VERSION ""

NS_ :

BS_:

BU_: MPC
VAL_TABLE_ Vt_The_Drv_Demand_Trq_Sign_S 1 "Driver Override" 0 "No Override" ;
VAL_TABLE_ Sun_Sensor_Hardware_Fault_S 1 "有故障" 0 "无故障" ;
VAL_TABLE_ Humidity_Sensor_Fault_Sign_S 1 "有故障" 0 "无故障" ;
VAL_TABLE_ Left_Front_Door_Status_294_S 3 "预留" 2 "打开" 1 "关闭" 0 "无效" ;
VAL_TABLE_ Right_Front_Door_Status_294_S 3 "预留" 2 "打开" 1 "关闭" 0 "无效" ;
VAL_TABLE_ Left_Back_Door_Status_294_S 3 "预留" 2 "打开" 1 "关闭" 0 "无效" ;
VAL_TABLE_ Right_Back_Door_Status_294_S 3 "预留" 2 "打开" 1 "关闭" 0 "无效" ;
VAL_TABLE_ LeftF_Door_Stats_Valid_Bit_S 1 "无效" 0 "有效" ;
VAL_TABLE_ RightF_Door_Sts_Valid_Bit_294_S 1 "无效" 0 "有效" ;
VAL_TABLE_ LeftR_Door_Stats_Valid_Bit_S 1 "无效" 0 "有效" ;
VAL_TABLE_ RightR_Door_Sts_Valid_Bit_294_S 1 "无效" 0 "有效" ;
VAL_TABLE_ Driver_Belt_Stat_Effective_Bit_S 1 "无效" 0 "有效" ;
VAL_TABLE_ Back_Door_Sts_Effectiv_Bit_294_S 1 "无效" 0 "有效" ;
VAL_TABLE_ Frnt_Hatch_Stat_Effective_Bit_S 1 "无效" 0 "有效" ;
VAL_TABLE_ Emergency_Alarm_Effective_Bit_S 1 "无效" 0 "有效" ;
VAL_TABLE_ Driver_Belt_Status_S 3 "预留" 2 "扣上" 1 "解开" 0 "无效" ;
VAL_TABLE_ Back_Door_Status_294_S 3 "预留" 2 "打开" 1 "关闭" 0 "无效" ;
VAL_TABLE_ Former_Hatch_Status_294_S 3 "预留" 2 "打开" 1 "关闭" 0 "无效" ;
VAL_TABLE_ Emergency_Alarm_Status_S 3 "预留" 2 "打开" 1 "关闭" 0 "无效" ;
VAL_TABLE_ Shift_Positions_294_S 3 "预留" 2 "N" 1 "R" 0 "Invalid" ;
VAL_TABLE_ Brake_Pedal_Statuslevel_S 3 "Error" 2 "浅踩制动踏板" 1 "深踩制动踏板" 0 "Not Pressed" ;
VAL_TABLE_ Clutch_Pedal_Status_294_S 3 "预留" 2 "Pressed" 1 "Not Pressed" 0 "无效" ;
VAL_TABLE_ Trump_Relay_Status_294_S 3 "预留" 2 "断开" 1 "吸合" 0 "无效" ;
VAL_TABLE_ Self_Learning_Trigger_Command_S 3 "预留" 2 "预留" 1 "触发自学习" 0 "无效" ;
VAL_TABLE_ LBCM_Platform_S 4 "L4" 3 "L3" 2 "L2" 1 "L1" 0 "无效" ;
VAL_TABLE_ LBCM_Configuration_Result_S 3 "配置中" 2 "已配置" 1 "未配置或配置失败" 0 "无效" ;
VAL_TABLE_ Req_Key_Position_Outside_Car_S 1 "请求车外钥匙位置" 0 "无效" ;
VAL_TABLE_ Lowp_Relay_294_S 8 "空转" 7 "堵转" 6 "短路" 5 "开路" 4 "通讯失败" 3 "打开" 2 "关闭" 1 "无此功能" 0 "无效" ;
VAL_TABLE_ Loolant_Pump_Relay_294_S 8 "空转" 7 "堵转" 6 "短路" 5 "开路" 4 "通讯失败" 3 "打开" 2 "关闭" 1 "无此功能" 0 "无效" ;
VAL_TABLE_ SGS_Power_Status_S 3 "预留" 2 "断电状态        " 1 "供电状态     " 0 "无效" ;
VAL_TABLE_ IG3_Break_Requirement_S 1 "有效" 0 "无效" ;
VAL_TABLE_ ACC_Relay_Status_S 3 "预留" 2 "吸合" 1 "断开" 0 "无效" ;
VAL_TABLE_ IG1_Relay_Status_S 3 "预留" 2 "吸合" 1 "断开" 0 "无效" ;
VAL_TABLE_ IG2_Relay_Status_S 3 "预留" 2 "吸合" 1 "断开" 0 "无效" ;
VAL_TABLE_ IG3_Relay_Status_S 3 "预留" 2 "吸合" 1 "断开" 0 "无效" ;
VAL_TABLE_ IG4_Relay_Status_S 3 "预留" 2 "吸合" 1 "断开" 0 "无效" ;
VAL_TABLE_ Sta_Egne_Intlgc_Charg_Stat_12D_S 3 "智能充电中" 2 "智能熄火" 1 "智能启动" 0 "无效" ;
VAL_TABLE_ Vehicle_Status_Safe_S 2 "启动安全系统状态" 1 "设定安全系统状态" 0 "正常系统状态" ;
VAL_TABLE_ Smart_Charge_Reqm_S 3 "预留" 2 "退出智能充电请求" 1 "进入智能充电请求" 0 "无效" ;
VAL_TABLE_ BCM_Off_Chrg_Contct_Rqst_Cmd_S 1 "请求断开" 0 "无效" ;
VAL_TABLE_ Prohibit_Power_On_State_S 1 "禁止" 0 "无效" ;
VAL_TABLE_ BCMVechile_Status_S 7 "高温杀菌状态" 6 "蓝牙启动状态" 5 "启动等待过程中按下启动按钮" 4 "智能充电状态" 3 "遥控启动状态" 2 "非远程启动状态" 1 "远程启动状态" 0 "无效" ;
VAL_TABLE_ Strtg_Mchne_Relay_Status_S 3 "预留" 2 "Connect" 1 "Break" 0 "预留" ;
VAL_TABLE_ Gateway_Engine_Stop_Inform_12D_S 1 "退电" 0 "无效" ;
VAL_TABLE_ Gateway_Starter_Command12D_S 1 "Startup" 0 "Not Startup" ;
VAL_TABLE_ Background_High_Voltage_S 3 "预留" 2 "退出后台高压" 1 "后台上高压请求" 0 "无效" ;
VAL_TABLE_ BCMPower_Gear_12D_S 3 "ON档" 2 "ACC档" 1 "OFF档" 0 "无效" ;
VAL_TABLE_ Vehicle_Status_Security_S 2 "防盗状态" 1 "防盗设定状态" 0 "正常状态" ;
VAL_TABLE_ Key_Psttion_Request_Signal_S 3 "退电请求钥匙位置" 2 "请求钥匙位置" 1 "不请求钥匙位置" 0 "无效" ;
VAL_TABLE_ Smart_PowerOn_Request_S 3 "上高压输出动力(OK)" 2 "上高压不输出动力(伪OK)" 1 "关闭高压" 0 "无效" ;
VAL_TABLE_ Configure_Alcohol_Lock_S 1 "无效" 0 "已配置酒精锁装置" ;
VAL_TABLE_ Alcohol_Monitoring_Result_S 1 "酒精检测通过" 0 "酒精检测不通过" ;
VAL_TABLE_ Elec_Cool_Water_Pump_Sts_12D_S 3 "预留" 2 "开启" 1 "关闭" 0 "预留" ;
VAL_TABLE_ Cool_Water_Pump_Fail_Sts_12D_S 3 "预留" 2 "堵转" 1 "断路" 0 "短路" ;
VAL_TABLE_ Back_Door_Switch_In_Cockpit475_S 3 "长按(预留)" 2 "长抬" 1 "短抬/短按" 0 "无效" ;
VAL_TABLE_ Rmt_Ctrl_Backdoor_Swit_Sig475_S 3 "预留" 2 "长按或双击遥控后背门" 1 "短按遥控后背门" 0 "无效" ;
VAL_TABLE_ Charg_Port_Power_Lock_Mode_475_S 3 "启用防盗充满电可解锁" 2 "停用防盗" 1 "启用防盗" 0 "无效" ;
VAL_TABLE_ Charge_Gun_Lock_Stats_475_S 3 "预留" 2 "闭锁状态" 1 "解锁状态" 0 "无效" ;
VAL_TABLE_ Remote_Unlock_Back_Door_Cmd475_S 1 "遥控后背门" 0 "无效" ;
VAL_TABLE_ Charg_Port_Lck_Pfrmg_Fdbk_475_S 4 "闭锁失败" 3 "闭锁成功" 2 "开锁失败" 1 "开锁成功" 0 "无效" ;
VAL_TABLE_ Elctrc_Charge_Cmmnd_Sltns_S 3 "预留" 2 "电锁闭锁" 1 "电锁解锁" 0 "无效" ;
VAL_TABLE_ Phone_Trunk_Open_Instruct475_S 3 "悬停" 2 "关闭" 1 "打开" 0 "无效" ;
VAL_TABLE_ Left_Child_Lock_Pos_Info_S 3 "预留" 2 "解锁" 1 "闭锁" 0 "无效" ;
VAL_TABLE_ RR_Child_Lcks_Win_Lcks_S 3 "预留" 2 "解锁" 1 "闭锁" 0 "无效" ;
VAL_TABLE_ BCM_Fwiper_Servic_Pos_Func_S 3 "不允许检修" 2 "关闭" 1 "打开" 0 "无效" ;
VAL_TABLE_ BCM_Aft_Wiper_Service_Bit_Func_S 3 "不允许检修" 2 "关闭" 1 "打开" 0 "无效" ;
VAL_TABLE_ Auto_Wiper_Setting_S 1 "有自动雨刮" 0 "无效" ;
VAL_TABLE_ Front_Wash_Control_Signal_S 1 "有效" 0 "无效" ;
VAL_TABLE_ Wiper_Speed_S 3 "快刮" 2 "慢刮" 1 "停止" 0 "无效" ;
VAL_TABLE_ Rear_Wash_Control_Signal_S 1 "有效" 0 "无效" ;
VAL_TABLE_ Allow_Unlock_Outer_Door_Sw_S 1 "有效" 0 "无效" ;
VAL_TABLE_ Key_Forgotten_Unlock_Luggage_S 1 "打开" 0 "无效" ;
VAL_TABLE_ Front_Washing_Work_Status_475_S 1 "工作状态" 0 "非工作状态" ;
VAL_TABLE_ Rear_Washing_Work_Status_475_S 1 "工作状态" 0 "非工作状态" ;
VAL_TABLE_ Rainy_Day_Clo_Windw_Order_475_S 1 "无效" 0 "有效" ;
VAL_TABLE_ LR_Child_Lcks_Win_Lcks_S 3 "预留" 2 "解锁" 1 "闭锁" 0 "无效" ;
VAL_TABLE_ Right_Childlock_Unlock_Sts_475_S 3 "预留" 2 "右儿童锁解锁状态" 1 "右儿童锁闭锁状态" 0 "无效" ;
VAL_TABLE_ Left_Front_Door_Lock_Cmd_Slts_S 3 "预留" 2 "闭锁" 1 "解锁" 0 "无效" ;
VAL_TABLE_ Rear_Wiper_Speed_S 3 "慢刮" 2 "间歇刮" 1 "停止" 0 "无效" ;
VAL_TABLE_ Front_Hatch_In_Vehicle_Switch_S 3 "长按(预留)" 2 "长抬" 1 "短抬/短按" 0 "无效；" ;
VAL_TABLE_ Indirect_TMPS_Reset_Button_S 1 "按下" 0 "无效" ;
VAL_TABLE_ MDC_Pump_Status_S 3 "预留" 2 "开启" 1 "关闭" 0 "预留" ;
VAL_TABLE_ MDC_Water_Pump_Fault_Status_S 3 "预留" 2 "堵转" 1 "断路" 0 "短路" ;
VAL_TABLE_ Child_ID_3D9_S 1 "子ID01" ;
VAL_TABLE_ Please_Leave_Vehicle_Immd_Red_S 1 "故障" 0 "正常" ;
VAL_TABLE_ Remote_Ctrl_Drive_Suspe_Yellow_S 1 "故障" 0 "正常" ;
VAL_TABLE_ Please_Check_The_Brake_Sys_Red_S 1 "故障" 0 "正常" ;
VAL_TABLE_ Brake_Fluid_Level_Is_Low_Red_S 1 "故障" 0 "正常" ;
VAL_TABLE_ Please_Check_The_Steer_Sys_Red_S 1 "故障" 0 "正常" ;
VAL_TABLE_ Engine_Cool_Temp_Too_High1_Red_S 1 "故障" 0 "正常" ;
VAL_TABLE_ Engine_Cool_Temp_Too_High2_Red_S 1 "故障" 0 "正常" ;
VAL_TABLE_ Insufficient_Oil_Pressure_Red_S 1 "故障" 0 "正常" ;
VAL_TABLE_ Please_Check_The_Power_Sys_Red_S 1 "故障" 0 "正常" ;
VAL_TABLE_ LV_Power_Supply_Sys_Faulty_Red_S 1 "故障" 0 "正常" ;
VAL_TABLE_ Start_Type_Iron_Bat_Faulty_Red_S 1 "故障" 0 "正常" ;
VAL_TABLE_ Please_Check_Vehicle_Net_Red_S 1 "故障" 0 "正常" ;
VAL_TABLE_ Please_Check_Transmi_Sys1_Red_S 1 "故障" 0 "正常" ;
VAL_TABLE_ Please_Check_Transmis_Sys2_Red_S 1 "故障" 0 "正常" ;
VAL_TABLE_ Low_Battery_Limited_Power_Red_S 1 "故障" 0 "正常" ;
VAL_TABLE_ EV_Function_Is_Limited_Red_S 1 "故障" 0 "正常" ;
VAL_TABLE_ Exit_Smart_Driving_Mode_Red_S 1 "故障" 0 "正常" ;
VAL_TABLE_ Intelligent_Drive_Failure_Red_S 1 "故障" 0 "正常" ;
VAL_TABLE_ Please_Check_EPB_Red_S 1 "故障" 0 "正常" ;
VAL_TABLE_ Lack_Of_Park_Capacity_Yellow_S 1 "故障" 0 "正常" ;
VAL_TABLE_ Please_Check_LBMS_Red_S 1 "故障" 0 "正常" ;
VAL_TABLE_ Please_Check_LV_Sup_Sys_Red_S 1 "故障" 0 "正常" ;
VAL_TABLE_ Please_Check_Engine_System_Red_S 1 "故障" 0 "正常" ;
VAL_TABLE_ Eng_Accessories_Limited_Red_S 1 "故障" 0 "正常" ;
VAL_TABLE_ Transmis_Limited_in_Func_Red_S 1 "故障" 0 "正常" ;
VAL_TABLE_ High_Clutch_Temperature_Red_S 1 "故障" 0 "正常" ;
VAL_TABLE_ Gearbox_Oil_Temp_Too_High_Red_S 1 "故障" 0 "正常" ;
VAL_TABLE_ Please_Check_SRS_System_Red_S 1 "故障" 0 "正常" ;
VAL_TABLE_ Please_Check_ADB_System_Red_S 1 "故障" 0 "正常" ;
VAL_TABLE_ Please_Check_Power_Sys_Yellow_S 1 "故障" 0 "正常" ;
VAL_TABLE_ Check_Headlight_Sys_Yellow_S 1 "故障" 0 "正常" ;
VAL_TABLE_ Engine_Start_Failed_Red_S 1 "故障" 0 "正常" ;
VAL_TABLE_ Coolant_Liqui_Level_Low_Yellow_S 1 "故障" 0 "正常" ;
VAL_TABLE_ AC_Hot_Mana_Fail_Yellow_S 1 "故障" 0 "正常" ;
VAL_TABLE_ Oil_Level_Is_Too_Low_Yellow_S 1 "故障" 0 "正常" ;
VAL_TABLE_ Oil_Level_Is_Too_High_Yellow_S 1 "故障" 0 "正常" ;
VAL_TABLE_ Check_The_Oil_Monit_Sys_Yellow_S 1 "故障" 0 "正常" ;
VAL_TABLE_ Check_Tire_Pres_Mon_Sys_Yellow_S 1 "故障" 0 "正常" ;
VAL_TABLE_ Tire_Pressure_Is_Low_Yellow_S 1 "故障" 0 "正常" ;
VAL_TABLE_ Check_The_Brak_Sys_Yellow_S 1 "故障" 0 "正常" ;
VAL_TABLE_ Please_Check_ABS_Sys_Yellow_S 1 "故障" 0 "正常" ;
VAL_TABLE_ Check_Generation_Sys_Yellow_S 1 "故障" 0 "正常" ;
VAL_TABLE_ Please_Check_Gear_Sys_Yellow_S 1 "故障" 0 "正常" ;
VAL_TABLE_ Please_Check_ESP_Sys_Yellow_S 1 "故障" 0 "正常" ;
VAL_TABLE_ Please_Check_HDC_Sys_Yellow_S 1 "故障" 0 "正常" ;
VAL_TABLE_ Check_Brake_Plate_Yellow_S 1 "故障" 0 "正常" ;
VAL_TABLE_ Check_Video_Controller_Yellow_S 1 "故障" 0 "正常" ;
VAL_TABLE_ Check_FMRR_Yellow_S 1 "故障" 0 "正常" ;
VAL_TABLE_ AEB_Funct_Limit_Yellow_S 1 "故障" 0 "正常" ;
VAL_TABLE_ Check_Pred_Coll_Ala_Sys_Yellow_S 1 "故障" 0 "正常" ;
VAL_TABLE_ Check_Pedestri_Dete_Sys_Yellow_S 1 "故障" 0 "正常" ;
VAL_TABLE_ Limited_Lane_Keeping_Yellow_S 1 "故障" 0 "正常" ;
VAL_TABLE_ Limited_Adaptive_Cruise_Yellow_S 1 "故障" 0 "正常" ;
VAL_TABLE_ Limit_Lane_Departu_Func_Yellow_S 1 "故障" 0 "正常" ;
VAL_TABLE_ Limited_Blind_Spot_Moni_Yellow_S 1 "故障" 0 "正常" ;
VAL_TABLE_ Smart_Camera_Not_Availa_White_S 1 "故障" 0 "正常" ;
VAL_TABLE_ Insuff_Fuel_For_Ac_Heat_Yellow_S 1 "故障" 0 "正常" ;
VAL_TABLE_ Check_Discharge_Equip_Yellow_S 1 "故障" 0 "正常" ;
VAL_TABLE_ Check_Charg_Out_Equip_Yellow_S 1 "故障" 0 "正常" ;
VAL_TABLE_ Check_On_Board_char_Sys_Yellow_S 1 "故障" 0 "正常" ;
VAL_TABLE_ Low_Battery_Limit_Power_Yellow_S 1 "故障" 0 "正常" ;
VAL_TABLE_ Vehicle_Ent_For_Ev_Mode_Yellow_S 1 "故障" 0 "正常" ;
VAL_TABLE_ Please_Go_Byd_Serv_Shop_Yellow_S 1 "故障" 0 "正常" ;
VAL_TABLE_ GPF_Needs_Regeneration_S 1 "故障" 0 "正常" ;
VAL_TABLE_ Restricted_Drive_Function_Red_S 1 "故障" 0 "正常" ;
VAL_TABLE_ Please_Check_Connector_Yellow_S 1 "故障" 0 "正常" ;
VAL_TABLE_ Solenoid_Valve_Clean_Whiite_S 1 "故障" 0 "正常" ;
VAL_TABLE_ Gearbox_Adapting_Whiite_S 1 "故障" 0 "正常" ;
VAL_TABLE_ Exter_Dischrg_Funct_Off_Yellow_S 1 "故障" 0 "正常" ;
VAL_TABLE_ Please_Stop_Discharging_Yellow_S 1 "故障" 0 "正常" ;
VAL_TABLE_ Charg_Port_Cover_Not_Cls_White_S 1 "故障" 0 "正常" ;
VAL_TABLE_ Switch_To_P_Range_Yellow_S 1 "故障" 0 "正常" ;
VAL_TABLE_ Please_Charge_In_Time_Yellow_S 1 "故障" 0 "正常" ;
VAL_TABLE_ Parking_Brake_Not_Relea_Yellow_S 1 "故障" 0 "正常" ;
VAL_TABLE_ EPB_Is_Not_Released_Yellow_S 1 "故障" 0 "正常" ;
VAL_TABLE_ Please_Add_Fuel_Yellow_S 1 "故障" 0 "正常" ;
VAL_TABLE_ APA_Function_Limit_White_S 1 "故障" 0 "正常" ;
VAL_TABLE_ Check_Mot_Pret_Belt_Sys_Yellow_S 1 "故障" 0 "正常" ;
VAL_TABLE_ Please_Check_Memory_Sys_Yellow_S 1 "故障" 0 "正常" ;
VAL_TABLE_ Please_Check_Sunroo_Sys_Yellow_S 1 "故障" 0 "正常" ;
VAL_TABLE_ Ensu_Inte_Tem_Ctrl_Effe_Yellow_S 1 "故障" 0 "正常" ;
VAL_TABLE_ Low_Power_Batt_Ac_Limit_Yellow_S 1 "故障" 0 "正常" ;
VAL_TABLE_ Low_Power_Batt_Limi_Pow_Yellow_S 1 "故障" 0 "正常" ;
VAL_TABLE_ Will_Acc_Brake_Pad_Wear_Yellow_S 1 "故障" 0 "正常" ;
VAL_TABLE_ Day_Before_Key_Fun_Fail_Yellow_S 0 "正常/不显示" ;
VAL_TABLE_ Hour_Befor_Key_Fun_Fail_Yellow_S 0 "正常/不显示" ;
VAL_TABLE_ ADAS_Functions_Are_Limited_S 1 "故障" 0 "正常" ;
VAL_TABLE_ Emergency_Braking_S 1 "故障" 0 "正常" ;
VAL_TABLE_ Please_Brake_S 1 "故障" 0 "正常" ;
VAL_TABLE_ Headlight_Fail_Warn_Light_3D9_S 1 "故障" 0 "正常" ;
VAL_TABLE_ Oil_Pressur_Low_Indicat_Light_S 1 "点亮" 0 "熄灭" ;
VAL_TABLE_ Brake_System_Fault_Indicator_S 1 "点亮" 0 "熄灭" ;
VAL_TABLE_ LV_Power_Supply_Sys_Fault_Lamp_S 1 "点亮" 0 "熄灭" ;
VAL_TABLE_ Engine_Fault_Indicaor_Light_S 1 "点亮" 0 "熄灭" ;
VAL_TABLE_ ABS_Sys_Fault_Indicaor_Light_S 1 "点亮" 0 "熄灭" ;
VAL_TABLE_ ESP_Fault_Warning_Light_3D9_S 1 "点亮" 0 "熄灭" ;
VAL_TABLE_ Rapid_Leak_Indicaor_Light_S 1 "点亮" 0 "熄灭" ;
VAL_TABLE_ GPF_Need_Regenerat_Fault_Light_S 1 "点亮" 0 "熄灭" ;
VAL_TABLE_ Elec_Park_Fault_Indicaor_Light_S 1 "点亮" 0 "熄灭" ;
VAL_TABLE_ SRS_Fault_Indicator_3D9_S 1 "点亮" 0 "熄灭" ;
VAL_TABLE_ EPS_Indicaor_Light_S 1 "点亮" 0 "熄灭" ;
VAL_TABLE_ Tire_Pres_Falt_Warn_Indi_Light_S 1 "点亮" 0 "熄灭" ;
VAL_TABLE_ Security_Indicator_S 1 "点亮" 0 "熄灭" ;
VAL_TABLE_ Motor_Temp_Too_High_Indicator_S 1 "点亮" 0 "熄灭" ;
VAL_TABLE_ Battery_Failure_Warn_Light_3D9_S 1 "点亮" 0 "熄灭" ;
VAL_TABLE_ Warn_Lamp_Exces_Power_Bat_Temp_S 1 "点亮" 0 "熄灭" ;
VAL_TABLE_ Power_Sys_Fail_Warn_Light_3D9_S 1 "点亮" 0 "熄灭" ;
VAL_TABLE_ OK_Indicator_S 1 "点亮" 0 "熄灭" ;
VAL_TABLE_ Driver_Seat_Belt_Indicator_3D9_S 1 "点亮" 0 "熄灭" ;
VAL_TABLE_ ADB_Fault_Indicator_3D9_S 1 "点亮" 0 "熄灭" ;
VAL_TABLE_ Auto_Emerge_Stop_Indicator_3D9_S 1 "点亮" 0 "熄灭" ;
VAL_TABLE_ Low_Power_Battery_Warn_Light_S 1 "点亮" 0 "熄灭" ;
VAL_TABLE_ Drive_Power_Limit_Indicator_S 1 "点亮" 0 "熄灭" ;
VAL_TABLE_ Itlgt_Key_Sys_Wrng_Light_3D9_S 1 "点亮" 0 "熄灭" ;
VAL_TABLE_ ACC_Fault_Warn_Light_S 1 "点亮" 0 "熄灭" ;
VAL_TABLE_ Coolant_Temp_Warn_Light_3D9_S 1 "点亮" 0 "熄灭" ;
VAL_TABLE_ Low_Fuel_Warning_Light_3D9_S 1 "点亮" 0 "熄灭" ;
VAL_TABLE_ Main_Warning_Light_3D9_S 1 "点亮" 0 "熄灭" ;
VAL_TABLE_ Valid_Mileage_S 1 "无效" 0 "有效" ;
VAL_TABLE_ Power_Consu_Curve_Dot_Mark_3D9_S 1 "打点" 0 "无效" ;
VAL_TABLE_ Fuel_Consu_Curve_Dot_Mark_3D9_S 1 "打点" 0 "无效" ;
VAL_TABLE_ Low_Energy_State_Flag_S 3 "油电均低" 2 "电量低          " 1 "油位低  " 0 "无效          " ;
VAL_TABLE_ Meter_Export_Area_S 9 "英国版" 8 "台湾版" 7 "香港版" ;
VAL_TABLE_ Fuel_Consumption_Unit_4A5_S 3 "预留" 2 "Gal" 1 "L" 0 "无效" ;
VAL_TABLE_ Power_Consumption_Unit_4A5_S 4 "HP·h/100miles" 3 "HP·h/100km" 2 "kW·h/100miles" 1 "kW·h/100km" 0 "无效" ;
VAL_TABLE_ Instan_Fuel_Consu_Unit_Set_4A5_S 4 "L/h" 3 "mpg" 2 "km/L" 1 "L/100Km" 0 "无效" ;
VAL_TABLE_ Tachometer_Display_S 3 "预留" 2 "不显示" 1 "显示" 0 "无效" ;
VAL_TABLE_ Mileage_Unit_4A5_S 3 "预留" 2 "mile" 1 "km" 0 "无效" ;
VAL_TABLE_ Speedmeter_Self_Check_Anim_4A5_S 1 "车速表自检动画" 0 "无效" ;
VAL_TABLE_ Fuel_Gauge_Self_Check_Anim_4A5_S 1 "燃油表自检动画" 0 "无效" ;
VAL_TABLE_ Water_Temp_Self_Check_Anim_4A5_S 1 "水温表自检动画" 0 "无效" ;
VAL_TABLE_ Tachmeter_Self_Check_Anim_4A5_S 1 "转速表自检动画" 0 "无效" ;
VAL_TABLE_ Powe_Meter_Self_Check_Anim_4A5_S 1 "功率表自检动画" 0 "无效" ;
VAL_TABLE_ Orientation_Info_4A5_S 8 "西北" 7 "西" 6 "西南" 5 "南" 4 "东南" 3 "东" 2 "东北" 1 "北" 0 "无效" ;
VAL_TABLE_ Mileage_Unit_4A5s03_S 3 "预留" 2 "mile" 1 "km" 0 "无效" ;
VAL_TABLE_ Temperature_Unit_4A5_S_S 1 "华氏设定温度" 0 "摄氏设定温度" ;
VAL_TABLE_ Mileage_Unit_4A5s04_S 3 "预留" 2 "mile" 1 "km" 0 "无效" ;
VAL_TABLE_ Tire_Pressure_Body_Type_4A5_S 3 "间接式，无车体" 2 "间接式，有车体" 1 "直接式" 0 "无效" ;
VAL_TABLE_ Power_Consumption_Unit_4A5s05_S 4 "HP·h/100miles" 3 "HP·h/100km" 2 "kW·h/100miles" 1 "kW·h/100km" 0 "无效" ;
VAL_TABLE_ Dial_Alarm_4A5_S 1 "不报警" 0 "报警" ;
VAL_TABLE_ Speed_Unit_Setting_4A5_S 3 "预留" 2 "MPH" 1 "Km/h" 0 "无效" ;
VAL_TABLE_ Mileage_Unit_4A5s05_S 3 "预留" 2 "mile" 1 "km" 0 "无效" ;
VAL_TABLE_ Pressure_Unit_4A5_S 3 "kpa" 2 "psi" 1 "bar" 0 "无效" ;
VAL_TABLE_ FL_Tire_Pressure_Sts_Indirect_S 1 "故障" 0 "正常" ;
VAL_TABLE_ FR_Tire_Pressure_Sts_Indirect_S 1 "故障" 0 "正常" ;
VAL_TABLE_ RL_Tire_Pressure_Sts_Indirect_S 1 "故障" 0 "正常" ;
VAL_TABLE_ RR_Tire_Pressure_Sts_Indirect_S 1 "故障" 0 "正常" ;
VAL_TABLE_ Ave_Fuel_Consumpt_Unit_Set_4A5_S 4 "mpg(US)" 3 "mpg(GB)" 2 "km/L" 1 "L/100Km" 0 "无效" ;
VAL_TABLE_ Low_Fuel_Alarm_4A5_S 1 "不报警" 0 "报警" ;
VAL_TABLE_ Power_Unit_4A5_S 3 "预留" 2 "HP" 1 "kWh" 0 "无效" ;
VAL_TABLE_ AC_Heater_Oil_Quan_Display_4A5_S 6 "预留" 5 "5格" 4 "4格" 3 "3格" 2 "2格" 1 "1格" 0 "0%油量" ;
VAL_TABLE_ AC_Heater_Oil_Lev_Indi_4A5_S 7 "4HZ闪烁" 6 "2HZ闪烁" 5 "1HZ闪烁" 4 "0.5HZ闪烁" 3 "0.25HZ闪烁" 2 "熄灭" 1 "点亮" 0 "无效" ;
VAL_TABLE_ AC_Heater_Oil_Indi_Color_4A5_S 5 "蓝色" 4 "绿色" 3 "红色" 2 "黄色" 1 "白色" 0 "无效" ;
VAL_TABLE_ AC_Heater_Oil_Meter_Alarm_4A5_S 3 "预留" 2 "报警" 1 "正常" 0 "无效" ;
VAL_TABLE_ Water_Temperature_Alarm_4A5_S 1 "报警" 0 "不报警" ;
VAL_TABLE_ Left_Front_Tire_Color_4A5_S 3 "红" 2 "黄" 1 "白（正常）" 0 "无效" ;
VAL_TABLE_ Right_Front_Tire_Color_4A5_S 3 "红" 2 "黄" 1 "白（正常）" 0 "无效" ;
VAL_TABLE_ Left_Rear_Tire_Color_4A5_S 3 "红" 2 "黄" 1 "白（正常）" 0 "无效" ;
VAL_TABLE_ Right_Rear_Tire_Color_4A5_S 3 "红" 2 "黄" 1 "白（正常）" 0 "无效" ;
VAL_TABLE_ FL_Tire_Temperature_Color_4A5_S 3 "红" 2 "黄" 1 "白（正常）" 0 "无效" ;
VAL_TABLE_ Temperature_Unit_4A5s0A_S 1 "华氏设定温度" 0 "摄氏设定温度" ;
VAL_TABLE_ FR_Tire_Temperature_Color_4A5_S 3 "红" 2 "黄" 1 "白（正常）" 0 "无效" ;
VAL_TABLE_ RL_Tire_Temperature_Color_4A5_S 3 "红" 2 "黄" 1 "白（正常）" 0 "无效" ;
VAL_TABLE_ RR_Tire_Temperature_Color_4A5_S 3 "红" 2 "黄" 1 "白（正常）" 0 "无效" ;
VAL_TABLE_ This_Journey_Interface_4A5_S 3 "预留" 2 "不显示" 1 "显示" 0 "无效" ;
VAL_TABLE_ Theme_Mode_4A5_S 5 "浅色模式" 4 "深色模式" 3 "主题三" 2 "主题二" 1 "主题一" 0 "无效" ;
VAL_TABLE_ Mileage_Unit_4A5s0B_S 3 "预留" 2 "mile" 1 "km" 0 "无效" ;
VAL_TABLE_ Electricity_Consumption_Unit_S 3 "预留" 2 "HP.h" 1 "kW?h" 0 "无效" ;
VAL_TABLE_ Speed_Unit_Setting_151_S 3 "预留" 2 "MPH" 1 "Km/h" 0 "无效" ;
VAL_TABLE_ Charging_Display_Interface_323_S 7 "预约倒计时界面" 6 "预约充电时间设置界面" 5 "充电暂停中" 4 "充电结束" 3 "正在充电" 2 "充电连接中" 1 "不显示" 0 "无效" ;
VAL_TABLE_ Reservation_Time_Setting_323_S 3 "预留" 2 "分钟" 1 "时钟" 0 "无效" ;
VAL_TABLE_ INS_Show_Fault_323_S 1 "故障" 0 "正常" ;
VAL_TABLE_ Tips_323_S 13 "为保证动力电池智能温控效果，空调功能受限" 12 "电池加热中" 11 "保底充电中" 10 "超24H预约不生效" 9 "智能温控" 8 "电池温度低电亮高" 7 "充电枪未闭锁" 6 "限功率充电" 5 "充电负功率" 4 "充电插座接地不良" 3 "预约充电不允许" 2 "预约充电" 1 "不显示" 0 "无效" ;
VAL_TABLE_ Expected_Full_Time_323_S 3 "不显示" 2 "剩余时间" 1 "正在计算中" 0 "无效" ;
VAL_TABLE_ AC_Request_S 1 "启动" 0 "停止" ;
VAL_TABLE_ AC_Manual_Control_Sign_S 1 "手动控制" 0 "自动控制" ;
VAL_TABLE_ Mode_Manual_Control_Sign_S 1 "手动控制" 0 "自动控制" ;
VAL_TABLE_ Air_Volume_Manual_Control_Sign_S 1 "手动控制" 0 "自动控制" ;
VAL_TABLE_ Heat_Pump_Compressor_Work_Mod_S 3 "乘员舱采暖模式" 2 "乘员舱制冷模式" 1 "乘员舱无压缩机需求" 0 "无效" ;
VAL_TABLE_ ACHMC_AC_On_Status_S 3 "预留" 2 "关闭" 1 "打开" 0 "无效" ;
VAL_TABLE_ AC_Ctrl_Way_S 3 "预留" 2 "自动" 1 "手动" 0 "无效" ;
VAL_TABLE_ AC_Cycle_Mode_404_S 3 "预留" 2 "内循环" 1 "外循环" 0 "无效" ;
VAL_TABLE_ IKEY_Before_Defrosting_S 3 "预留" 2 "开启" 1 "关闭" 0 "无效" ;
VAL_TABLE_ AC_Wind_Model_404_S 7 "吹面+除霜" 6 "吹面+吹脚+除霜" 5 "除霜" 4 "吹脚+除霜" 3 "吹脚" 2 "吹面+吹脚" 1 "吹面" 0 "无效" ;
VAL_TABLE_ Air_Conditioning_Wind_Gear_S 7 "Level7" 6 "Level6" 5 "Level5" 4 "Level4" 3 "Level3" 2 "Level2" 1 "Level1" 0 "不出风" ;
VAL_TABLE_ AC_Pwroff_And_Ventilation_Fb_S 3 "预留" 2 "关闭" 1 "开启" 0 "无效" ;
VAL_TABLE_ Temperature_Each_Control_S 3 "单温区" 2 "双温区-独立控制（分控）" 1 "双温区-联合控制(不分控)" 0 "无效" ;
VAL_TABLE_ Temperature_Conversion_S 1 "华氏设定温度" 0 "摄氏设定温度" ;
VAL_TABLE_ Fault_Code_Model_S 3 "预留" 2 "显示" 1 "不显示" 0 "无效" ;
VAL_TABLE_ Ele_Park_Brake_Switch_Status_S 3 "Reserved" 2 "Apply" 1 "Release" 0 "Not Active" ;
VAL_TABLE_ EPB_Swi_Stat_Valid_S 1 "Invalid" 0 "Valid" ;
VAL_TABLE_ Ele_Park_Brake_Sys_Sta_Ind_Req_S 3 "FlashRate2Indication" 2 "FlashRate1Indication" 1 "ContinuousIndication" 0 "NoIndication" ;
VAL_TABLE_ Ele_Park_Brake_Sys_Dis_Mes_Req_S 7 "Message#7（驻车力不足）" 6 "Message#6（请切换至非P挡域释放电子驻车）" 5 "Message#5(电子驻车已解除)" 4 "Message#4(电子驻车已启动)" 3 "Message#3(请检查电子驻车系统)符合条件持续显示" 2 "Message#2(请释放电子驻车)" 1 "Message#1（请踩刹车踏板解除电子驻车)" 0 "Off" ;
VAL_TABLE_ EPB_TMMCtrlCmd_S 1 "RequesttoopenTMMcoupling??" 0 "Norequest?" ;
VAL_TABLE_ EPB_Status_S 5 "维修释放状态" 4 "Fault（禁止遥控驾驶）" 3 "Applied" 2 "Applying" 1 "Released" 0 "Releasing" ;
VAL_TABLE_ Ele_Park_Brake_Sys_War_Ind_Req_S 3 "FlashRate#2Indication" 2 "FlashRate#1Indication" 1 "ContinuousIndication" 0 "NoIndication" ;
VAL_TABLE_ Ele_Park_Brake_Sys_Aud_War_Req_S 3 "Reserved" 2 "Warning#2" 1 "Warning#1" 0 "Off" ;
VAL_TABLE_ EPB_Sys_Brake_Light_Req_S 1 "True" 0 "False" ;
VAL_TABLE_ EPB_Cru_Con_Canc_Req_S 1 "True" 0 "False" ;
VAL_TABLE_ DrvOrOthFcnReqEPBOverride_S 1 "True" 0 "False" ;
VAL_TABLE_ Step_On_Brake_To_Rel_PB_Ind_On_S 1 "True" 0 "False" ;
VAL_TABLE_ EPB_Maintenance_Mode_Status_S 1 "正常模式 " 0 "维修释放 " ;
VAL_TABLE_ EPB_Com_EPB_Aut_Braking_Req_S 1 "True" 0 "False" ;
VAL_TABLE_ EPB_Manufacturer_S 3 "预留" 2 "博世" 1 "十六部" 0 "万都" ;
VAL_TABLE_ EPB_Current_Drive_Mode_Fedback_S 3 "展车模式" 2 "自动驾驶模式" 1 "正常驾驶模式" 0 "无效" ;
VAL_TABLE_ ESP_Switch_Status_385_S 3 "预留" 2 "开启" 1 "关闭" 0 "无效" ;
VAL_TABLE_ AVH_button_S 3 "预留" 2 "关" 1 "开" 0 "无效" ;
VAL_TABLE_ Brake_Assist_Mode_Switch_S 3 "预留" 2 "Comfortable（舒适）" 1 "Standard（标准）默认模式" 0 "无效" ;
VAL_TABLE_ RCTA_Enable_S 3 "Reserved" 2 "Switchon" 1 "Switchoff" 0 "Invalid" ;
VAL_TABLE_ RCW_Enable_S 3 "Reserved" 2 "Switchon" 1 "Switchoff" 0 "Invalid" ;
VAL_TABLE_ DOW_Enable_S 3 "Reserved" 2 "Switchon" 1 "Switchoff" 0 "Invalid" ;
VAL_TABLE_ TJA_ICAwitch_S 3 "Reserved" 2 "Switchon" 1 "Switchoff" 0 "Invalid" ;
VAL_TABLE_ HDC_Switch_S 3 "预留" 2 "关(HDC功能OFF)" 1 "开(HDC功能ON)" 0 "无效" ;
VAL_TABLE_ CST_Fuction_Switch_S 3 "预留" 2 "关(CST功能OFF)" 1 "开(CST功能ON)" 0 "无效" ;
VAL_TABLE_ APA_Enable_S 3 "Reserved" 2 "Switchon" 1 "Switchoff" 0 "Invalid" ;
VAL_TABLE_ SBCD_Enable_S 3 "Reserved" 2 "Switchon" 1 "Switchoff" 0 "Invalid" ;
VAL_TABLE_ RCTB_Enable_S 3 "Reserved" 2 "Switchon" 1 "Switchoff" 0 "Invalid" ;
VAL_TABLE_ HMA_funtion_Swch_Signal_S 3 "Reserved" 2 "HMAselected" 1 "HMAnotselected" 0 "Invalid" ;
VAL_TABLE_ ADAS_Sensitivity_Req_S 3 "Reserved" 2 "highSensitivity" 1 "lowSensitivity" 0 "Invalid" ;
VAL_TABLE_ PCW_Enable_S 3 "Reserved" 2 "Switchon" 1 "Switchoff" 0 "Invalid" ;
VAL_TABLE_ LKS_Enable_S 5 "车辆纠偏" 4 "全功能" 3 "车道保持" 2 "车道偏离" 1 "关闭" 0 "无效" ;
VAL_TABLE_ AEB_Enable_S 3 "Reserved" 2 "switchon" 1 "switchoff" 0 "Invalid" ;
VAL_TABLE_ LDW_Warning_Mode_S 3 "振动+声音" 2 "仅声音" 1 "仅振动" 0 "无效" ;
VAL_TABLE_ BSD_Enable_S 3 "Reserved" 2 "Switchon" 1 "Switchoff" 0 "Invalid" ;
VAL_TABLE_ BSD_Static_Calib_Instrct_S 1 "开始" 0 "无效" ;
VAL_TABLE_ LDW_Static_Calib_Instrct_S 1 "开始" 0 "无效" ;
VAL_TABLE_ TMPS_Reset_Button_S 1 "按下" 0 "无效" ;
VAL_TABLE_ Steering_Wheel_Heat_385_S 3 "预留" 2 "打开" 1 "关闭" 0 "无效" ;
VAL_TABLE_ Voice_Control_Flg_S 1 "有效" 0 "无效" ;
VAL_TABLE_ SDWReq_Switch_State_S 3 "Reserved" 2 "Switchon" 1 "Switchoff" 0 "Invalid" ;
VAL_TABLE_ DiSus_C_Working_Mode_Set_S 3 "预留" 2 "运动" 1 "舒适" ;
VAL_TABLE_ PCW_Level_Set_S 3 "Level 3 高" 2 "Level 2 中(默认选择)" 1 "Level 1 低" 0 "No Action" ;
VAL_TABLE_ LDW_Enable_S 3 "Reserved" 2 "车道偏离" 1 "关闭" 0 "无效" ;
VAL_TABLE_ SLA_SpdLimOffs_S 9 "Reserved" 8 "+5（MPH）" 7 "+3（MPH）" 5 "-5（MPH）" 4 "+10（KPH）" 3 "+5（KPH）" 2 "-5（KPH）" 1 "-10（KPH）" 0 "0" ;
VAL_TABLE_ IntelligentSpdLimitAlarm_OnOff_S 3 "Reserved" 2 "on" 1 "off" 0 "Invalid" ;
VAL_TABLE_ ELKA_Enable_S 3 "Reserved" 2 "Switchon" 1 "Switchoff" 0 "Invalid" ;
VAL_TABLE_ Date_Information_Year_2B6_S 0 "无效" ;
VAL_TABLE_ Date_Information_Month_2B6_S 0 "无效" ;
VAL_TABLE_ Date_Information_Day_2B6_S 0 "无效" ;
VAL_TABLE_ Time_2B6_S 3 "预留" 2 "24h" 1 "12h" 0 "无效" ;
VAL_TABLE_ Speed_Reminder_3E3_S 3 "预留" 2 "减" 1 "加" 0 "无效" ;
VAL_TABLE_ Winter_Limt_Speed_Remnd_3E3_S 3 "预留" 2 "减" 1 "加" 0 "无效" ;
VAL_TABLE_ Maintain_Time_3E3_S 3 "预留" 2 "减" 1 "加" 0 "无效" ;
VAL_TABLE_ Maintain_Distance_3E3_S 3 "预留" 2 "减" 1 "加" 0 "无效" ;
VAL_TABLE_ Media_Factory_Default_S 3 "预留" 2 "取消" 1 "确定" 0 "无效" ;
VAL_TABLE_ Back_Light_Automatic_3E3_S 3 "预留" 2 "关闭" 1 "打开" 0 "无效" ;
VAL_TABLE_ Distance_One_Reset_3E3_S 3 "预留" 2 "取消" 1 "确定" 0 "无效" ;
VAL_TABLE_ Distance_Two_Reset_3E3_S 3 "预留" 2 "取消" 1 "确定" 0 "无效" ;
VAL_TABLE_ Back_Lght_Manl_Gear_3E3_S 0 "无效" ;
VAL_TABLE_ INS_Set_Fact_Dfault_Mark_S 1 "确定" 0 "无效" ;
VAL_TABLE_ Veh_Set_Fact_Dfault_Flg_S 1 "确定" 0 "无效" ;
VAL_TABLE_ Driv_Set_Fact_Dfault_Flg_S 1 "确定" 0 "无效" ;
VAL_TABLE_ VPS_Work_Mode_S 3 "预留" 2 "关闭" 1 "开启（默认）" 0 "无效" ;
VAL_TABLE_ Indoor_Lighting_Time_3E3_S 4 "30S" 3 "15S（默认）" 2 "7.5S" 1 "OFF" 0 "无效" ;
VAL_TABLE_ ExMirr_Ft_light_Time_3E3_S 4 "30S" 3 "15S（默认）" 2 "7.5S" 1 "OFF" 0 "无效" ;
VAL_TABLE_ ACB_Set_Restore_Default_Logo_S 1 "确认" 0 "无效" ;
VAL_TABLE_ Charg_Set_Restr_Dflt_Flg_S 1 "确认" 0 "无效" ;
VAL_TABLE_ Window_Dor_Rsto_Dflt_Flg_S 1 "确认" 0 "无效" ;
VAL_TABLE_ Lock_Set_Restr_Dflt_Flg_S 1 "确认" 0 "无效" ;
VAL_TABLE_ Out_RMirror_Rsto_Dfault_S 1 "确认" 0 "无效" ;
VAL_TABLE_ ARetrn_St_Rsto_Dflt_Flg_S 1 "确认" 0 "无效" ;
VAL_TABLE_ Associated_Backlight_S 3 "预留" 2 "关闭" 1 "打开" 0 "无效" ;
VAL_TABLE_ AVAS_Audio_Options_3E3_S 4 "音源4（静谧）" 3 "音源3（舒适）" 2 "音源2（动感）" 1 "音源1（标准）" 0 "无效" ;
VAL_TABLE_ Atmslamp_Rsto_Deflt_Flg_3E3_S 1 "确认" 0 "无效" ;
VAL_TABLE_ Light_Set_Resto_Dflt_Flg_S 1 "确认" 0 "无效" ;
VAL_TABLE_ BckLight_Restr_Deflt_Flg_S 1 "确认" 0 "无效" ;
VAL_TABLE_ SfAsist_Restr_Dflt_Log_S 1 "确认" 0 "无效" ;
VAL_TABLE_ Drv_Asis_St_RstrDflt_Flg_S 1 "确认" 0 "无效" ;
VAL_TABLE_ Roa_Asis_St_RstrDflt_Flg_S 1 "确认" 0 "无效" ;
VAL_TABLE_ Balanc_Set_RstrDflt_Flg_S 1 "确认" 0 "无效" ;
VAL_TABLE_ SdFiel_St_RstrDflt_Flg_S 1 "确认" 0 "无效" ;
VAL_TABLE_ Clock_Set_RstrDflt_Flg_S 1 "确认" 0 "无效" ;
VAL_TABLE_ Lang_Inpt_St_RstrDflt_S 1 "确认" 0 "无效" ;
VAL_TABLE_ Unit_Set_Restre_Dflt_Flg_S 1 "确认" 0 "无效" ;
VAL_TABLE_ vehicle_Disch_Res_Default_Flag_S 1 "确认" 0 "无效" ;
VAL_TABLE_ Front_And_Rear_Fog_Lamp_Gear_S 3 "后雾灯档" 2 "全天候灯档" 1 "OFF档" 0 "无效" ;
VAL_TABLE_ Mileage_Switch_S 3 "预留" 2 "预留" 1 "里程开关按下" 0 "无效" ;
VAL_TABLE_ CS_Front_Wiper_Gear_S 10 "AUTO档（ST/STE的间隙档位更改为Auto档）" 9 "快刮" 8 "慢刮" 7 "间隙4档" 6 "间隙3档" 5 "间隙2档" 4 "间隙1档" 3 "点刮长按" 2 "点刮短按" 1 "OFF档" 0 "预留" ;
VAL_TABLE_ CS_Front_Wash_Switch_Signal_S 3 "洗涤手柄松开" 2 "长抬洗涤手柄" 1 "短抬洗涤手柄" 0 "无效" ;
VAL_TABLE_ Wiper_Config_S 1 "自动雨刮配置" 0 "手动雨刮配置" ;
VAL_TABLE_ CS_Steering_Postn_Adjust_Sign_S 5 "停止" 4 "向上调节" 3 "向前调节" 2 "向下调节" 1 "向后调节" 0 "无效" ;
VAL_TABLE_ CS_Auto_Wiper_Switch_S 3 "预留" 2 "自动雨刮功能关闭" 1 "自动雨刮功能开启" 0 "无效" ;
VAL_TABLE_ CS_Sensitivity_Level_S 4 "4级" 3 "3级" 2 "2级" 1 "1级" 0 "无效" ;
VAL_TABLE_ Light_Knob_Mechan_Gear_S 4 "近光灯档" 3 "小灯档" 2 "AUTO档" 1 "OFF档" 0 "无效" ;
VAL_TABLE_ High_Beam_Attendan_Lamp_Stall_S 3 "超车灯档" 2 "远光灯档" 1 "OFF档" 0 "无效" ;
VAL_TABLE_ Turn_Signal_Switch_S 5 "右转向长抬" 4 "右转向短抬" 3 "左转向长抬" 2 "左转向短抬" 1 "OFF档" 0 "无效" ;
VAL_TABLE_ Auto_Light_Config_S 1 "有自动灯光" 0 "无自动灯光" ;
VAL_TABLE_ Rear_Wiper_Wash_Gear_S 4 "洗涤ON-2" 3 "间歇刮" 2 "OFF档" 1 "洗涤ON-1" 0 "无效" ;
VAL_TABLE_ Rear_Wiper_Config_S 1 "无后雨刮" 0 "有后雨刮" ;
VAL_TABLE_ SWS_Dist_Set_S 4 "无效" 3 "四档（2.3s）" 2 "三档（1.9s）" 1 "二档（1.5s）" 0 "一档（1s）" ;
VAL_TABLE_ SWS_Speed_Set_S 4 "加速二档" 3 "加速一档" 2 "减速二档" 1 "减速一档" 0 "初始位置" ;
VAL_TABLE_ Dipilot_Switch_Signal_S 1 "开关按下" 0 "无效" ;
VAL_TABLE_ SWS_Cruise_Or_Speed_Limit_Mode_S 1 "巡航模式" 0 "限速模式" ;
VAL_TABLE_ SWS_Reset_Signal_S 1 "复位动作" 0 "初始位置" ;
VAL_TABLE_ SWS_Cruis_Swch_Fault_Stat_flg_S 1 "正常" 0 "无效" ;
VAL_TABLE_ SWS_Set_Signal_S 1 "SET开关按下" 0 "无效" ;
VAL_TABLE_ SWS_Dist_Switch_Signal_Down_S 1 "距离开关按下" 0 "无效" ;
VAL_TABLE_ SWS_Dist_Switch_Signal_Up_S 1 "距离开关加按下" 0 "无效" ;
VAL_TABLE_ SWS_Lane_Line_Assis_S 1 "开关按下" 0 "无动作" ;
VAL_TABLE_ Cruise_Switch_Operation_Mode_S 1 "无巡航按键" 0 "巡航按键在方向盘上" ;
VAL_TABLE_ ACC_Switch_Signal_S 1 "开关按下" 0 "无效" ;
VAL_TABLE_ Street_Mode_Command_S 4 "沙地" 3 "泥泞地面/车辙地" 2 "草地/砂砾地/雪地" 1 "普通模式（预留）" 0 "保持在线" ;
VAL_TABLE_ TrunkLid_OpenClose_Switch_S 3 "预留" 2 "尾门关闭" 1 "尾门打开" 0 "无效" ;
VAL_TABLE_ Reversing_Radar_Switch_Config_S 3 "预留" 2 "无" 1 "有" 0 "无效" ;
VAL_TABLE_ Lane_Departure_Key_S 1 "有效按下" 0 "无效" ;
VAL_TABLE_ ChangeLane_DeadZone_Montr_Key_S 1 "有效按下" 0 "无效" ;
VAL_TABLE_ Back_Radar_Key_S 1 "有效按下" 0 "无效" ;
VAL_TABLE_ Appointment_Charge_Key_S 1 "有效按下" 0 "无效" ;
VAL_TABLE_ Automatic_Parking_Key_S 1 "有效按下" 0 "无效" ;
VAL_TABLE_ EV_Key_S 3 "预留" 2 "长按强制EV模式有效" 1 "短按有效" 0 "无效" ;
VAL_TABLE_ Vehicle_Mode_Switch_S 1 "有效按下" 0 "无效" ;
VAL_TABLE_ SCPA_ECO_SPORT_Key_S 1 "有效按下" 0 "无效" ;
VAL_TABLE_ AUTO_HOLD_Key_S 1 "有效按下" 0 "无效" ;
VAL_TABLE_ ESP_OFF_Key_S 1 "有效按下" 0 "无效" ;
VAL_TABLE_ AbruptSlope_SlowDrop_Key_S 1 "有效按下" 0 "无效" ;
VAL_TABLE_ ECO_Key_S 1 "有效按下" 0 "无效" ;
VAL_TABLE_ SPORT_Key_S 1 "有效按下" 0 "无效" ;
VAL_TABLE_ Snowfield_Key_S 1 "有效按下" 0 "无效" ;
VAL_TABLE_ Feedback_Key_3B_S 1 "有效按下" 0 "无效" ;
VAL_TABLE_ ESP_Switch_Set_S 3 "预留" 2 "无" 1 "有" 0 "无效" ;
VAL_TABLE_ SCPA_Pilot_Seat_Vtilat_S 1 "有效按下" 0 "无效" ;
VAL_TABLE_ SCPA_Pilot_Seat_Heating_S 1 "有效按下" 0 "无效" ;
VAL_TABLE_ GroundMode_Normal_Key_S 1 "有效按下" 0 "无效" ;
VAL_TABLE_ GroundMode_Muddy_Key_S 1 "有效按下" 0 "无效" ;
VAL_TABLE_ GroundMode_Sand_Key_S 1 "有效按下" 0 "无效" ;
VAL_TABLE_ HEV_Key_S 1 "有效按下" 0 "无效" ;
VAL_TABLE_ RightSlidoorOpen_Key_S 3 "预留" 2 "长按有效" 1 "短按有效" 0 "无效" ;
VAL_TABLE_ RightSlidoorClose_Key_S 3 "预留" 2 "长按有效" 1 "短按有效" 0 "无效" ;
VAL_TABLE_ Mode_Button_S 3 "预留" 2 "模式-按键" 1 "模式+按键" 0 "无效" ;
VAL_TABLE_ Feedback_Key_5B_S 3 "预留" 2 "回馈-按键" 1 "回馈+按键" 0 "无效" ;
VAL_TABLE_ LeftSlideDoor_OpenClose_Sw_S 3 "预留" 2 "按压滑门后移有效" 1 "按压滑门前移有效" 0 "无效" ;
VAL_TABLE_ Front_Differential_S 1 "有效按下" 0 "无效" ;
VAL_TABLE_ Rear_Differential_S 1 "有效按下" 0 "无效" ;
VAL_TABLE_ RightSlideDoor_OpenClose_Sw_S 3 "预留" 2 "按压滑门后移有效" 1 "按压滑门前移有效" 0 "无效" ;
VAL_TABLE_ SuspensionAdj_Swl_S 3 "预留" 2 "模式降低按键" 1 "悬架升高按键" 0 "无效" ;
VAL_TABLE_ Engine_Rev_Error_S 1 "Error" 0 "No Error" ;
VAL_TABLE_ Ilde_Status_S 1 "Inilde" 0 "Not Inilde" ;
VAL_TABLE_ Speed_Error_Status_S 1 "Error" 0 "No Error" ;
VAL_TABLE_ Acc_Pedal_Postion_Error_signal_S 1 "Error " 0 "No Error " ;
VAL_TABLE_ Rev_Drag_Start_Cmd_S 1 "Invalid" 0 "Valid" ;
VAL_TABLE_ ECM_Engine_Status_S 7 "Fault(当检测不到发动机当前状态时)" 3 "Running" 2 "Reserved" 1 "Cranking" 0 "EngineStop" ;
VAL_TABLE_ ECM_Start_Permission_S 1 "Prohibit" 0 "Allow" ;
VAL_TABLE_ ECM_Start_Process_Fault_S 1 "Error" 0 "No Error" ;
VAL_TABLE_ ECM_Start_Overtime_S 3 "Reserved" 2 "starttimelimitreached" 1 "starttimelimitnotreached" 0 "Invalidation" ;
VAL_TABLE_ Slide_Fuel_Cut_Off_Sign_S 1 "Fuel Cutoff" 0 "Fuel Not Cutoff" ;
VAL_TABLE_ Clutch_Pedal_Pos_S 3 "Error" 2 "Reserved" 1 "Pressed" 0 "Not Pressed" ;
VAL_TABLE_ ECM_Brake_Pedal_State_S 3 "Error" 2 "pressedsignal2(浅踩制动踏板)" 1 "Pressedsignal1(深踩制动踏板)" 0 "Not Pressed" ;
VAL_TABLE_ ECM_AC_Compressor_State_S 1 "Compressor On" 0 "Compressor Off" ;
VAL_TABLE_ Target_Trq_Response_Sign_S 1 "Able" 0 "Unable" ;
VAL_TABLE_ Cawl_Prohibit_Order_S 1 "Active" 0 "Not Active" ;
VAL_TABLE_ Acc_Pedal_Postion_Valid_S 1 "Valid" 0 "Invalid" ;
VAL_TABLE_ Exceed_Flag_S 1 "Valid" 0 "Invalid" ;
VAL_TABLE_ Stop_Allow_S 3 "预留" 2 "不允许停机" 1 "停机允许" 0 "无效" ;
VAL_TABLE_ Power_System_Failure_S 3 "预留" 2 "动力系统状态故障" 1 "EV功能受限" 0 "动力系统状态正常" ;
VAL_TABLE_ VCU_Motor_Tempt_Stats_S 3 "预留" 2 "动力电机过温报警" 1 "预留" 0 "动力电机过温正常" ;
VAL_TABLE_ VCU_IPM_Radiator_Tempt_Stats_S 3 "预留" 2 "IPM散热器过温报警" 1 "预留" 0 "IPM散热器温度正常" ;
VAL_TABLE_ VCU_IGBT_Temperature_State_S 3 "预留" 2 "IGBT过温报警" 1 "预留" 0 "IGBT温度正常" ;
VAL_TABLE_ VCU_Collision_PWM_State_S 3 "预留" 2 "正常" 1 "异常" 0 "预留" ;
VAL_TABLE_ VCU_Collide_Signal_State_S 3 "预留" 2 "没有碰撞" 1 "发生碰撞" 0 "预留" ;
VAL_TABLE_ Unable_Enter_Stabilizatio_Flag_S 1 "有效" 0 "无效" ;
VAL_TABLE_ VCU_Voluntary_Release_State_S 3 "正在泄放" 2 "泄放超时" 1 "泄放完成" 0 "未泄放" ;
VAL_TABLE_ Acc_AntiMisstepTrigger_Mark_S 3 "保留" 2 "触发" 1 "未触发" 0 "保留" ;
VAL_TABLE_ Current_Status_240_S 1 "1" 0 "0" ;
VAL_TABLE_ Historical_Status_240_S 1 "1" 0 "0" ;
VAL_TABLE_ VCU_Goal_Road_Mode_S 4 "沙地" 3 "泥泞地面/车辙地" 2 "草地/砂砾地/雪地" 1 "普通模式" 0 "无效" ;
VAL_TABLE_ VCU_Practice_Road_Mode_S 4 "沙地" 3 "泥泞地面/车辙地" 2 "草地/砂砾地/雪地" 1 "普通模式" 0 "无效" ;
VAL_TABLE_ WadingFloating_Mode_Reserved_S 3 "预留（预留，仅SCH车型使用）" 2 "浮水模式" 1 "涉水模式 " 0 "普通模式 " ;
VAL_TABLE_ Power_Battery_Selfheat_Cmd_240_S 3 "预留" 2 "允许自加热" 1 "不允许自加热" 0 "无效" ;
VAL_TABLE_ PAD_Time_Delay_Powerback_240_S 3 "预留" 2 "不允许" 1 "允许" 0 "无效" ;
VAL_TABLE_ Charg_Cover_Inform_Prompt_240_S 3 "预留" 2 "提示" 1 "不提示" 0 "无效" ;
VAL_TABLE_ VCU_Startup_Allowed_S 1 "禁止启动" 0 "允许启动" ;
VAL_TABLE_ VCU_Startup_Overtime_S 3 "预留" 2 "启动超时" 1 "启动中，还没超时" 0 "无效" ;
VAL_TABLE_ VCU_Startup_Process_Error_S 1 "故障" 0 "正常" ;
VAL_TABLE_ VCU_Tortoise_Lamp_S 3 "预留" 2 "显示" 1 "不显示" 0 "预留" ;
VAL_TABLE_ Double_Flashing_On_Request_S 1 "关闭" 0 "开启" ;
VAL_TABLE_ VCU_Startup_Sign_S 1 "启动" 0 "未请求" ;
VAL_TABLE_ VCU_READY_Indicator_Light_S 3 "预留" 2 "插枪可用高压电（伪READY）" 1 "显示" 0 "不显示" ;
VAL_TABLE_ VCU_P_Archive_Lock_Dictate_S 3 "预留" 2 "解锁命令" 1 "锁止命令" 0 "预留" ;
VAL_TABLE_ VCU_FMCU_Startup_Stats_S 3 "故障模式(预留)" 2 "电机开启" 1 "电机关闭" 0 "预留" ;
VAL_TABLE_ VCU_Engine_Fail_Startup_Alert_S 1 "报警" 0 "不报警" ;
VAL_TABLE_ ECM_Protect_Speed_Flg_S 1 "有效" 0 "无效" ;
VAL_TABLE_ VCU_Radiator_Fan_Gear_S 3 "预留" 2 "高速档" 1 "低速档" 0 "关闭" ;
VAL_TABLE_ VCU_Vehicle_Energy_State_S 32 "串联发电模式四" 31 "串联发电模式三" 30 "串联发电模式二" 29 "行车辅助回馈模式三" 28 "行车辅助回馈模式二" 27 "行车辅助回馈模式一" 26 "行车辅助驱动模式三" 25 "行车辅助驱动模式二" 24 "行车辅助驱动模式一" 23 "怠速辅助" 22 "高速行车发电" 21 "低速行车发电模式二" 20 "低速行车发电模式一（在两驱状态混合动力制动回馈模式下也显示为此模式）" 19 "串联发电模式一" 18 "原地发电；（在两驱状态混合动力制动回馈模式下也显示为此模式）" 17 "纯燃油驱动（在两驱状态纯燃油驱动模式下也显示为此模式）" 16 "混合动力回馈模式三" 15 "混合动力回馈模式二（在两驱状态混合动力制动回馈模式下也显示为此模式）" 14 "混合动力回馈模式一" 13 "混合动力行车发电模式三" 12 "混合动力行车发电模式二（在两驱状态混合动力行车发电模式下也显示为此模式）" 11 "混合动力行车发电模式一" 10 "混合动力小功率输出（在两驱状态混合动力小功率输出(电机未输出)模式下也显示为此模式）" 9 "混合动力中功率输出模式二" 8 "混合动力中功率输出模式一（在两驱状态混合动力大功率输出模式下也显示为此模式）" 7 "混合动力全动力输出" 6 "纯电动回馈模式三" 5 "纯电动回馈模式二（在两驱状态纯电动回馈模式下也显示为此模式）" 4 "纯电动回馈模式一" 3 "纯电动驱动模式三" 2 "纯电动驱动模式二（在两驱状态纯电动驱动模式下也显示为此模式）" 1 "纯电动驱动模式一" 0 "无显示" ;
VAL_TABLE_ VCU_Vehicle_Energy_State_S 6 "纯电动后驱回馈" 5 "纯电动前驱回馈" 4 "纯电动四驱回馈" 3 "纯电动后驱" 2 "纯电动前驱" 1 "纯电动四驱动" 0 "无显示" ;
VAL_TABLE_ VCU_Startup_Sinter_Detect_S 3 "预留" 2 "启动" 1 "不启动" 0 "预留" ;
VAL_TABLE_ VCU_Energy_Fedbak_Mpa_Stats_S 3 "较大回馈" 2 "标准回馈" 1 "预留" 0 "无效" ;
VAL_TABLE_ VCU_SOC_Balance_Point_Select_S 3 "预留" 2 "手动选择" 1 "默认" 0 "无效" ;
VAL_TABLE_ Double_Flashing_Light_Up_Sign_S 1 "有效" 0 "无效" ;
VAL_TABLE_ VCU_Drive_Configuration_S 1 "有四驱配置" 0 "无四驱配置" ;
VAL_TABLE_ VCU_Angle_Calibration_State_S 1 "标定" 0 "未标定" ;
VAL_TABLE_ Motor_Drive_Configuration_S 5 "前驱双电机配置" 4 "四电机四驱配置" 3 "后驱配置" 2 "四驱配置" 1 "前驱配置" 0 "无效" ;
VAL_TABLE_ Brake_Lighting_Sign_341_S 1 "有效" 0 "无效" ;
VAL_TABLE_ Brake_Priority_Status_341_S 1 "油门和制动踏板同时踩下" 0 "油门和制动踏板未同时踩下" ;
VAL_TABLE_ ON_exit_HVtag_Sign_S 1 "无效" 0 "ON档电上高压标志位有效" ;
VAL_TABLE_ LVtag_Limit_Power_Sign_S 3 "预留" 2 "二级限功率" 1 "一级限功率" 0 "无效" ;
VAL_TABLE_ ActualThrotDepth_Validflag_S 1 "有效" 0 "无效" ;
VAL_TABLE_ Throttle_Depth_Effective_Bit_S 1 "有效" 0 "无效" ;
VAL_TABLE_ VCU_Brake_Depth_Virtual_Value_S 1 "有效" 0 "无效" ;
VAL_TABLE_ VCU_Vehicle_Work_Mode342_Byte3_S 3 "HEV" 2 "串联模式" 1 "EV" 0 "停止" ;
VAL_TABLE_ VCU_Vehicle_Run_Mode_S 3 "普通模式（Normal）" 2 "运动模式" 1 "经济模式" 0 "预留" ;
VAL_TABLE_ VCU_Vehicle_Run_Mode_S 3 "雪地模式" 2 "运动模式" 1 "经济模式" 0 "预留" ;
VAL_TABLE_ VCU_Veh_Work_Mode_Switch_Stats_S 1 "正在切换" 0 "未切换" ;
VAL_TABLE_ VCU_Vehicle_Run_Mode2_S 3 "预留" 2 "预留" 1 "Normal" 0 "预留" ;
VAL_TABLE_ VCU_Goal_Gear_S 4 "D档" 3 "N档" 2 "R档" 1 "P档" 0 "预留" ;
VAL_TABLE_ Vehicle_Work_Mode_S 3 "HEV" 2 "强制EV" 1 "EV" 0 "停止" ;
VAL_TABLE_ VCU_Initiative_Dischg_Cmd_S 3 "预留" 2 "主动泄放功能关闭" 1 "主动泄放功能开启" 0 "预留" ;
VAL_TABLE_ VCU_Vehicle_Work_Mode342_Byte5_S 8 "动力系统未启用" 7 "纯电动后驱" 6 "纯电动前驱" 5 "纯燃油" 4 "HEV两驱（前电机+发动机)" 3 "HEV四驱(后电机+发动机)" 2 "HEV三动力四驱(三动力)" 1 "纯电动四驱" 0 "系统故障" ;
VAL_TABLE_ Motor_Help_Flg_S 1 "不允许" 0 "允许" ;
VAL_TABLE_ VCU_Goal_Road_Mode_342_S 4 "沙地" 3 "泥泞地面/车辙地" 2 "草地/砂砾地/雪地" 1 "普通模式" 0 "无效" ;
VAL_TABLE_ VCU_FMCU_Dynamoelectr_Sign_S 1 "发电状态（当前电机处于发电状态）" 0 "无效" ;
VAL_TABLE_ VCU_MIL_Req_S 3 "预留" 2 "点亮MIL灯" 1 "不点亮MIL灯" 0 "无效" ;
VAL_TABLE_ VCU_Practice_Road_Mode_342_S 4 "沙地" 3 "泥泞地面/车辙地" 2 "草地/砂砾地/雪地" 1 "普通模式" 0 "无效" ;
VAL_TABLE_ Flag_Bit_342_S 1 "正确 " 0 "错误" ;
VAL_TABLE_ VCU_Current_vehic_Adherent_Sts_S 5 "交叉高附" 4 "单侧高附" 3 "后轴高附" 2 "前轴高附" 1 "单后轮高附" 0 "单前轮高附" ;
VAL_TABLE_ VLC_Status_242_S 1 "处于自适应巡航状态" 0 "未处于自适应巡航状态" ;
VAL_TABLE_ VCU_APA_State_S 3 "禁止" 2 "泊车中" 1 "允许" 0 "无效" ;
VAL_TABLE_ Front_Motor_Speed_Error_S 1 "Error" 0 "No Error" ;
VAL_TABLE_ VCU_Driver_VLC_Request_Torque_S 1 "Driver Override" 0 "No Override" ;
VAL_TABLE_ VCU_Park_Switch_S 1 "Skid" 0 "loosen" ;
VAL_TABLE_ Acceleration_Pedal_depth_error_S 1 "Error" 0 "No Error" ;
VAL_TABLE_ VirtualThrotDepth_Validflag_S 1 "Error" 0 "No Error" ;
VAL_TABLE_ VCU_Break_Pedal_Stats_S 3 "Error" 2 "Reserved" 1 "Pressed" 0 "Not Pressed" ;
VAL_TABLE_ FMCU_DriveMode_Feedback_S 1 "自动驾驶模式" 0 "正常驾驶模式" ;
VAL_TABLE_ VCU_Gear_S 4 "D" 3 "N" 2 "R" 1 "P" 0 "Reserved" ;
VAL_TABLE_ VCU_Gear_Stats_S 1 "Invalid" 0 "Valid" ;
VAL_TABLE_ VCU_Front_Motor_Stats_S 3 "Reserved" 2 "Error" 1 "Not Active" 0 "Active" ;
VAL_TABLE_ Target_Shift_Gear_Mode_Status_S 1 "Invalid" 0 "Valid" ;
VAL_TABLE_ Actual_Shift_Gear_Mode_Status_S 1 "Invalid" 0 "Valid" ;
VAL_TABLE_ Target_Gear_Status_S 1 "Invalid" 0 "Valid" ;
VAL_TABLE_ Actual_Gear_Status_S 1 "Invalid" 0 "Valid" ;
VAL_TABLE_ Gear_Shift_Progress_S 1 "In Progress" 0 "Not In Progress" ;
VAL_TABLE_ Gear_Shift_Progress_State_S 1 "Invalid" 0 "Valid" ;
VAL_TABLE_ TCU_Mode_Switch_S 3 "Reserved" 2 "Sport" 1 "ECO" 0 "Normal" ;
VAL_TABLE_ Target_Shift_Gear_Mode_S 8 "M-(Fuel)" 7 "M+(Fuel)" 6 "S(Fuel)" 5 "M(Fuel)" 4 "D" 3 "N" 2 "R" 1 "P" 0 "Invalid" ;
VAL_TABLE_ TCU_Target_Gear_S 7 "7档" 6 "6档" 5 "5档" 4 "4档" 3 "3档" 2 "2档" 1 "1档" 0 "无效" ;
VAL_TABLE_ Prhibt_Allow_Start_Eng_S 1 "允许启动" 0 "禁止启动" ;
VAL_TABLE_ TCU_INS_Prompt_Infor_S 13 "变速箱油温过高，请安全靠边停车冷却（AT新增该报文、燃油车）" 12 "离合温度高，靠边停车冷却（AT取消该报文）" 11 "请检查变速器系统" 8 "变速器功能受限" 7 "变速箱正在自适应，请等待" 4 "通讯异常，请检查" 3 "电磁阀清洗中，请等待" 0 "不显示" ;
VAL_TABLE_ Gear_Signal_Flg_S 1 "Position Signal OK" 0 "Position Signal Erroneous or Position Signal Substituted" ;
VAL_TABLE_ Symboel_of_engine_stop_S 1 "错误" 0 "正常" ;
VAL_TABLE_ Engine_Stop_S 1 "熄火" 0 "无效" ;
VAL_TABLE_ TCU_Cooling_Fan_Active_State_S 1 "Activated(Fullpower100%)" 0 "Not Activated" ;
VAL_TABLE_ Prhibt_Allow_Extinguish_Eng_S 1 "允许熄灭" 0 "禁止熄灭" ;
VAL_TABLE_ Break_Pedal_Active_State_S 1 "Brake pedal activated" 0 "Brake pedal not activated" ;
VAL_TABLE_ AC_Prhibt_Allow_S 1 "Aircondition prohibited" 0 "Aircondition allowed" ;
VAL_TABLE_ Clutch1_Status_S 7 "Unknown" 6 "Not Used" 5 "Clutch Applied" 4 "Clutch Closed" 3 "Filling" 2 "Clutch Closing" 1 "Creeping" 0 "Clutch Open" ;
VAL_TABLE_ Clutch2_Status_S 7 "Unknown" 6 "Not Used" 5 "Clutch Applied" 4 "Clutch Closed" 3 "Filling" 2 "Clutch Closing" 1 "Creeping" 0 "Clutch Open" ;
VAL_TABLE_ Actual_Shift_Gear_Mode_S 8 "M-(Fuel)" 7 "M+(Fuel)" 6 "S(Fuel)" 5 "M(Fuel)" 4 "D" 3 "N" 2 "R" 1 "P" 0 "Invalid" ;
VAL_TABLE_ Actual_Gear_S 7 "7th/档" 6 "6th/档" 5 "5th/档" 4 "4th/档" 3 "3rd/档" 2 "2nd/档" 1 "1st/档" 0 "无效" ;
VAL_TABLE_ IPB_Remote_Brake_Status_S 3 "车速控制speedcontrol" 2 "解除制动命令release" 1 "制动命令brake" 0 "无效" ;
VAL_TABLE_ IPB_Remot_Brake_Avail_S 1 "Available" 0 "Not Available" ;
VAL_TABLE_ Vehicle_Speed_Stats_S 1 "Invalid" 0 "Valid" ;
VAL_TABLE_ AWB_Available_S 1 "Available" 0 "Not Available" ;
VAL_TABLE_ AWB_Active_Brake_Warning_S 1 "Active" 0 "No Active" ;
VAL_TABLE_ AEB_Dec_Active_S 1 "Active" 0 "No Active" ;
VAL_TABLE_ AEB_not_Available_S 1 "Available" 0 "Not Available" ;
VAL_TABLE_ Prefill_Available_S 1 "Available" 0 "Not Available" ;
VAL_TABLE_ Prefill_Active_S 1 "Active" 0 "No Active" ;
VAL_TABLE_ ABAavailable_S 1 "Available" 0 "Not Available" ;
VAL_TABLE_ ABA_Active_S 1 "Active" 0 "No Active" ;
VAL_TABLE_ IPB_AEB_BAAct_S 1 "Active" 0 "No Active" ;
VAL_TABLE_ IPB_MIL_Lamp_Req_S 3 "预留" 2 "点亮MIL灯" 1 "不点亮MIL灯" 0 "无效" ;
VAL_TABLE_ HBC_Active_S 1 "Active" 0 "NoActive" ;
VAL_TABLE_ HBC_Stats_S 5 "HBC_OFF_And_Booster_failure" 4 "HBB_OFF" 3 "HBB_FailedBoosterBackup" 2 "HBB_FailedBoosterReduced" 1 "HBB_FailedBooster" 0 "HBBnormalmode" ;
VAL_TABLE_ HHC_Fault_S 1 "Failure" 0 "No Failure" ;
VAL_TABLE_ ATS_Ctrl_Status_S 1 "ATSinValid" 0 "ATSValid" ;
VAL_TABLE_ Brake_Fluid_Warning_S 3 "Reserved" 2 "BrakeFluid_Electric_error" 1 "BrakeFluid_Empty" 0 "BrakeFluid_Normal" ;
VAL_TABLE_ IPB_Sport_Model_S 1 "Active  " 0 "Inactive  " ;
VAL_TABLE_ Basc_RA_S 1 "Active  " 0 "Inactive  " ;
VAL_TABLE_ IPB_Func_Mode_S 1 "标准" 0 "舒适" ;
VAL_TABLE_ HDC_Failure_S 1 "Failure" 0 "No Failure" ;
VAL_TABLE_ HDC_CtrlStatus_S 3 "IPBwithoutHDC" 2 "HDCOnwithactivebraking(lampflashing)" 1 "HDCOnwithoutactivebraking(lampon)" 0 "HDCOff(nolamp)" ;
VAL_TABLE_ Brake_Pedal_Status_S 3 "Error" 2 "Reserved" 1 "Pressed" 0 "Not Pressed" ;
VAL_TABLE_ Basc_Front_S 1 "Active" 0 "Inactive" ;
VAL_TABLE_ Clutch_Pedal_Status_S 1 "Pressed" 0 "Not Pressed" ;
VAL_TABLE_ ACMH_Fault_S 1 "Failure" 0 "No Failure" ;
VAL_TABLE_ ESP_OFF_S 1 "ESP OFF" 0 "ESP ON" ;
VAL_TABLE_ ESP_Active_S 1 "Active" 0 "No Active" ;
VAL_TABLE_ TCS_Fault_S 1 "Failure" 0 "No Failure" ;
VAL_TABLE_ VDC_Fault_S 1 "Failure" 0 "No Failure" ;
VAL_TABLE_ EBD_Active_222_S 1 "Active" 0 "No Active" ;
VAL_TABLE_ ABS_Active_222_S 1 "Active" 0 "No Active" ;
VAL_TABLE_ EBD_Fault_222_S 1 "Failure" 0 "No Failure" ;
VAL_TABLE_ ABS_Fault_222_S 1 "Failure" 0 "No Failure" ;
VAL_TABLE_ TCS_Active_222_S 1 "Active" 0 "Not Active" ;
VAL_TABLE_ DWT_B_Active_222_S 1 "Active" 0 "Not Active" ;
VAL_TABLE_ VDC_Active_222_S 1 "Active" 0 "Not Active" ;
VAL_TABLE_ Yaw_Rate_Status_S 1 "Valid" 0 "Not Valid" ;
VAL_TABLE_ ESC_APA_Status_S 3 "预留的其他错误" 2 "自动泊车激活" 1 "ESP/IPB纵向速度控制模块准备就绪" 0 "ESP/IPB纵向速度控制模块功能关闭" ;
VAL_TABLE_ ESC_APA_Failure_Sts_S 3 "预留" 2 "ESP/IPB内部故障" 1 "车辆运行受阻" 0 "无故障" ;
VAL_TABLE_ ESC_APA_Availability_S 1 "Long Ctrl_Automatic Park" 0 "No LongCtrl_Support" ;
VAL_TABLE_ IPB_AY_Status_S 1 "Valid" 0 "Not Valid" ;
VAL_TABLE_ IPB_AX_Status_S 1 "Valid" 0 "Not Valid" ;
VAL_TABLE_ IPB_Simulator_Pressure_Sts_S 1 "Invalid" 0 "Valid" ;
VAL_TABLE_ MC_Pressure_Status_S 1 "Invalid" 0 "Valid" ;
VAL_TABLE_ IPB_Plunger_Pres_status_S 1 "Invalid" 0 "Valid" ;
VAL_TABLE_ MC_Pressure_Offset_Status_S 1 "Invalid" 0 "Valid" ;
VAL_TABLE_ Gear_Hold_Request_S 1 "Shifting Suppressed" 0 "Shifting Not Suppressed" ;
VAL_TABLE_ Moving_Condition_S 0 "挪车工况" ;
VAL_TABLE_ Ve_Target_Fdback_Tor_Flag_S 3 "Reserved" 2 "Faulty" 1 "Normal" 0 "Not Intialized" ;
VAL_TABLE_ AVH_Insf_StdbyCond_Hnt_Sta_S 3 "Reserved" 2 "Reserved" 1 "Active" 0 "No Active" ;
VAL_TABLE_ IPB_AVH_Button_S 3 "IPBwithout AVH（无AVH配置）" 2 "No Button（无硬线开关）" 1 "With Button（有硬线开关）" 0 "Reserved" ;
VAL_TABLE_ ESP_OFF_button_S 3 "Without IPB（无IPB配置）" 2 "No Button（无硬线开关）" 1 "With Button（有硬线开关）" 0 "Reserved" ;
VAL_TABLE_ RR_Wheel_Drive_Direction_S 3 "Stop" 2 "Backward" 1 "Forward" 0 "Undefinable" ;
VAL_TABLE_ RL_Wheel_Drive_Direction_S 3 "Stop" 2 "Backward" 1 "Forward" 0 "Undefinable" ;
VAL_TABLE_ FR_Wheel_Drive_Direction_S 3 "Stop" 2 "Backward" 1 "Forward" 0 "Undefinable" ;
VAL_TABLE_ FL_Wheel_Drive_Direction_S 3 "Stop" 2 "Backward" 1 "Forward" 0 "Undefinable" ;
VAL_TABLE_ Active_Vehicle_Hold_S 1 "Active Vehicle Hold" 0 "Not Active Vehicle Hold" ;
VAL_TABLE_ VLC_Available_S 1 "Available" 0 "Not Available" ;
VAL_TABLE_ VLC_Active_S 1 "Active" 0 "No Active" ;
VAL_TABLE_ VLC_Fail_S 1 "Failure" 0 "No Failure" ;
VAL_TABLE_ No_Brake_Force_S 1 "No Brake Force" 0 "Exist Brake Force" ;
VAL_TABLE_ IPB_Request_EPB_S 3 "IPBRequestApb_LockBrake" 2 "IPBRequestApb_ReleaseBrake" 1 "IPBRequestApb_NoRequest" 0 "IPBRequest Apb_NotInitialized" ;
VAL_TABLE_ QDC_ACC_S 1 "Error" 0 "No Error" ;
VAL_TABLE_ ECD_Temp_Off_S 1 "Temp Too High" 0 "Not High" ;
VAL_TABLE_ Vlc_Prevent_Fuel_Cut_Off_S 1 "Request To Prevent Fule Cutoff" 0 "No Request To Prevent Fule Cutoff" ;
VAL_TABLE_ Vehicle_Stand_Still_S 3 "Reserved" 2 "Invalid(shortunavailability，max3s)" 1 "Standstill" 0 "Not Standstill" ;
VAL_TABLE_ FL_Wheel_Drive_Direct_Stat_S 1 "Invalid" 0 "Valid" ;
VAL_TABLE_ FR_Wheel_Drive_Direct_Stat_S 1 "Invalid" 0 "Valid" ;
VAL_TABLE_ RL_Wheel_Drive_Direct_Stat_S 1 "Invalid" 0 "Valid" ;
VAL_TABLE_ RR_Wheel_Drive_Direct_Stat_S 1 "Invalid" 0 "Valid" ;
VAL_TABLE_ VLC_Torque_Request_Status_S 1 "Active" 0 "No Active" ;
VAL_TABLE_ CDD_Available_S 1 "Available" 0 "No Available" ;
VAL_TABLE_ CDD_Active_S 1 "Active" 0 "No Active" ;
VAL_TABLE_ CDD_Fail_S 1 "Failure" 0 "No Failure" ;
VAL_TABLE_ RR_Wheel_Puls_Count_Valid_422_S 1 "Invalid" 0 "Valid" ;
VAL_TABLE_ RL_Wheel_Puls_Count_Valid_422_S 1 "Invalid" 0 "Valid" ;
VAL_TABLE_ FR_Wheel_Puls_Count_Valid_422_S 1 "Invalid" 0 "Valid" ;
VAL_TABLE_ FL_Wheel_Puls_Count_Valid_422_S 1 "Invalid" 0 "Valid" ;
VAL_TABLE_ Wheel_Speed_FR_Stats_1F0_S 1 "Invalid" 0 "Valid" ;
VAL_TABLE_ Wheel_Speed_FL_Stats_1F0_S 1 "Invalid" 0 "Valid" ;
VAL_TABLE_ Wheel_Speed_RR_Stats_1F0_S 1 "Invalid" 0 "Valid" ;
VAL_TABLE_ WheelSpeed_RL_Status_1F0_S 1 "Invalid" 0 "Valid" ;
VAL_TABLE_ IPB_Imput_Rod_Stroke_State_S 1 "Invalid" 0 "Valid" ;
VAL_TABLE_ EPB_Set_S 1 "IPB" 0 "ESP" ;
VAL_TABLE_ BDW_Function_State_S 1 "Available" 0 "Not Available" ;
VAL_TABLE_ FWA_warning_S 3 "预留" 2 "制动系统温度过高报警级别2" 1 "制动系统温度过高报警级别1" 0 "无故障" ;
VAL_TABLE_ CST_Status_S 3 "CSTisFailure（故障）" 2 "CSTisActive（激活）" 1 "CSTisStandby（待命）" 0 "CSTisDisabled（禁用）" ;
VAL_TABLE_ IPB_System_Status_S 4 "HydBackw/act/HydBackw/oact" 3 "BBF_C1/2BoostOnly" 2 "BBF_CircuitSperation" 1 "BBF_DegradedPedalFeel" 0 "BBF_FullSys" ;
VAL_TABLE_ RollBench_Status_S 1 "Active" 0 "Not Active" ;
VAL_TABLE_ IPB_With_CST_S 1 "IPB With CST" 0 "IPB Without CST" ;
VAL_TABLE_ EPS_Fault_Waring_S 3 "一般故障" 2 "EPS一般故障（遥控驾驶故障，禁止遥控驾驶）" 1 "EPS严重故障（正常驾驶故障，禁止遥控驾驶）" 0 "正常" ;
VAL_TABLE_ Steering_Mode_Status_S 4 "运动+" 3 "运动" 2 "舒适+" 1 "舒适" 0 "无效" ;
VAL_TABLE_ If_AU_Thr_INS_Or_Med_Set_SM_S 1 "禁止" 0 "允许" ;
VAL_TABLE_ Supplier_Identification_S 15 "TRW" 14 "华为" 9 "博世华域" 8 "东华" 7 "龙润" 6 "万达" 5 "十四部" 4 "NSK" 3 "Mobis" 2 "豫北" 1 "Nexteer" 0 "预留" ;
VAL_TABLE_ SFS_Configuration_S 1 "激活" 0 "未激活" ;
VAL_TABLE_ Failure_Stats_OK_S 1 "Sensor Information Valid" 0 "Sensor Information Invalid" ;
VAL_TABLE_ Sensor_Calibration_Stats_S 1 "Sensor1 Calibrated" 0 "Sensor Not Calibrated" ;
VAL_TABLE_ TRIM_Trimming_Stats_S 1 "Sensor Trimmed" 0 "Sensor Not Trimmed" ;
VAL_TABLE_ EPS_LKA_Control_State_S 4 "ExternalRequireorEPSPermanentlyFailed" 3 "ExternalRequireorEPSTemporaryFailed" 2 "EPSExternalSteeringTorqueRequireControlActive" 1 "EPSExternalSteeringTorqueRequireControlReady" 0 "EPSExternalSteeringTorqueRequireControlNotReady" ;
VAL_TABLE_ EPS_LKA_Control_Abort_Feedback_S 10 "EPSPermanentlyerror" 9 "FailedTempTimeOverLimit" 8 "RequestTorqueValueoverrange" 7 "RequestTorqueSlopeoverrange" 6 "EPSTemporaryerror" 5 "MPC_2Signalerror" 4 "MPCActivationRequestError" 3 "VehicleSpeedInvalid" 2 "Driveroverride" 1 "Driverhandsoff" 0 "Nointerruption" ;
VAL_TABLE_ LKACtrlDlvdValue_VD_S 1 "Valid" 0 "Invalid" ;
VAL_TABLE_ Hnads_Off_Detected_States_S 1 "Hands Of Detected" 0 "Hands Off Not Detected" ;
VAL_TABLE_ Hnads_Off_Detected_States_VD_S 1 "Valid" 0 "Invalid" ;
VAL_TABLE_ StrngWhlTorqVD_S 1 "Valid" 0 "Invalid" ;
VAL_TABLE_ Vibration_Status_S 3 "预留" 2 "振动保护" 1 "振动" 0 "无振动" ;
VAL_TABLE_ HMA_Stats_S 5 "Camera Blocked" 4 "Fault" 3 "Active" 2 "Standby" 1 "Passive" 0 "Off" ;
VAL_TABLE_ HMA_High_Beam_Request_S 1 "HighBeam Request" 0 "LowBeam Request" ;
VAL_TABLE_ Left_Line_Tracking_Status_S 3 "Warning" 2 "Intervention" 1 "Line Tracking" 0 "No Display" ;
VAL_TABLE_ Lane_Assistant_Mode_Status_S 3 "全功能" 2 "车道保持/车道纠偏" 1 "车道偏离" 0 "关闭" ;
VAL_TABLE_ LKS_Sensitivity_S 3 "Reserved" 2 "Reserved" 1 "High Sensitivity" 0 "Low Sensitivity" ;
VAL_TABLE_ MPC_Take_Over_Req_S 1 "Active" 0 "Inactive" ;
VAL_TABLE_ LDP_LDW_Camera_Blocked_S 1 "Camera Blocked" 0 "正常" ;
VAL_TABLE_ LDP_Fault_S 1 "LKS Fault" 0 "正常" ;
VAL_TABLE_ LDW_fault1_S 1 "LDW Fault" 0 "正常" ;
VAL_TABLE_ ACC_AEB_Camera_Blocked_Infro_S 1 "ACCAEB Camera Block" 0 "No Display" ;
VAL_TABLE_ LKS_torque_request_staus_S 3 "Reserved" 2 "Active" 1 "Ready" 0 "Inhibited" ;
VAL_TABLE_ RSF_function_status_S 4 "Defect" 3 "Navigation Only Mode" 2 "Vision Mode" 1 "Fusion Mode" 0 "Off" ;
VAL_TABLE_ RSF_Output_Speed_Limit_Unit_S 3 "Reserved" 2 "MPH" 1 "KMH" 0 "Unknown" ;
VAL_TABLE_ Right_Line_Tracking_Stats_S 3 "Warning" 2 "Intervention" 1 "Line Tracking" 0 "No Display" ;
VAL_TABLE_ TJA_ICA_function_status_S 5 "stand-by" 4 "Fault" 3 "Active2" 2 "Active1" 1 "Passive" 0 "OFF" ;
VAL_TABLE_ ALL_Function_Camera_Bloc_Infro_S 1 "ALL Function Camera Block" 0 "No Display" ;
VAL_TABLE_ RSF_Output_Speed_Limit_S 27 "SPL130" 6 "SPL25" 5 "SPL20" 4 "SPL15" 3 "SPL10" 2 "SPL5" 1 "SPLCancelled" 0 "NoDisplay" ;
VAL_TABLE_ LDW_Warning_Mode_Stats_S 3 "预留" 2 "振动+声音" 1 "仅声音" 0 "仅振动" ;
VAL_TABLE_ MPC_Take_Over_Req1_S 3 "warning-level3" 2 "warning-level2" 1 "warning-level1" 0 "inactive" ;
VAL_TABLE_ ACC_Assemble_Status_S 1 "YES" 0 "NO" ;
VAL_TABLE_ AEB_Assemble_Status_S 1 "YES" 0 "NO" ;
VAL_TABLE_ FCW_Assemble_Status_S 1 "YES" 0 "NO" ;
VAL_TABLE_ HMA_Assemble_Status_S 1 "YES" 0 "NO" ;
VAL_TABLE_ LDW_Assemble_Status_S 1 "YES" 0 "NO" ;
VAL_TABLE_ LKS_Assemble_Status_S 1 "YES" 0 "NO" ;
VAL_TABLE_ TSR_Assemble_Status_S 1 "YES" 0 "NO" ;
VAL_TABLE_ TJA_ICA_Assemble_Status_S 1 "YES" 0 "NO" ;
VAL_TABLE_ Module_Manufacturer_S 4 "ZF" 3 "Conti" 2 "Veoneer" 1 "博世" 0 "十五部" ;
VAL_TABLE_ LDW_Warning_Conf_Exchange_S 1 "YES" 0 "NO" ;
VAL_TABLE_ TJA_ICA_SoftKeys_S 1 "YES" 0 "NO" ;
VAL_TABLE_ LDP_Assemble_Status_S 1 "NO" 0 "YES" ;
VAL_TABLE_ ELK_Assemble_Status_S 1 "NO" 0 "YES" ;
VAL_TABLE_ FCTA_Assemble_Status_S 1 "NO" 0 "YES" ;
VAL_TABLE_ FCTB_Assemble_Status_S 1 "NO" 0 "YES" ;
VAL_TABLE_ ISLI_Assemble_Statue_S 1 "NO" 0 "YES" ;
VAL_TABLE_ HNP_Assemble_Status_S 1 "NO" 0 "YES" ;
VAL_TABLE_ ILCA_Assemble_Status_S 1 "NO" 0 "YES" ;
VAL_TABLE_ TLA_Assemble_Status_S 1 "NO" 0 "YES" ;
VAL_TABLE_ ISLC_Assemble_Status_S 1 "NO" 0 "YES" ;
VAL_TABLE_ ESA_Assemble_Status_S 1 "NO" 0 "YES" ;
VAL_TABLE_ FCW_UI_Assemble_Status_S 1 "Old" 0 "New" ;
VAL_TABLE_ Meter_Display_Mode_S 1 "单车道" 0 "三车道" ;
VAL_TABLE_ UNP_Assemble_Status_S 1 "NO" 0 "YES" ;
VAL_TABLE_ CSW_Assemble_Status_S 1 "NO" 0 "YES" ;
VAL_TABLE_ ADS_System_Status_S 3 "5R10V平台" 2 "13V平台" 1 "5R平台" 0 "Normal" ;
VAL_TABLE_ Child_ID_374_S 1 "Left_Obj左相邻车道车前目标" ;
VAL_TABLE_ Target_State_B6_374s1_S 3 "预留" 2 "对向行驶目标锁定" 1 "同向行驶目标锁定" 0 "无目标" ;
VAL_TABLE_ Target_State_B1_374s1_S 1 "目标锁定" 0 "无目标" ;
VAL_TABLE_ Target_Type_374s1_S 5 "动物（待定）" 4 "行人" 3 "两轮车" 2 "大型车（待定）" 1 "四轮车" 0 "无效" ;
VAL_TABLE_ Target_State_B6_374s2_S 3 "预留" 2 "对向行驶目标锁定" 1 "同向行驶目标锁定" 0 "无目标" ;
VAL_TABLE_ Target_State_B1_374s2_S 1 "目标锁定" 0 "无目标" ;
VAL_TABLE_ Target_Type_374s2_S 5 "动物（待定）" 4 "行人" 3 "两轮车" 2 "大型车（待定）" 1 "四轮车" 0 "无效" ;
VAL_TABLE_ Target_State_B6_374s3_S 3 "预留" 2 "对向行驶目标锁定" 1 "同向行驶目标锁定" 0 "无目标" ;
VAL_TABLE_ Target_State_B1_374s3_S 1 "目标锁定" 0 "无目标" ;
VAL_TABLE_ Target_Type_374s3_S 5 "动物（待定）" 4 "行人" 3 "两轮车" 2 "大型车（待定）" 1 "四轮车" 0 "无效" ;
VAL_TABLE_ Target_State_B6_374s4_S 3 "预留" 2 "对向行驶目标锁定" 1 "同向行驶目标锁定" 0 "无目标" ;
VAL_TABLE_ Target_State_B1_374s4_S 1 "目标锁定" 0 "无目标" ;
VAL_TABLE_ Target_Type_374s4_S 5 "动物（待定）" 4 "行人" 3 "两轮车" 2 "大型车（待定）" 1 "四轮车" 0 "无效" ;
VAL_TABLE_ Target_State_B6_374s5_S 3 "预留" 2 "对向行驶目标锁定" 1 "同向行驶目标锁定" 0 "无目标" ;
VAL_TABLE_ Target_State_B1_374s5_S 1 "目标锁定" 0 "无目标" ;
VAL_TABLE_ Target_Type_374s5_S 5 "动物（待定）" 4 "行人" 3 "两轮车" 2 "大型车（待定）" 1 "四轮车" 0 "无效" ;
VAL_TABLE_ Left_Lane_Line_Type_S 3 "路沿石" 2 "虚线" 1 "实线" 0 "未检测到车道线" ;
VAL_TABLE_ Right_Lane_Line_Type_S 3 "路沿石" 2 "虚线" 1 "实线" 0 "未检测到车道线" ;
VAL_TABLE_ Obj_Valid_S 1 "Target Object Detected" 0 "No Object" ;
VAL_TABLE_ Tau_Gap_Set_S 7 "tauGap_7" 6 "tauGap_6" 5 "tauGap_5" 4 "tauGap_4" 3 "tauGap_3" 2 "tauGap_2" 1 "tauGap_1" 0 "tauGap_0" ;
VAL_TABLE_ Dx_Tar_Obj_S 7 "Distance_7" 6 "Distance_6" 5 "Distance_5" 4 "Distance_4" 3 "Distance_3" 2 "Distance_2" 1 "Distance_1" 0 "Distance_0" ;
VAL_TABLE_ PCW_Pre_Warning_S 1 "Warning" 0 "No Warning" ;
VAL_TABLE_ PCW_Latent_Warning_S 1 "Warning" 0 "No Warning" ;
VAL_TABLE_ PCW_State_S 1 "ON" 0 "OFF" ;
VAL_TABLE_ ACC_Mode_Display_S 7 "Failure Mode" 6 "Reserved" 5 "Override" 4 "Brake Only Mode" 3 "Active Control Mode" 2 "StandBy Mode" 1 "PassiveMode" 0 "OFF Mode" ;
VAL_TABLE_ ACC_State_S 1 "ON" 0 "OFF" ;
VAL_TABLE_ Take_Over_Req_S 1 "Valid TakeOver Request" 0 "No TakeOver Request" ;
VAL_TABLE_ Speed_Unit_Set_S 3 "预留" 2 "MPH" 1 "Km/h" 0 "无效" ;
VAL_TABLE_ CCR_AEB_Error_S 1 "请检查AEB系统" 0 "无显示Nodisplay" ;
VAL_TABLE_ ACC_Text_Info_For_Driver_S 15 "前车已驶离，请踩加速踏板起步" 14 "请确认ESP功能是否开启" 13 "请确认EPB是否释放" 12 "请确认档位是否在D档" 11 "请确认车门是否关好" 10 "请确认安全带是否系上" 9 "请检查自适应巡航系统" 8 "ACC已关闭" 7 "ACC已开启" 6 "预留" 5 "危险请制动" 4 "超越加速中" 3 "ACC已激活" 2 "ACC取消" 1 "ACC无法激活" 0 "无显示" ;
VAL_TABLE_ CCR_FCW_Error_S 1 "请检查FCW系统" 0 "无显示Nodisplay" ;
VAL_TABLE_ Pedestrian_FCW_Brak_Error_S 1 "请检查VRU系统" 0 "无显示Nodisplay" ;
VAL_TABLE_ Acute_Warning_S 1 "Warning" 0 "No Warning" ;
VAL_TABLE_ AEB_State_S 1 "ON" 0 "OFF" ;
VAL_TABLE_ PCW_Level_Feedback_S 3 "Level 3 高" 2 "Level 2 中(默认选择)" 1 "Level 1 低" 0 "OFF" ;
VAL_TABLE_ Front_Radar_FCTB_Warning_S 4 "FCTB warning_left_right（左右侧存在碰撞风险，FCTB激活，HMI报警））" 3 "FCTB warning _right（右侧存在碰撞风险，FCTB激活，HMI报警）" 2 "FCTB warning _left（左侧存在碰撞风险，FCTB激活，HMI报警）" 1 "AEB warning（AEB激活，HMI报警）" 0 "not_warning" ;
VAL_TABLE_ ACC_Mode_Display1_S 9 "永久故障" 5 "Override" 4 "Brake Only Mode" 3 "Active Control Mode" 2 "StandBy Mode" 1 "PassiveMode" 0 "OFF Mode" ;
VAL_TABLE_ MRR_Modulation_Status_S 3 "Reserved" 2 "TimesyncCorrect_ModFail" 1 "TimesyncFailure_ModFail" 0 "No Failure" ;
VAL_TABLE_ ACC_Drive_Off_Req_S 1 "request" 0 "norequest" ;
VAL_TABLE_ ACC_DecTo_Stop_Req_S 1 "request" 0 "norequest" ;
VAL_TABLE_ ACC_Minimum_Braking_S 1 "demand" 0 "nodemand" ;
VAL_TABLE_ Brake_Preferred_S 1 "demand" 0 "nodemand" ;
VAL_TABLE_ ACC_Mode_S 7 "Failuremode" 6 "Standstill" 5 "Override" 4 "BrakeOnlymode" 3 "ActiveControlmode" 2 "StandBymode" 1 "Passivemode" 0 "OFF" ;
VAL_TABLE_ ESP_VLC_Shut_Down_Request_S 3 "Initial" 2 "Immediateoff" 1 "Fastoff" 0 "Softoff" ;
VAL_TABLE_ Req_EBA_Decel_Ctrl_S 1 "demand" 0 "nodemand??????" ;
VAL_TABLE_ ESP_Prefill_Req_S 1 "demand" 0 "nodemand" ;
VAL_TABLE_ AWB_Request_S 1 "demand" 0 "nodemand" ;
VAL_TABLE_ ABA_Available_S 1 "demand" 0 "nodemand" ;
VAL_TABLE_ ABA_Level_S 3 "level3" 2 "level2" 1 "level1" 0 "level0" ;
VAL_TABLE_ AEB_DecCtrl_Request_S 1 "demand" 0 "nodemand" ;
VAL_TABLE_ ELK_OT_status_S 3 "Failure" 2 "Ative" 1 "Passive" 0 "OFF" ;
VAL_TABLE_ AWB_Level_S 4 "level4" 3 "level3" 2 "level2" 1 "level1" 0 "nolevel" ;
VAL_TABLE_ Req_ESC_Ctrl_Veh_S 1 "Nothold" 0 "Hold" ;
VAL_TABLE_ ISLC_Sts_S 1 "ON" 0 "OFF" ;
VAL_TABLE_ ELK_status_S 3 "Failure" 2 "Active" 1 "Passive" 0 "OFF" ;
VAL_TABLE_ ISLC_Warnning_S 1 "Request按set-操作" 0 "NoRequest" ;
VAL_TABLE_ ELK_Take_Over_Req_S 3 "warning-level3" 2 "warning-level2" 1 "warning-level1" 0 "inactive" ;
VAL_TABLE_ SeatbeltControl_Request_S 2 "Request to tension" 1 "Request to Shock" 0 "No Request" ;
VAL_TABLE_ MRR_SOS_Request_S 1 "Request" 0 "No request" ;
VAL_TABLE_ MRR_MRC_Request_S 1 "Request" 0 "No request" ;

BO_ 3221225472 VECTOR__INDEPENDENT_SIG_MSG: 0 Vector__XXX
 SG_ The_Drv_Demand_Trq_Sign_S : 0|1@1- (1,0) [0|0] "" Vector__XXX

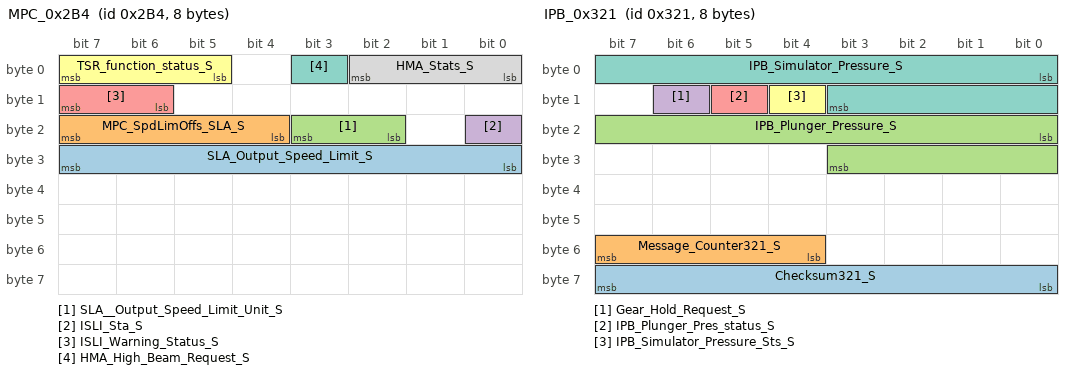
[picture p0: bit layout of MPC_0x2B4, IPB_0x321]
BO_ 692 MPC_0x2B4: 8 MPC
 SG_ SLA_Output_Speed_Limit_S : 24|8@1+ (1,0) [0|255] "" Vector__XXX
 SG_ MPC_SpdLimOffs_SLA_S : 20|4@1+ (1,0) [0|15] "" Vector__XXX
 SG_ SLA__Output_Speed_Limit_Unit_S : 18|2@1+ (1,0) [0|3] "" Vector__XXX
 SG_ ISLI_Sta_S : 16|1@1+ (1,0) [0|1] "" Vector__XXX
 SG_ ISLI_Warning_Status_S : 14|2@1+ (1,0) [0|3] "" Vector__XXX
 SG_ TSR_function_status_S : 5|3@1+ (1,0) [0|7] "" Vector__XXX
 SG_ HMA_High_Beam_Request_S : 3|1@1+ (1,0) [0|1] "" Vector__XXX
 SG_ HMA_Stats_S : 0|3@1+ (1,0) [0|7] "" Vector__XXX

BO_ 1178 LTE4G_0x49A: 8 Vector__XXX
 SG_ Medium_Checksum_49A_S : 56|8@1+ (1,0) [0|255] ""  MPC
 SG_ Medium_Enter_OTA_Mode_Req_S : 4|1@1+ (1,0) [0|1] ""  MPC

BO_ 801 IPB_0x321: 8 Vector__XXX
 SG_ Checksum321_S : 56|8@1+ (1,0) [0|255] ""  MPC
 SG_ Message_Counter321_S : 52|4@1+ (1,0) [0|15] ""  MPC
 SG_ IPB_Plunger_Pressure_S : 16|12@1+ (1,0) [0|4095] ""  MPC
 SG_ Gear_Hold_Request_S : 14|1@1+ (1,0) [0|1] ""  MPC
 SG_ IPB_Plunger_Pres_status_S : 13|1@1+ (1,0) [0|1] ""  MPC
 SG_ IPB_Simulator_Pressure_Sts_S : 12|1@1+ (1,0) [0|1] ""  MPC
 SG_ IPB_Simulator_Pressure_S : 0|12@1+ (1,0) [0|4095] ""  MPC

BO_ 308 APA_0x134: 8 Vector__XXX
 SG_ APA_Auto_Parking_Status_S : 0|3@1+ (1,0) [0|7] ""  MPC

BO_ 1263 Media_0x4EF: 8 Vector__XXX
 SG_ PCW_Level_Req_S m51 : 28|3@1+ (1,0) [0|7] ""  MPC
 SG_ ISLC_Enable_S m51 : 16|2@1+ (1,0) [0|3] ""  MPC
 SG_ Medium_0x4EF_ChilD_ID_S M : 0|8@1+ (1,0) [0|255] ""  MPC

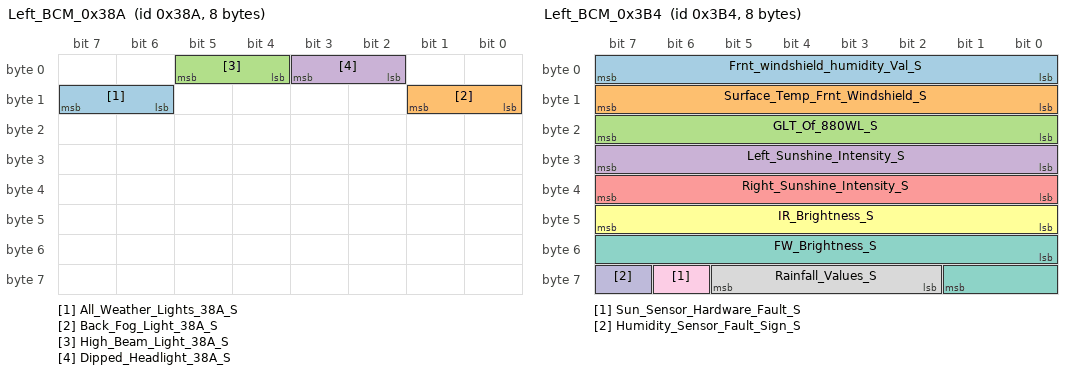
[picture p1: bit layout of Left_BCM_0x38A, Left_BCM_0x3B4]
BO_ 906 Left_BCM_0x38A: 8 Vector__XXX
 SG_ All_Weather_Lights_38A_S : 14|2@1+ (1,0) [0|3] ""  MPC
 SG_ Back_Fog_Light_38A_S : 8|2@1+ (1,0) [0|3] ""  MPC
 SG_ High_Beam_Light_38A_S : 4|2@1+ (1,0) [0|3] ""  MPC
 SG_ Dipped_Headlight_38A_S : 2|2@1+ (1,0) [0|3] ""  MPC

BO_ 836 BMS_0x344: 8 Vector__XXX
 SG_ BMC_Extn_Chag_Equp_Conec_Stat_S : 16|4@1+ (1,0) [0|0] ""  MPC

BO_ 948 Left_BCM_0x3B4: 8 Vector__XXX
 SG_ Frnt_windshield_humidity_Val_S : 0|8@1+ (0.5,0) [0|100] "%" Vector__XXX
 SG_ Surface_Temp_Frnt_Windshield_S : 8|8@1+ (0.5,-40) [-40|87] "℃" Vector__XXX
 SG_ GLT_Of_880WL_S : 16|8@1+ (1,0) [0|255] "" Vector__XXX
 SG_ Left_Sunshine_Intensity_S : 24|8@1+ (5,0) [0|1270] "w/m2"  MPC
 SG_ Right_Sunshine_Intensity_S : 32|8@1+ (5,0) [0|1270] "w/m2"  MPC
 SG_ IR_Brightness_S : 40|8@1+ (400,0) [0|101600] "w/m2" Vector__XXX
 SG_ FW_Brightness_S : 48|10@1+ (6,0) [0|6126] "Lux" Vector__XXX
 SG_ Rainfall_Values_S : 58|4@1+ (1,0) [0|14] ""  MPC
 SG_ Sun_Sensor_Hardware_Fault_S : 62|1@1+ (1,0) [0|1] ""  MPC
 SG_ Humidity_Sensor_Fault_Sign_S : 63|1@1+ (1,0) [0|1] ""  MPC

BO_ 660 Left_BCM_0x294: 8 Vector__XXX
 SG_ Left_Front_Door_Status_294_S : 0|2@1+ (1,0) [0|3] ""  MPC
 SG_ Right_Front_Door_Status_294_S : 2|2@1+ (1,0) [0|3] ""  MPC
 SG_ Left_Back_Door_Status_294_S : 4|2@1+ (1,0) [0|3] ""  MPC
 SG_ Right_Back_Door_Status_294_S : 6|2@1+ (1,0) [0|3] ""  MPC
 SG_ LeftF_Door_Stats_Valid_Bit_S : 8|1@1+ (1,0) [0|1] ""  MPC
 SG_ RightF_Door_Sts_Valid_Bit_294_S : 9|1@1+ (1,0) [0|1] ""  MPC
 SG_ LeftR_Door_Stats_Valid_Bit_S : 10|1@1+ (1,0) [0|1] ""  MPC
 SG_ RightR_Door_Sts_Valid_Bit_294_S : 11|1@1+ (1,0) [0|1] ""  MPC
 SG_ Driver_Belt_Stat_Effective_Bit_S : 12|1@1+ (1,0) [0|1] ""  MPC
 SG_ Back_Door_Sts_Effectiv_Bit_294_S : 13|1@1+ (1,0) [0|1] ""  MPC
 SG_ Frnt_Hatch_Stat_Effective_Bit_S : 14|1@1+ (1,0) [0|1] ""  MPC
 SG_ Emergency_Alarm_Effective_Bit_S : 15|1@1+ (1,0) [0|1] ""  MPC
 SG_ Driver_Belt_Status_S : 16|2@1+ (1,0) [0|3] ""  MPC
 SG_ Back_Door_Status_294_S : 18|2@1+ (1,0) [0|3] ""  MPC
 SG_ Former_Hatch_Status_294_S : 20|2@1+ (1,0) [0|3] ""  MPC
 SG_ Emergency_Alarm_Status_S : 22|2@1+ (1,0) [0|3] ""  MPC
 SG_ Rolling_counter_294_S : 48|4@1+ (1,0) [0|15] ""  MPC
 SG_ Checksum_294_S : 56|8@1+ (1,0) [0|255] ""  MPC

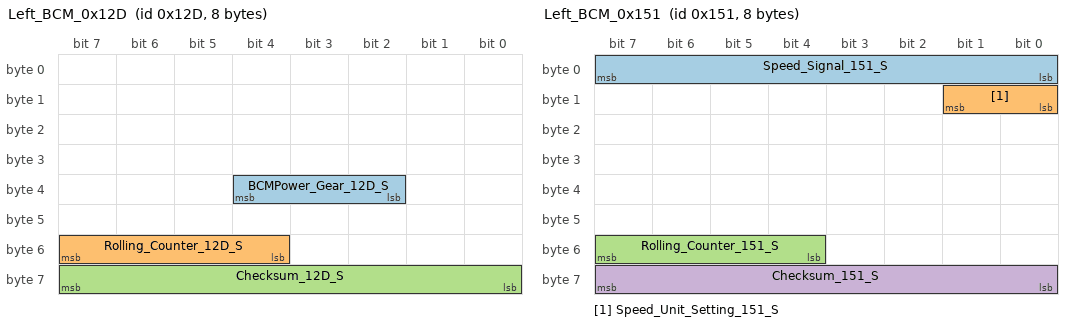
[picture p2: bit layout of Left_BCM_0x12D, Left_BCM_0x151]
BO_ 301 Left_BCM_0x12D: 8 Vector__XXX
 SG_ BCMPower_Gear_12D_S : 34|3@1+ (1,0) [0|7] ""  MPC
 SG_ Rolling_Counter_12D_S : 52|4@1+ (1,0) [0|15] ""  MPC
 SG_ Checksum_12D_S : 56|8@1+ (1,0) [0|255] ""  MPC

BO_ 1141 Left_BCM_0x475: 8 Vector__XXX
 SG_ Wiper_Speed_S : 26|2@1+ (1,0) [0|3] ""  MPC

BO_ 985 Left_BCM_0x3D9: 8 Vector__XXX
 SG_ Child_ID_3D9_S M : 0|8@1+ (1,0) [0|255] ""  MPC
 SG_ Total_Distance_3D9s5_S m5 : 8|27@1+ (0.1,0) [0|9999999.9] "km"  MPC

BO_ 1189 Left_BCM_0x4A5: 8 Vector__XXX
 SG_ Child_ID_4A5_S M : 0|8@1+ (1,0) [0|255] ""  MPC
 SG_ Total_Distance_4A5_S m2 : 8|27@1+ (0.1,0) [0|9999999.9] ""  MPC
 SG_ Mileage_Unit_4A5_S m2 : 35|2@1+ (1,0) [0|3] ""  MPC

BO_ 337 Left_BCM_0x151: 8 Vector__XXX
 SG_ Speed_Signal_151_S : 0|8@1+ (1,0) [0|240] "km/h"  MPC
 SG_ Speed_Unit_Setting_151_S : 8|2@1+ (1,0) [0|3] ""  MPC
 SG_ Rolling_Counter_151_S : 52|4@1+ (1,0) [0|15] ""  MPC
 SG_ Checksum_151_S : 56|8@1+ (1,0) [0|255] ""  MPC

BO_ 803 Left_BCM_0x323: 8 Vector__XXX
 SG_ INS_Show_Fault_323_S : 7|1@1+ (1,0) [0|1] ""  MPC

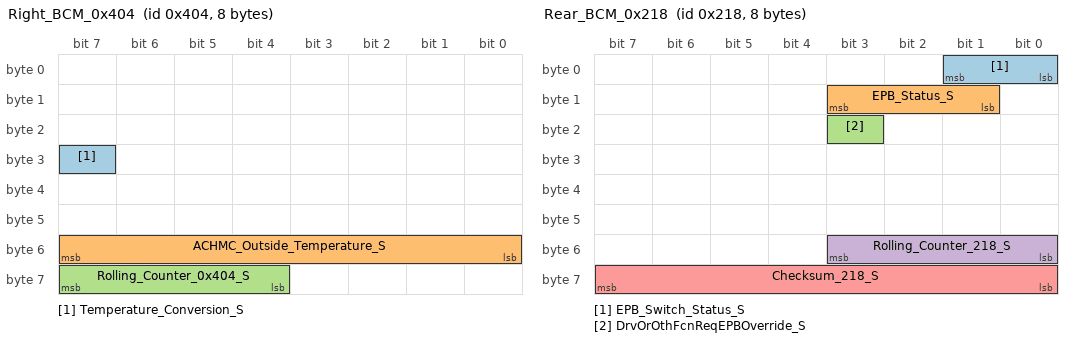
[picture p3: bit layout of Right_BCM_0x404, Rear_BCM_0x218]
BO_ 1028 Right_BCM_0x404: 8 Vector__XXX
 SG_ Temperature_Conversion_S : 31|1@1+ (1,0) [0|1] ""  MPC
 SG_ ACHMC_Outside_Temperature_S : 48|8@1+ (1,-128) [-40|50] "℃"  MPC
 SG_ Rolling_Counter_0x404_S : 60|4@1+ (1,0) [0|15] ""  MPC

BO_ 536 Rear_BCM_0x218: 8 Vector__XXX
 SG_ EPB_Switch_Status_S : 0|2@1+ (1,0) [0|3] ""  MPC
 SG_ EPB_Status_S : 9|3@1+ (1,0) [0|7] ""  MPC
 SG_ DrvOrOthFcnReqEPBOverride_S : 19|1@1+ (1,0) [0|1] ""  MPC
 SG_ Rolling_Counter_218_S : 48|4@1+ (1,0) [0|15] ""  MPC
 SG_ Checksum_218_S : 56|8@1+ (1,0) [0|255] ""  MPC

BO_ 901 Media_0x385: 8 Vector__XXX
 SG_ RCTA_Enable_S : 6|2@1+ (1,0) [0|3] ""  MPC
 SG_ RCW_Enable_S : 8|2@1+ (1,0) [0|3] ""  MPC
 SG_ DOW_Enable_S : 10|2@1+ (1,0) [0|3] ""  MPC
 SG_ TJA_ICAwitch_S : 12|2@1+ (1,0) [0|3] ""  MPC
 SG_ RCTB_Enable_S : 22|2@1+ (1,0) [0|3] ""  MPC
 SG_ HMA_funtion_Swch_Signal_S : 24|2@1+ (1,0) [0|3] ""  MPC
 SG_ SLASwitch_Traffic_Sign_S : 26|2@1+ (1,0) [0|3] ""  MPC
 SG_ ADAS_Sensitivity_Req_S : 28|2@1+ (1,0) [0|3] ""  MPC
 SG_ PCW_Enable_S : 30|2@1+ (1,0) [0|3] ""  MPC
 SG_ LKS_Enable_S : 32|4@1+ (1,0) [0|15] ""  MPC
 SG_ AEB_Enable_S : 36|2@1+ (1,0) [0|3] ""  MPC
 SG_ LDW_Warning_Mode_S : 38|2@1+ (1,0) [0|3] ""  MPC
 SG_ LDW_Static_Calib_Instrct_S : 43|1@1+ (1,0) [0|1] ""  MPC
 SG_ SDWReq_Switch_State_S : 48|2@1+ (1,0) [0|3] ""  MPC
 SG_ PCW_Level_Set_S : 52|2@1+ (1,0) [0|3] ""  MPC
 SG_ LDW_Enable_S : 54|2@1+ (1,0) [0|3] ""  MPC
 SG_ SLA_SpdLimOffs_S : 56|4@1+ (1,0) [0|15] ""  MPC
 SG_ IntelligentSpdLimitAlarm_OnOff_S : 60|2@1+ (1,0) [0|3] ""  MPC
 SG_ ELKA_Enable_S : 62|2@1+ (1,0) [0|3] ""  MPC

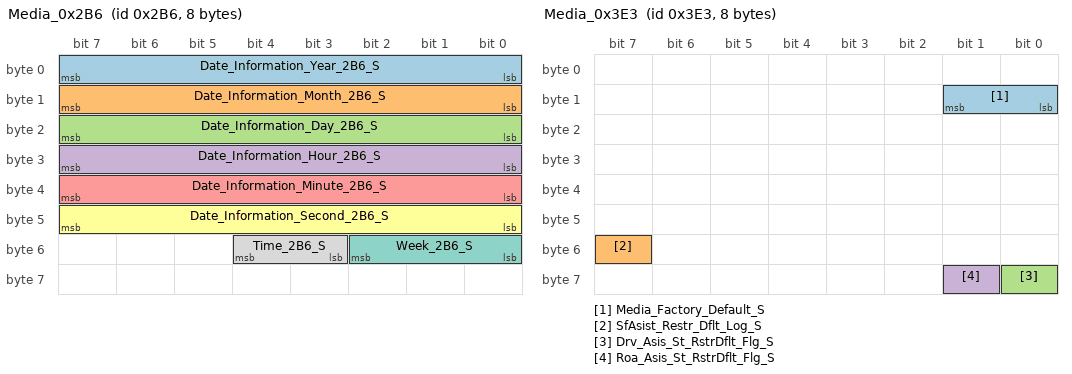
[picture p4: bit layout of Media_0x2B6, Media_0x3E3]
BO_ 694 Media_0x2B6: 8 Vector__XXX
 SG_ Date_Information_Year_2B6_S : 0|8@1+ (1,0) [0|255] ""  MPC
 SG_ Date_Information_Month_2B6_S : 8|8@1+ (1,0) [0|255] ""  MPC
 SG_ Date_Information_Day_2B6_S : 16|8@1+ (1,0) [0|255] ""  MPC
 SG_ Date_Information_Hour_2B6_S : 24|8@1+ (1,0) [0|255] ""  MPC
 SG_ Date_Information_Minute_2B6_S : 32|8@1+ (1,0) [0|255] ""  MPC
 SG_ Date_Information_Second_2B6_S : 40|8@1+ (1,0) [0|255] ""  MPC
 SG_ Week_2B6_S : 48|3@1+ (1,0) [0|7] ""  MPC
 SG_ Time_2B6_S : 51|2@1+ (1,0) [0|3] ""  MPC

BO_ 995 Media_0x3E3: 8 Vector__XXX
 SG_ Media_Factory_Default_S : 8|2@1+ (1,0) [0|3] ""  MPC
 SG_ SfAsist_Restr_Dflt_Log_S : 55|1@1+ (1,0) [0|1] ""  MPC
 SG_ Drv_Asis_St_RstrDflt_Flg_S : 56|1@1+ (1,0) [0|1] ""  MPC
 SG_ Roa_Asis_St_RstrDflt_Flg_S : 57|1@1+ (1,0) [0|1] ""  MPC

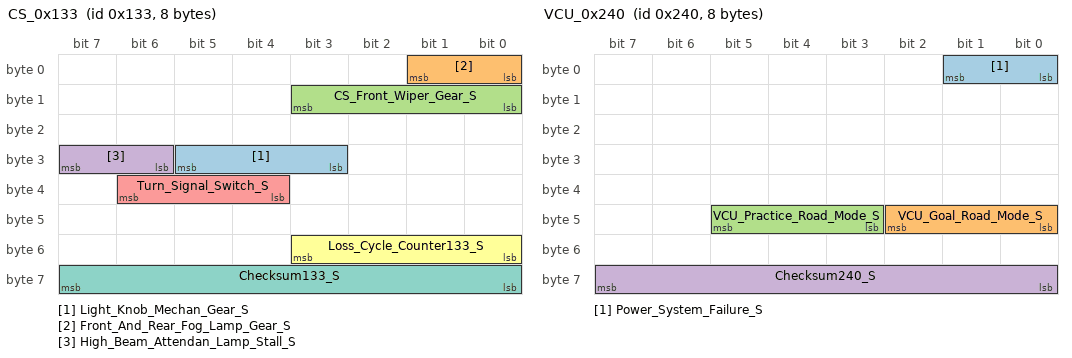
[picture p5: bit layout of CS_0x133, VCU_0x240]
BO_ 307 CS_0x133: 8 Vector__XXX
 SG_ Light_Knob_Mechan_Gear_S : 27|3@1+ (1,0) [0|7] ""  MPC
 SG_ Front_And_Rear_Fog_Lamp_Gear_S : 0|2@1+ (1,0) [0|3] ""  MPC
 SG_ CS_Front_Wiper_Gear_S : 8|4@1+ (1,0) [0|15] ""  MPC
 SG_ High_Beam_Attendan_Lamp_Stall_S : 30|2@1+ (1,0) [0|3] ""  MPC
 SG_ Turn_Signal_Switch_S : 36|3@1+ (1,0) [0|7] ""  MPC
 SG_ Loss_Cycle_Counter133_S : 48|4@1+ (1,0) [0|1] ""  MPC
 SG_ Checksum133_S : 56|8@1+ (1,0) [0|255] ""  MPC

BO_ 944 SWS_0x3B0: 8 Vector__XXX
 SG_ SWS_Dist_Set_S : 0|3@1+ (1,0) [0|1] ""  MPC
 SG_ SWS_Speed_Set_S : 3|3@1+ (1,0) [0|1] ""  MPC
 SG_ Dipilot_Switch_Signal_S : 6|2@1+ (1,0) [0|3] ""  MPC
 SG_ Cruise_Or_Speed_Limit_Mode_S : 8|2@1+ (1,0) [0|3] ""  MPC
 SG_ SWS_Reset_Signal_S : 10|2@1+ (1,0) [0|3] ""  MPC
 SG_ Cruis_Swch_Fault_Stat_flg_S : 12|2@1+ (1,0) [0|3] ""  MPC
 SG_ SWS_Set_Signal_S : 14|1@1+ (1,0) [0|1] ""  MPC
 SG_ Dist_Switch_Signal_Down_S : 15|1@1+ (1,0) [0|1] ""  MPC
 SG_ Dist_Switch_Signal_Up_S : 16|1@1+ (1,0) [0|1] ""  MPC
 SG_ SWS_Lane_Line_Assis_S : 17|1@1+ (1,0) [0|1] ""  MPC
 SG_ CruiseSw_Operation_Mode_S : 18|1@1+ (1,0) [0|1] ""  MPC
 SG_ ACC_Switch_Signal_S : 19|1@1+ (1,0) [0|1] ""  MPC
 SG_ HOD_System_Status_S : 20|3@1+ (1,0) [0|7] ""  MPC
 SG_ Driver_Grip_S : 24|3@1+ (1,0) [0|7] ""  MPC
 SG_ Driver_Grip_Area_S : 27|3@1+ (1,0) [0|7] ""  MPC
 SG_ Driver_SingleHands_State_S : 32|3@1+ (1,0) [0|7] ""  MPC
 SG_ Loss_Cycle_Counter3B0_S : 52|4@1+ (1,0) [0|1] ""  MPC
 SG_ CheckCode3B0_S : 56|8@1+ (1,0) [0|1] ""  MPC

BO_ 1193 SCPA_0x4A9: 8 Vector__XXX
 SG_ Lane_Departure_Key_S : 8|1@1+ (1,0) [0|1] ""  MPC

BO_ 576 VCU_0x240: 8 Vector__XXX
 SG_ Power_System_Failure_S : 0|2@1+ (1,0) [0|3] ""  MPC
 SG_ VCU_Goal_Road_Mode_S : 40|3@1+ (1,0) [0|7] ""  MPC
 SG_ VCU_Practice_Road_Mode_S : 43|3@1+ (1,0) [0|7] ""  MPC
 SG_ Checksum240_S : 56|8@1+ (1,0) [0|255] ""  MPC

BO_ 833 VCU_0x341: 8 Vector__XXX
 SG_ READY_Indicator_Light_S : 8|2@1+ (1,0) [0|3] ""  MPC
 SG_ Checksum341_S : 56|8@1+ (1,0) [0|255] ""  MPC

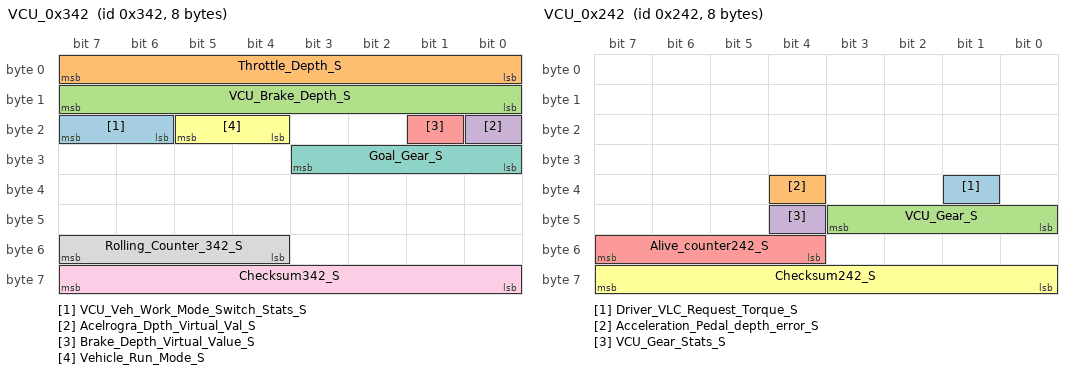
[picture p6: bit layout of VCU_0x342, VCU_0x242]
BO_ 834 VCU_0x342: 8 Vector__XXX
 SG_ VCU_Veh_Work_Mode_Switch_Stats_S : 22|2@1+ (1,0) [0|3] ""  MPC
 SG_ Throttle_Depth_S : 0|8@1+ (1,0) [0|100] "%"  MPC
 SG_ VCU_Brake_Depth_S : 8|8@1+ (1,0) [0|100] "%"  MPC
 SG_ Acelrogra_Dpth_Virtual_Val_S : 16|1@1+ (1,0) [0|1] ""  MPC
 SG_ Brake_Depth_Virtual_Value_S : 17|1@1+ (1,0) [0|1] ""  MPC
 SG_ Vehicle_Run_Mode_S : 20|2@1+ (1,0) [0|3] ""  MPC
 SG_ Goal_Gear_S : 24|4@1+ (1,0) [0|15] ""  MPC
 SG_ Rolling_Counter_342_S : 52|4@1+ (1,0) [0|15] ""  MPC
 SG_ Checksum342_S : 56|8@1+ (1,0) [0|255] ""  MPC

BO_ 578 VCU_0x242: 8 Vector__XXX
 SG_ Driver_VLC_Request_Torque_S : 33|1@1+ (1,0) [0|1] ""  MPC
 SG_ Acceleration_Pedal_depth_error_S : 36|1@1+ (1,0) [0|1] ""  MPC
 SG_ VCU_Gear_S : 40|4@1+ (1,0) [0|15] ""  MPC
 SG_ VCU_Gear_Stats_S : 44|1@1+ (1,0) [0|1] ""  MPC
 SG_ Alive_counter242_S : 52|4@1+ (1,0) [0|15] ""  MPC
 SG_ Checksum242_S : 56|8@1+ (1,0) [0|255] ""  MPC

CM_ "Matrix
Version：013
Date：2021/12/3";
CM_ BU_ MPC "包含MPC、MRR、ADAS";
CM_ BO_ 3221225472 "This is a message for not used signals, created by Vector CANdb++ DBC OLE DB Provider.";
CM_ SG_ 3221225472 The_Drv_Demand_Trq_Sign_S "驾驶员需求扭矩标记位";
CM_ SG_ 692 SLA_Output_Speed_Limit_S "限速报警输出速度限制
0x0：NoDisplay
0x1：SPLCancelled
0x2：SPL5
0x3：SPL10
0x4：SPL15
0x5：SPL20
0x6：SPL25
……
0x1B：SPL130
0x1C-0xFF：Reserved";
CM_ SG_ 692 MPC_SpdLimOffs_SLA_S "速度限值偏差
0x0：0
0x1：-10（KPH）
0x2：-5（KPH）
0x3：+5（KPH）
0x4：+10（KPH）
0x5：-5（MPH）
0x6：-3（MPH）
0x7：+3（MPH）
0x8：+5（MPH）
0x9-0xF：Reserved";
CM_ SG_ 692 SLA__Output_Speed_Limit_Unit_S "限速报警输出速度限制单位
0x0：Invalid
0x1：KMH
0x2：MPH
0x3：Reserved";
CM_ SG_ 692 ISLI_Sta_S "智能限速提示功能状态";
CM_ SG_ 692 ISLI_Warning_Status_S "智能限速提示报警
0x0: No Warning
0x1: Warning Level 1
0x2~0x3: Reserved";
CM_ SG_ 692 TSR_function_status_S "TSR交通识别状态
0x0：关
0x1：融合开启状态
0x2：仅视觉开启状态
0x3：仅导航开启状态
0x4：失效
0x5-0x7：Reserved";
CM_ SG_ 692 HMA_High_Beam_Request_S "HMA high beam requestHMA高亮请求";
CM_ SG_ 692 HMA_Stats_S "HMA statusHMA状态";
CM_ SG_ 1178 Medium_Checksum_49A_S "校验码
Checksum=(Byte1 Byte2… Byte7)XOR0xFF";
CM_ SG_ 1178 Medium_Enter_OTA_Mode_Req_S "进入OTA模式需求";
CM_ SG_ 801 Checksum321_S "校验码321
Checksum=(Byte1+Byte2?+Byte7)XOR0xFF";
CM_ SG_ 801 Message_Counter321_S "Message counter 321";
CM_ SG_ 801 IPB_Plunger_Pressure_S "IPB_PlungerPressure
Plunger压力";
CM_ SG_ 801 Gear_Hold_Request_S "档位保持请求
gearholdrequest";
CM_ SG_ 801 IPB_Plunger_Pres_status_S "IPB_PlungerPressure_status";
CM_ SG_ 801 IPB_Simulator_Pressure_Sts_S "IPB_SimulatorPressure_Sts
Simulator压力状态";
CM_ SG_ 801 IPB_Simulator_Pressure_S "IPB_SimulatorPressure
Simulator压力";
CM_ BO_ 308 "开启抑制Adas功能";
CM_ SG_ 308 APA_Auto_Parking_Status_S "APA_自动泊车状态";
CM_ SG_ 1263 PCW_Level_Req_S "预测性碰撞预警等级";
CM_ SG_ 1263 ISLC_Enable_S "智能限速控制开关";
CM_ SG_ 1263 Medium_0x4EF_ChilD_ID_S "0x33：子ID33";
CM_ SG_ 906 All_Weather_Lights_38A_S "全天候灯";
CM_ SG_ 906 Back_Fog_Light_38A_S "后雾灯";
CM_ SG_ 906 High_Beam_Light_38A_S "远光灯";
CM_ SG_ 906 Dipped_Headlight_38A_S "近光灯";
CM_ SG_ 836 BMC_Extn_Chag_Equp_Conec_Stat_S "动力电池管理器与外接充电设备当前状态(HEV、DM)";
CM_ SG_ 948 Frnt_windshield_humidity_Val_S "前挡风玻璃表面湿度值";
CM_ SG_ 948 Surface_Temp_Frnt_Windshield_S "前挡风玻璃表面温度值";
CM_ SG_ 948 GLT_Of_880WL_S "880nm波长玻璃透光率";
CM_ SG_ 948 Left_Sunshine_Intensity_S "左日照强度值";
CM_ SG_ 948 Right_Sunshine_Intensity_S "右日照强度值";
CM_ SG_ 948 IR_Brightness_S "IR_Brightness（红外光）";
CM_ SG_ 948 FW_Brightness_S "FW_Brightness（前照光）";
CM_ SG_ 948 Rainfall_Values_S "雨量值";
CM_ SG_ 948 Sun_Sensor_Hardware_Fault_S "阳光传感器硬件故障";
CM_ SG_ 948 Humidity_Sensor_Fault_Sign_S "湿度传感器故障信号";
CM_ SG_ 660 Left_Front_Door_Status_294_S "左前门状态";
CM_ SG_ 660 Right_Front_Door_Status_294_S "右前门状态";
CM_ SG_ 660 Left_Back_Door_Status_294_S "左后门状态";
CM_ SG_ 660 Right_Back_Door_Status_294_S "右后门状态";
CM_ SG_ 660 LeftF_Door_Stats_Valid_Bit_S "左前门状态有效位";
CM_ SG_ 660 RightF_Door_Sts_Valid_Bit_294_S "右前门状态有效位";
CM_ SG_ 660 LeftR_Door_Stats_Valid_Bit_S "左后门状态有效位";
CM_ SG_ 660 RightR_Door_Sts_Valid_Bit_294_S "右后门状态有效位";
CM_ SG_ 660 Driver_Belt_Stat_Effective_Bit_S "驾驶员安全带状态有效位";
CM_ SG_ 660 Back_Door_Sts_Effectiv_Bit_294_S "后背门状态有效位";
CM_ SG_ 660 Frnt_Hatch_Stat_Effective_Bit_S "前舱盖状态有效位";
CM_ SG_ 660 Emergency_Alarm_Effective_Bit_S "紧急告警状态标志";
CM_ SG_ 660 Driver_Belt_Status_S "驾驶员安全带状态";
CM_ SG_ 660 Back_Door_Status_294_S "后背门状态";
CM_ SG_ 660 Former_Hatch_Status_294_S "前舱盖状态";
CM_ SG_ 660 Emergency_Alarm_Status_S "紧急告警状态";
CM_ SG_ 660 Rolling_counter_294_S "滚动计数器";
CM_ SG_ 660 Checksum_294_S "校验码";
CM_ SG_ 301 BCMPower_Gear_12D_S "电源档位";
CM_ SG_ 301 Rolling_Counter_12D_S "滚动计数器";
CM_ SG_ 301 Checksum_12D_S "校验码";
CM_ SG_ 1141 Wiper_Speed_S "前雨刮速度";
CM_ SG_ 985 Child_ID_3D9_S "子ID_3D9";
CM_ SG_ 985 Total_Distance_3D9s5_S "总里程";
CM_ SG_ 1189 Child_ID_4A5_S "子ID_4A5";
CM_ SG_ 1189 Total_Distance_4A5_S "总里程";
CM_ SG_ 1189 Mileage_Unit_4A5_S "里程单位";
CM_ SG_ 337 Speed_Signal_151_S "车速信号";
CM_ SG_ 337 Speed_Unit_Setting_151_S "车速单位设置";
CM_ SG_ 337 Rolling_Counter_151_S "滚动计数器";
CM_ SG_ 337 Checksum_151_S "校验码";
CM_ SG_ 803 INS_Show_Fault_323_S "仪表显示故障";
CM_ SG_ 1028 Temperature_Conversion_S "温度转换";
CM_ SG_ 1028 ACHMC_Outside_Temperature_S "车外温度";
CM_ SG_ 1028 Rolling_Counter_0x404_S "丢包控制循环计数器";
CM_ SG_ 536 EPB_Switch_Status_S "EPB开关状态
Ele_Park_Brake_Switch_Status_S";
CM_ SG_ 536 EPB_Status_S "EPB状态";
CM_ SG_ 536 DrvOrOthFcnReqEPBOverride_S "驾驶员/其他功能请求干预EPB 标记位";
CM_ SG_ 536 Rolling_Counter_218_S "滚动计数器";
CM_ SG_ 536 Checksum_218_S "校验码";
CM_ SG_ 901 RCTA_Enable_S "倒车预警";
CM_ SG_ 901 RCW_Enable_S "后碰预警";
CM_ SG_ 901 DOW_Enable_S "开门预警";
CM_ SG_ 901 TJA_ICAwitch_S "TJA/ICAwitch";
CM_ SG_ 901 RCTB_Enable_S "RCTB_Enable";
CM_ SG_ 901 HMA_funtion_Swch_Signal_S "智能远近光灯开关HMA_funtion_Switch_Signal_S";
CM_ SG_ 901 SLASwitch_Traffic_Sign_S "交通标志识别
TSR_Switch_S";
CM_ SG_ 901 ADAS_Sensitivity_Req_S "ADASSensitivityReq";
CM_ SG_ 901 PCW_Enable_S "PCW_Enable";
CM_ SG_ 901 LKS_Enable_S "车道辅助模式选择";
CM_ SG_ 901 AEB_Enable_S "AEB_Enable";
CM_ SG_ 901 LDW_Warning_Mode_S "车道偏离报警方式";
CM_ SG_ 901 LDW_Static_Calib_Instrct_S "LDW静态标定指令";
CM_ SG_ 901 SDWReq_Switch_State_S "侧边距离报警开关状态";
CM_ SG_ 901 PCW_Level_Set_S "预测性碰撞预警等级设置";
CM_ SG_ 901 LDW_Enable_S "车道偏离模式开关";
CM_ SG_ 901 SLA_SpdLimOffs_S "ISLI超速报警偏差设置
ISLI_SpdLimOffs_S";
CM_ SG_ 901 IntelligentSpdLimitAlarm_OnOff_S "ISLI限速报警开关ISLI_Switch_S";
CM_ SG_ 901 ELKA_Enable_S "紧急车道偏离辅助功能";
CM_ SG_ 694 Date_Information_Year_2B6_S "日期信息：年";
CM_ SG_ 694 Date_Information_Month_2B6_S "日期信息：月";
CM_ SG_ 694 Date_Information_Day_2B6_S "日期信息：日";
CM_ SG_ 694 Date_Information_Hour_2B6_S "时间信息：时";
CM_ SG_ 694 Date_Information_Minute_2B6_S "时间信息：分";
CM_ SG_ 694 Date_Information_Second_2B6_S "时间信息：秒";
CM_ SG_ 694 Week_2B6_S "星期";
CM_ SG_ 694 Time_2B6_S "时制";
CM_ SG_ 995 Media_Factory_Default_S "恢复出厂设置";
CM_ SG_ 995 SfAsist_Restr_Dflt_Log_S "安全辅助设置恢复默认标志位";
CM_ SG_ 995 Drv_Asis_St_RstrDflt_Flg_S "行车辅助设置恢复默认标志位";
CM_ SG_ 995 Roa_Asis_St_RstrDflt_Flg_S "车道辅助设置恢复默认标志位";
CM_ SG_ 307 Light_Knob_Mechan_Gear_S "灯光旋钮当前机械结构处于的档位";
CM_ SG_ 307 Front_And_Rear_Fog_Lamp_Gear_S "前后雾灯档位";
CM_ SG_ 307 CS_Front_Wiper_Gear_S "前雨刮档位";
CM_ SG_ 307 High_Beam_Attendan_Lamp_Stall_S "远光与会车灯档位";
CM_ SG_ 307 Turn_Signal_Switch_S "转向灯开关";
CM_ SG_ 307 Loss_Cycle_Counter133_S "丢包循环计数器";
CM_ SG_ 307 Checksum133_S "校验码";
CM_ SG_ 944 SWS_Dist_Set_S "距离设置";
CM_ SG_ 944 SWS_Speed_Set_S "速度设置";
CM_ SG_ 944 Dipilot_Switch_Signal_S "Dipilot开关信号";
CM_ SG_ 944 Cruise_Or_Speed_Limit_Mode_S "巡航/限速模式
SWS_Cruise_Or_Speed_Limit_Mode_S";
CM_ SG_ 944 SWS_Reset_Signal_S "复位信号";
CM_ SG_ 944 Cruis_Swch_Fault_Stat_flg_S "巡航开关故障状态标志
SWS_Cruis_Swch_Fault_Stat_flg_S";
CM_ SG_ 944 SWS_Set_Signal_S "SET信号";
CM_ SG_ 944 Dist_Switch_Signal_Down_S "距离开关信号减SWS_Dist_Switch_Signal_Down_S　";
CM_ SG_ 944 Dist_Switch_Signal_Up_S "距离开关信号加SWS_Dist_Switch_Signal_Up_S";
CM_ SG_ 944 SWS_Lane_Line_Assis_S "车道线辅助";
CM_ SG_ 944 CruiseSw_Operation_Mode_S "巡航开关操作方式
Cruise_Switch_Operation_Mode_S";
CM_ SG_ 944 ACC_Switch_Signal_S "Acc开关信号";
CM_ SG_ 944 HOD_System_Status_S "HOD 系统状态";
CM_ SG_ 944 Driver_Grip_S "驾驶员手握状态";
CM_ SG_ 944 Driver_Grip_Area_S "驾驶员手握区域";
CM_ SG_ 944 Driver_SingleHands_State_S "驾驶员单/双手状态";
CM_ SG_ 944 Loss_Cycle_Counter3B0_S "丢包循环计数器";
CM_ SG_ 944 CheckCode3B0_S "校验码";
CM_ SG_ 1193 Lane_Departure_Key_S "车道偏移按键";
CM_ SG_ 576 Power_System_Failure_S "动力系统故障";
CM_ SG_ 576 VCU_Goal_Road_Mode_S "目标路面模式";
CM_ SG_ 576 VCU_Practice_Road_Mode_S "实际路面模式";
CM_ SG_ 576 Checksum240_S "校验码";
CM_ BO_ 833 "纯电VCU按100ms周期发送";
CM_ SG_ 833 READY_Indicator_Light_S "READY指示灯VCU_READY_Indicator_Light_S　";
CM_ SG_ 833 Checksum341_S "校验码";
CM_ SG_ 834 VCU_Veh_Work_Mode_Switch_Stats_S "整车工作模式切换状态
VCU_Veh_Work_Mode_Switch_Stats_S";
CM_ SG_ 834 Throttle_Depth_S "油门深度VCU_Accelerograph_Depth_S　";
CM_ SG_ 834 VCU_Brake_Depth_S "制动深度";
CM_ SG_ 834 Acelrogra_Dpth_Virtual_Val_S "油门深度有效位
VCU_Acelrogra_Dpth_Virtual_Val_S";
CM_ SG_ 834 Brake_Depth_Virtual_Value_S "制动深度有效位
VCU_Brake_Depth_Virtual_Value_S";
CM_ SG_ 834 Vehicle_Run_Mode_S "整车运行模式VCU_Vehicle_Run_Mode_S";
CM_ SG_ 834 Goal_Gear_S "目标档位VCU_Goal_Gear_S";
CM_ SG_ 834 Rolling_Counter_342_S "循环丢包计数器";
CM_ SG_ 834 Checksum342_S "校验码";
CM_ SG_ 578 Driver_VLC_Request_Torque_S "驾驶员请求扭矩超出VLC请求扭矩VCU_Driver_VLC_Request_Torque_S　";
CM_ SG_ 578 Acceleration_Pedal_depth_error_S "油门深度错误
Acceleration_Pedal_depth_error_S";
CM_ SG_ 578 VCU_Gear_S "档位";
CM_ SG_ 578 VCU_Gear_Stats_S "档位状态";
CM_ SG_ 578 Alive_counter242_S "循环计数器";
CM_ SG_ 578 Checksum242_S "校验码";
BA_DEF_ BO_  "CANFD_BRS" ENUM  "0","1";
BA_DEF_  "DBName" STRING ;
BA_DEF_  "BusType" STRING ;
BA_DEF_ BO_  "VFrameFormat" ENUM  "StandardCAN","ExtendedCAN","reserved","reserved","reserved","reserved","reserved","reserved","reserved","reserved","reserved","reserved","reserved","reserved","StandardCAN_FD","ExtendedCAN_FD";
BA_DEF_ BO_  "GenMsgSendType" ENUM  "Cycle","Event","CE","NoSendType","IfActive";
BA_DEF_ BO_  "GenMsgCycleTime" INT 0 1000;
BA_DEF_ BO_  "GenMsgCycleTimeFast" INT 0 1000;
BA_DEF_ SG_  "GenSigStartValue" HEX 0 4294967295;
BA_DEF_ SG_  "GenSigInvalidValue" HEX 0 4294967295;
BA_DEF_ SG_  "SignalPosition" STRING ;
BA_DEF_ SG_  "SignalValueDescription" STRING ;
BA_DEF_DEF_  "CANFD_BRS" "0";
BA_DEF_DEF_  "DBName" "";
BA_DEF_DEF_  "BusType" "";
BA_DEF_DEF_  "VFrameFormat" "StandardCAN";
BA_DEF_DEF_  "GenMsgSendType" "Cycle";
BA_DEF_DEF_  "GenMsgCycleTime" 1.56548806558447E-315;
BA_DEF_DEF_  "GenMsgCycleTimeFast" 0;
BA_DEF_DEF_  "GenSigStartValue" 0;
BA_DEF_DEF_  "GenSigInvalidValue" 0;
BA_DEF_DEF_  "SignalPosition" "";
BA_DEF_DEF_  "SignalValueDescription" "";
BA_ "BusType" "CAN FD";
BA_ "DBName" "Vehicle_CAN";
BA_ "CANFD_BRS" BO_ 692 1;
BA_ "GenMsgCycleTime" BO_ 692 50;
BA_ "VFrameFormat" BO_ 692 14;
BA_ "CANFD_BRS" BO_ 1178 1;
BA_ "GenMsgSendType" BO_ 1178 2;
BA_ "GenMsgCycleTime" BO_ 1178 1000;
BA_ "GenMsgCycleTimeFast" BO_ 1178 100;
BA_ "VFrameFormat" BO_ 1178 14;
BA_ "CANFD_BRS" BO_ 801 1;
BA_ "GenMsgCycleTime" BO_ 801 20;
BA_ "VFrameFormat" BO_ 801 14;
BA_ "CANFD_BRS" BO_ 308 1;
BA_ "GenMsgCycleTime" BO_ 308 20;
BA_ "VFrameFormat" BO_ 308 14;
BA_ "CANFD_BRS" BO_ 1263 1;
BA_ "GenMsgSendType" BO_ 1263 1;
BA_ "VFrameFormat" BO_ 1263 14;
BA_ "CANFD_BRS" BO_ 906 1;
BA_ "GenMsgSendType" BO_ 906 2;
BA_ "GenMsgCycleTime" BO_ 906 1000;
BA_ "GenMsgCycleTimeFast" BO_ 906 100;
BA_ "VFrameFormat" BO_ 906 14;
BA_ "CANFD_BRS" BO_ 836 1;
BA_ "GenMsgCycleTime" BO_ 836 100;
BA_ "VFrameFormat" BO_ 836 14;
BA_ "GenMsgSendType" BO_ 948 2;
BA_ "GenMsgCycleTimeFast" BO_ 948 100;
BA_ "GenMsgCycleTime" BO_ 948 1000;
BA_ "VFrameFormat" BO_ 948 14;
BA_ "CANFD_BRS" BO_ 660 1;
BA_ "GenMsgCycleTime" BO_ 660 50;
BA_ "VFrameFormat" BO_ 660 14;
BA_ "CANFD_BRS" BO_ 301 1;
BA_ "GenMsgCycleTime" BO_ 301 50;
BA_ "VFrameFormat" BO_ 301 14;
BA_ "CANFD_BRS" BO_ 1141 1;
BA_ "GenMsgSendType" BO_ 1141 2;
BA_ "GenMsgCycleTimeFast" BO_ 1141 100;
BA_ "GenMsgCycleTime" BO_ 1141 1000;
BA_ "VFrameFormat" BO_ 1141 14;
BA_ "CANFD_BRS" BO_ 985 1;
BA_ "GenMsgCycleTime" BO_ 985 1000;
BA_ "VFrameFormat" BO_ 985 14;
BA_ "GenMsgCycleTime" BO_ 1189 1000;
BA_ "VFrameFormat" BO_ 1189 14;
BA_ "CANFD_BRS" BO_ 337 1;
BA_ "GenMsgCycleTime" BO_ 337 100;
BA_ "VFrameFormat" BO_ 337 14;
BA_ "CANFD_BRS" BO_ 803 1;
BA_ "GenMsgCycleTime" BO_ 803 100;
BA_ "VFrameFormat" BO_ 803 14;
BA_ "CANFD_BRS" BO_ 1028 1;
BA_ "GenMsgSendType" BO_ 1028 2;
BA_ "GenMsgCycleTimeFast" BO_ 1028 100;
BA_ "GenMsgCycleTime" BO_ 1028 1000;
BA_ "VFrameFormat" BO_ 1028 14;
BA_ "CANFD_BRS" BO_ 536 1;
BA_ "GenMsgCycleTime" BO_ 536 20;
BA_ "VFrameFormat" BO_ 536 14;
BA_ "CANFD_BRS" BO_ 901 1;
BA_ "GenMsgSendType" BO_ 901 1;
BA_ "GenMsgCycleTime" BO_ 901 100;
BA_ "VFrameFormat" BO_ 901 14;
BA_ "CANFD_BRS" BO_ 694 1;
BA_ "GenMsgCycleTime" BO_ 694 500;
BA_ "VFrameFormat" BO_ 694 14;
BA_ "CANFD_BRS" BO_ 995 1;
BA_ "GenMsgSendType" BO_ 995 1;
BA_ "GenMsgCycleTime" BO_ 995 100;
BA_ "VFrameFormat" BO_ 995 14;
BA_ "CANFD_BRS" BO_ 307 1;
BA_ "GenMsgCycleTime" BO_ 307 50;
BA_ "VFrameFormat" BO_ 307 14;
BA_ "CANFD_BRS" BO_ 944 1;
BA_ "GenMsgCycleTime" BO_ 944 50;
BA_ "VFrameFormat" BO_ 944 14;
BA_ "GenMsgSendType" BO_ 1193 2;
BA_ "GenMsgCycleTimeFast" BO_ 1193 100;
BA_ "GenMsgCycleTime" BO_ 1193 1000;
BA_ "VFrameFormat" BO_ 1193 14;
BA_ "CANFD_BRS" BO_ 576 1;
BA_ "GenMsgCycleTime" BO_ 576 100;
BA_ "VFrameFormat" BO_ 576 14;
BA_ "CANFD_BRS" BO_ 833 1;
BA_ "GenMsgCycleTime" BO_ 833 100;
BA_ "VFrameFormat" BO_ 833 14;
BA_ "CANFD_BRS" BO_ 834 1;
BA_ "GenMsgCycleTime" BO_ 834 20;
BA_ "VFrameFormat" BO_ 834 14;
BA_ "CANFD_BRS" BO_ 578 1;
BA_ "GenMsgCycleTime" BO_ 578 20;
BA_ "VFrameFormat" BO_ 578 14;
BA_ "SignalValueDescription" SG_ 3221225472 The_Drv_Demand_Trq_Sign_S "0x0：No Override

0x1：Driver Override";
BA_ "SignalPosition" SG_ 3221225472 The_Drv_Demand_Trq_Sign_S "2.6";
BA_ "SignalPosition" SG_ 692 SLA_Output_Speed_Limit_S "4.0-4.7";
BA_ "SignalValueDescription" SG_ 692 SLA_Output_Speed_Limit_S "0x0:NoDisplay

0x1:SPLCancelled

0x2:SPL5

0x3:SPL10

0x4:SPL15

0x5:SPL20

0x6:SPL25



0x1B:SPL130

0x1C-0xFF:Reserved";
BA_ "SignalPosition" SG_ 692 MPC_SpdLimOffs_SLA_S "3.4-3.7";
BA_ "SignalValueDescription" SG_ 692 MPC_SpdLimOffs_SLA_S "0x0:0

0x1:10KPH

0x2:5KPH

0x3:+5KPH

0x4:+10KPH

0x5:5MPH

0x6:3MPH

0x7:+3MPH

0x8:+5MPH

0x9-0xF:Reserved";
BA_ "SignalPosition" SG_ 692 SLA__Output_Speed_Limit_Unit_S "3.2-3.3";
BA_ "SignalValueDescription" SG_ 692 SLA__Output_Speed_Limit_Unit_S "0x0:Invalid

0x1:KMH

0x2:MPH

0x3:Reserved";
BA_ "SignalPosition" SG_ 692 ISLI_Sta_S "3.0";
BA_ "SignalValueDescription" SG_ 692 ISLI_Sta_S "0x0：OFF

0x1：ON";
BA_ "SignalPosition" SG_ 692 ISLI_Warning_Status_S "2.6-2.7";
BA_ "SignalValueDescription" SG_ 692 ISLI_Warning_Status_S "0x0:NoWarning

0x1:WarningLevel1

0x2~0x3:Reserved";
BA_ "SignalPosition" SG_ 692 TSR_function_status_S "1.5-1.7";
BA_ "SignalValueDescription" SG_ 692 TSR_function_status_S "0x0：Off

0x1：FusionMode

0x2：VisionMode

0x3：NavigationOnlyMode

0x4：Fault

0x5-0x7：Reserved";
BA_ "GenSigInvalidValue" SG_ 692 HMA_High_Beam_Request_S 15;
BA_ "SignalValueDescription" SG_ 692 HMA_High_Beam_Request_S "0x0：LowBeam Request

0x1：HighBeam Request";
BA_ "SignalPosition" SG_ 692 HMA_High_Beam_Request_S "1.3";
BA_ "GenSigInvalidValue" SG_ 692 HMA_Stats_S 15;
BA_ "SignalValueDescription" SG_ 692 HMA_Stats_S "0x0：Off

0x1：Passive

0x2：Standby

0x3：Active

0x4：Fault

0x5：Camera Blocked

0x6-0x7：Reserved";
BA_ "SignalPosition" SG_ 692 HMA_Stats_S "1.0-1.2";
BA_ "SignalPosition" SG_ 1178 Medium_Checksum_49A_S "8.0-8.7";
BA_ "SignalValueDescription" SG_ 1178 Medium_Checksum_49A_S "Checksum=(Byte1+Byte2…+Byte7)XOR0xFF";
BA_ "SignalPosition" SG_ 1178 Medium_Enter_OTA_Mode_Req_S "1.4";
BA_ "SignalValueDescription" SG_ 1178 Medium_Enter_OTA_Mode_Req_S "0x0：OTA结束，正常模式

0x1：整车进入OTA模式";
BA_ "SignalPosition" SG_ 801 Checksum321_S "8.0-8.7";
BA_ "SignalValueDescription" SG_ 801 Checksum321_S "Checksum=(Byte1+Byte2?+Byte7)XOR0xFF";
BA_ "SignalPosition" SG_ 801 Message_Counter321_S "7.4-7.7";
BA_ "SignalValueDescription" SG_ 801 Message_Counter321_S "PH=INT*1

PH∈[0，15]";
BA_ "GenSigStartValue" SG_ 801 IPB_Plunger_Pressure_S 17;
BA_ "SignalPosition" SG_ 801 IPB_Plunger_Pressure_S "3.0-4.3";
BA_ "SignalValueDescription" SG_ 801 IPB_Plunger_Pressure_S "PH=INT*0.3-5

[-5，301.9]bar

[0x000，0x3FE]

Initial：0x011";
BA_ "SignalPosition" SG_ 801 Gear_Hold_Request_S "2.6";
BA_ "SignalValueDescription" SG_ 801 Gear_Hold_Request_S "0x0：Shifting Not Suppressed

0x1：Shifting Suppressed";
BA_ "SignalPosition" SG_ 801 IPB_Plunger_Pres_status_S "2.5";
BA_ "SignalValueDescription" SG_ 801 IPB_Plunger_Pres_status_S "0x0：Valid

0x1：Invalid";
BA_ "SignalPosition" SG_ 801 IPB_Simulator_Pressure_Sts_S "2.4";
BA_ "SignalValueDescription" SG_ 801 IPB_Simulator_Pressure_Sts_S "0x0：Valid

0x1：Invalid";
BA_ "SignalPosition" SG_ 801 IPB_Simulator_Pressure_S "1.0-2.3";
BA_ "SignalValueDescription" SG_ 801 IPB_Simulator_Pressure_S "PH=INT*0.3-5

[-5，301.9]bar

[0x000，0x3FE]

Initial：0x011";
BA_ "SignalPosition" SG_ 308 APA_Auto_Parking_Status_S "1.0-1.2";
BA_ "SignalValueDescription" SG_ 308 APA_Auto_Parking_Status_S "0x0：Passive待机

0x1：寻车位中

0x2：泊车中

0x3：泊车暂停

0x4：泊车中(终)止（异常退出）

0x5：泊车完成

0x6：自动泊车不可用

0x7：准备就绪状态";
BA_ "SignalPosition" SG_ 1263 PCW_Level_Req_S "4.4-4.6";
BA_ "SignalValueDescription" SG_ 1263 PCW_Level_Req_S "0x0：Invalid

0x1：关闭

0x2：Level 1 低

0x3：Level 2 中(默认选择)

0x4：Level 3 高

0x5-0x7：预留";
BA_ "GenSigStartValue" SG_ 1263 PCW_Level_Req_S 3;
BA_ "SignalPosition" SG_ 1263 ISLC_Enable_S "3.0-3.1";
BA_ "SignalValueDescription" SG_ 1263 ISLC_Enable_S "0x0：Invalid

0x1：Switchoff

0x2：Switchon

0x3：Reserved";
BA_ "SignalPosition" SG_ 1263 Medium_0x4EF_ChilD_ID_S "1.0-1.7";
BA_ "SignalValueDescription" SG_ 1263 Medium_0x4EF_ChilD_ID_S "子ID_4EF";
BA_ "SignalPosition" SG_ 906 All_Weather_Lights_38A_S "2.6-2.7";
BA_ "SignalValueDescription" SG_ 906 All_Weather_Lights_38A_S "0x0：无效

0x1：点亮

0x2：熄灭

0x3：预留";
BA_ "SignalPosition" SG_ 906 Back_Fog_Light_38A_S "2.0-2.1";
BA_ "SignalValueDescription" SG_ 906 Back_Fog_Light_38A_S "0x0：无效

0x1：打开

0x2：关闭

0x3：预留?";
BA_ "SignalPosition" SG_ 906 High_Beam_Light_38A_S "1.4-1.5";
BA_ "SignalValueDescription" SG_ 906 High_Beam_Light_38A_S "0x0：无效

0x1：打开

0x2：关闭

0x3：预留?";
BA_ "SignalPosition" SG_ 906 Dipped_Headlight_38A_S "1.2-1.3";
BA_ "SignalValueDescription" SG_ 906 Dipped_Headlight_38A_S "0x0：无效

0x1：打开

0x2：关闭

0x3：预留";
BA_ "SignalPosition" SG_ 836 BMC_Extn_Chag_Equp_Conec_Stat_S "3.0-3.3";
BA_ "GenSigInvalidValue" SG_ 948 Frnt_windshield_humidity_Val_S 255;
BA_ "GenSigStartValue" SG_ 948 Frnt_windshield_humidity_Val_S 255;
BA_ "SignalValueDescription" SG_ 948 Frnt_windshield_humidity_Val_S "PH=INT*0.5%

INT∈[0x00，0xC8]

PH∈[0，100]%

初始值/无效值：0xFF";
BA_ "SignalPosition" SG_ 948 Frnt_windshield_humidity_Val_S "1.0-1.7";
BA_ "GenSigInvalidValue" SG_ 948 Surface_Temp_Frnt_Windshield_S 255;
BA_ "GenSigStartValue" SG_ 948 Surface_Temp_Frnt_Windshield_S 255;
BA_ "SignalValueDescription" SG_ 948 Surface_Temp_Frnt_Windshield_S "PH=INT*0.5-40℃

INT∈[0x00，0xFE]

PH∈[-40，87]℃

初始值/无效值：0xFF";
BA_ "SignalPosition" SG_ 948 Surface_Temp_Frnt_Windshield_S "2.0-2.7";
BA_ "GenSigInvalidValue" SG_ 948 GLT_Of_880WL_S 255;
BA_ "GenSigStartValue" SG_ 948 GLT_Of_880WL_S 43;
BA_ "SignalValueDescription" SG_ 948 GLT_Of_880WL_S "PH=INT* 1

PH∈[0，100] 

INT∈[0，100]

[0x0,0x64]

0x65-0xFE:reserved

0xFF:invalid

0x2B:intinal";
BA_ "SignalPosition" SG_ 948 GLT_Of_880WL_S "3.0-3.7";
BA_ "GenSigInvalidValue" SG_ 948 Left_Sunshine_Intensity_S 255;
BA_ "GenSigStartValue" SG_ 948 Left_Sunshine_Intensity_S 255;
BA_ "SignalValueDescription" SG_ 948 Left_Sunshine_Intensity_S "PH=INT*5w/m2

INT∈[0x00，0xFE]

PH∈[0，1270]w/m2

初始值/无效值：0xFF";
BA_ "SignalPosition" SG_ 948 Left_Sunshine_Intensity_S "4.0-4.7";
BA_ "GenSigInvalidValue" SG_ 948 Right_Sunshine_Intensity_S 255;
BA_ "GenSigStartValue" SG_ 948 Right_Sunshine_Intensity_S 255;
BA_ "SignalValueDescription" SG_ 948 Right_Sunshine_Intensity_S "PH=INT*5w/m2

INT∈[0x00，0xFE]

PH∈[0，1270]w/m2

初始值/无效值：0xFF";
BA_ "SignalPosition" SG_ 948 Right_Sunshine_Intensity_S "5.0-5.7";
BA_ "GenSigInvalidValue" SG_ 948 IR_Brightness_S 254;
BA_ "GenSigStartValue" SG_ 948 IR_Brightness_S 255;
BA_ "SignalValueDescription" SG_ 948 IR_Brightness_S "PH=INT*400w/m2

INT∈[0x00，0xFD]

PH∈[0，101600]w/m2

初始值：0xFF

无效值：0xFE";
BA_ "SignalPosition" SG_ 948 IR_Brightness_S "6.0-6.7";
BA_ "GenSigInvalidValue" SG_ 948 FW_Brightness_S 1022;
BA_ "GenSigStartValue" SG_ 948 FW_Brightness_S 1023;
BA_ "SignalValueDescription" SG_ 948 FW_Brightness_S "PH=INT*6Lux

INT∈[0x00，0x3FD]

PH∈[0，6126]Lux

初始值：0x3FF

无效值：0x3FE";
BA_ "SignalPosition" SG_ 948 FW_Brightness_S "7.0-8.1";
BA_ "GenSigInvalidValue" SG_ 948 Rainfall_Values_S 15;
BA_ "GenSigStartValue" SG_ 948 Rainfall_Values_S 15;
BA_ "SignalValueDescription" SG_ 948 Rainfall_Values_S "INT∈[0，14]

初始值：0xF

无效值：0xF";
BA_ "SignalPosition" SG_ 948 Rainfall_Values_S "8.2-8.5";
BA_ "SignalValueDescription" SG_ 948 Sun_Sensor_Hardware_Fault_S "0x0：无故障

0x1：有故障";
BA_ "SignalPosition" SG_ 948 Sun_Sensor_Hardware_Fault_S "8.6";
BA_ "SignalValueDescription" SG_ 948 Humidity_Sensor_Fault_Sign_S "0x0：无故障

0x1：有故障";
BA_ "SignalPosition" SG_ 948 Humidity_Sensor_Fault_Sign_S "8.7";
BA_ "SignalValueDescription" SG_ 660 Left_Front_Door_Status_294_S "0x0：无效

0x1：关闭

0x2：打开

0x3：预留

初始值/默认值：0x0";
BA_ "SignalPosition" SG_ 660 Left_Front_Door_Status_294_S "1.0-1.1";
BA_ "SignalValueDescription" SG_ 660 Right_Front_Door_Status_294_S "0x0：无效

0x1：关闭

0x2：打开

0x3：预留

初始值/默认值：0x0";
BA_ "SignalPosition" SG_ 660 Right_Front_Door_Status_294_S "1.2-1.3";
BA_ "SignalValueDescription" SG_ 660 Left_Back_Door_Status_294_S "0x0：无效

0x1：关闭

0x2：打开

0x3：预留

初始值/默认值：0x0";
BA_ "SignalPosition" SG_ 660 Left_Back_Door_Status_294_S "1.4-1.5";
BA_ "SignalValueDescription" SG_ 660 Right_Back_Door_Status_294_S "0x0：无效

0x1：关闭

0x2：打开

0x3：预留

初始值/默认值：0x0";
BA_ "SignalPosition" SG_ 660 Right_Back_Door_Status_294_S "1.6-1.7";
BA_ "SignalValueDescription" SG_ 660 LeftF_Door_Stats_Valid_Bit_S "0x0：有效

0x1：无效";
BA_ "SignalPosition" SG_ 660 LeftF_Door_Stats_Valid_Bit_S "2.0";
BA_ "SignalValueDescription" SG_ 660 RightF_Door_Sts_Valid_Bit_294_S "0x0：有效

0x1：无效";
BA_ "SignalPosition" SG_ 660 RightF_Door_Sts_Valid_Bit_294_S "2.1";
BA_ "SignalValueDescription" SG_ 660 LeftR_Door_Stats_Valid_Bit_S "0x0：有效

0x1：无效";
BA_ "SignalPosition" SG_ 660 LeftR_Door_Stats_Valid_Bit_S "2.2";
BA_ "SignalValueDescription" SG_ 660 RightR_Door_Sts_Valid_Bit_294_S "0x0：有效

0x1：无效";
BA_ "SignalPosition" SG_ 660 RightR_Door_Sts_Valid_Bit_294_S "2.3";
BA_ "SignalValueDescription" SG_ 660 Driver_Belt_Stat_Effective_Bit_S "0x0：有效

0x1：无效";
BA_ "SignalPosition" SG_ 660 Driver_Belt_Stat_Effective_Bit_S "2.4";
BA_ "SignalValueDescription" SG_ 660 Back_Door_Sts_Effectiv_Bit_294_S "0x0：有效

0x1：无效";
BA_ "SignalPosition" SG_ 660 Back_Door_Sts_Effectiv_Bit_294_S "2.5";
BA_ "SignalValueDescription" SG_ 660 Frnt_Hatch_Stat_Effective_Bit_S "0x0：有效

0x1：无效";
BA_ "SignalPosition" SG_ 660 Frnt_Hatch_Stat_Effective_Bit_S "2.6";
BA_ "SignalValueDescription" SG_ 660 Emergency_Alarm_Effective_Bit_S "0x0：有效

0x1：无效";
BA_ "SignalPosition" SG_ 660 Emergency_Alarm_Effective_Bit_S "2.7";
BA_ "SignalValueDescription" SG_ 660 Driver_Belt_Status_S "0x0：无效

0x1：解开

0x2：扣上

0x3：预留";
BA_ "SignalPosition" SG_ 660 Driver_Belt_Status_S "3.0-3.1";
BA_ "SignalValueDescription" SG_ 660 Back_Door_Status_294_S "0x0：无效

0x1：关闭

0x2：打开

0x3：预留

初始值/默认值：0x0";
BA_ "SignalPosition" SG_ 660 Back_Door_Status_294_S "3.2-3.3";
BA_ "SignalValueDescription" SG_ 660 Former_Hatch_Status_294_S "0x0：无效

0x1：关闭

0x2：打开

0x3：预留

初始值/默认值：0x0";
BA_ "SignalPosition" SG_ 660 Former_Hatch_Status_294_S "3.4-3.5";
BA_ "SignalValueDescription" SG_ 660 Emergency_Alarm_Status_S "0x0：无效

0x1：关闭

0x2：打开

0x3：预留

初始值/默认值：0x0";
BA_ "SignalPosition" SG_ 660 Emergency_Alarm_Status_S "3.6-3.7";
BA_ "SignalValueDescription" SG_ 660 Rolling_counter_294_S "PH∈[0，15]";
BA_ "SignalPosition" SG_ 660 Rolling_counter_294_S "7.0-7.3";
BA_ "SignalValueDescription" SG_ 660 Checksum_294_S "Checksum=(Byte1+Byte2?+Byte7)XOR0xFF";
BA_ "SignalPosition" SG_ 660 Checksum_294_S "8.0-8.7";
BA_ "SignalValueDescription" SG_ 301 BCMPower_Gear_12D_S "0x0：无效

0x1：OFF档

0x2：ACC档

0x3：ON档

0x4-0x7：预留";
BA_ "SignalPosition" SG_ 301 BCMPower_Gear_12D_S "5.2-5.4";
BA_ "SignalValueDescription" SG_ 301 Rolling_Counter_12D_S "[0，15]

初始值/默认值：0x0";
BA_ "SignalPosition" SG_ 301 Rolling_Counter_12D_S "7.4-7.7";
BA_ "SignalValueDescription" SG_ 301 Checksum_12D_S "Checksum=(Byte1+Byte2+…+Byte7)XOR0xFF";
BA_ "SignalPosition" SG_ 301 Checksum_12D_S "8.0-8.7";
BA_ "SignalValueDescription" SG_ 1141 Wiper_Speed_S "0x0：无效

0x1：停止

0x2：慢刮

0x3：快刮";
BA_ "SignalPosition" SG_ 1141 Wiper_Speed_S "4.2-4.3";
BA_ "GenSigInvalidValue" SG_ 985 Child_ID_3D9_S 1;
BA_ "GenSigStartValue" SG_ 985 Child_ID_3D9_S 1;
BA_ "SignalValueDescription" SG_ 985 Child_ID_3D9_S "0x01：子ID01";
BA_ "SignalPosition" SG_ 985 Child_ID_3D9_S "1.0-1.7";
BA_ "GenSigInvalidValue" SG_ 985 Total_Distance_3D9s5_S 134217727;
BA_ "GenSigStartValue" SG_ 985 Total_Distance_3D9s5_S 134217727;
BA_ "SignalValueDescription" SG_ 985 Total_Distance_3D9s5_S "PH=INT*0.1km

PH∈[0，9999999.9]

INT∈[0x0，0x5F5E0FF]

无效值：0x5F5E100-0x7FFFFFF

默认值：0x0";
BA_ "SignalPosition" SG_ 985 Total_Distance_3D9s5_S "2.0-5.2";
BA_ "GenSigInvalidValue" SG_ 1189 Child_ID_4A5_S 1;
BA_ "GenSigStartValue" SG_ 1189 Child_ID_4A5_S 1;
BA_ "SignalValueDescription" SG_ 1189 Child_ID_4A5_S "0x01";
BA_ "SignalPosition" SG_ 1189 Child_ID_4A5_S "1.0-1.7";
BA_ "GenSigInvalidValue" SG_ 1189 Total_Distance_4A5_S 134217727;
BA_ "GenSigStartValue" SG_ 1189 Total_Distance_4A5_S 134217727;
BA_ "SignalValueDescription" SG_ 1189 Total_Distance_4A5_S "PH=INT*0.1

PH∈[0，9999999.9]

INT∈[0x0，0x5F5E0FF]

无效：0x5F5E100-0x7FFFFFF

默认值：0x0";
BA_ "SignalPosition" SG_ 1189 Total_Distance_4A5_S "2.0-5.2";
BA_ "SignalValueDescription" SG_ 1189 Mileage_Unit_4A5_S "0x0：无效

0x1：km

0x2：mile

0x3：预留";
BA_ "SignalPosition" SG_ 1189 Mileage_Unit_4A5_S "5.3-5.4";
BA_ "GenSigInvalidValue" SG_ 337 Speed_Signal_151_S 255;
BA_ "SignalValueDescription" SG_ 337 Speed_Signal_151_S "PH=INT*1km/h

PH∈[0，240]km/h

INT∈[0x00，0xF0]

0xF1-0xFF：无效值

0x00：默认值";
BA_ "SignalPosition" SG_ 337 Speed_Signal_151_S "1.0-1.7";
BA_ "SignalValueDescription" SG_ 337 Speed_Unit_Setting_151_S "0x0：无效

0x1：Km/h

0x2：MPH

0x3：预留";
BA_ "SignalPosition" SG_ 337 Speed_Unit_Setting_151_S "2.0-2.1";
BA_ "SignalValueDescription" SG_ 337 Rolling_Counter_151_S "[0，15]";
BA_ "SignalPosition" SG_ 337 Rolling_Counter_151_S "7.4-7.7";
BA_ "SignalValueDescription" SG_ 337 Checksum_151_S "Checksum=(Byte1+Byte2…+Byte7)XOR0xFF";
BA_ "SignalPosition" SG_ 337 Checksum_151_S "8.0-8.7";
BA_ "SignalValueDescription" SG_ 803 INS_Show_Fault_323_S "0x0：正常

0x1：故障";
BA_ "SignalPosition" SG_ 803 INS_Show_Fault_323_S "1.7";
BA_ "SignalValueDescription" SG_ 1028 Temperature_Conversion_S "0x0：摄氏设定温度

0x1：华氏设定温度";
BA_ "SignalPosition" SG_ 1028 Temperature_Conversion_S "4.7";
BA_ "SignalValueDescription" SG_ 1028 ACHMC_Outside_Temperature_S "1）车外温度显示(℃)：

PH=INT*1-0x80℃

INT∈[0x58，0xB2]

PH∈[-40，50]℃

2）车外温度显示(℉)：

PH=INT*1-0x28℉

INT∈[0x0，0xA2]

PH∈[-40，122]℉

0xD0和0xD8为故障代码，显示--；

未接受到此报文，不显示。";
BA_ "SignalPosition" SG_ 1028 ACHMC_Outside_Temperature_S "7.0-7.7";
BA_ "SignalValueDescription" SG_ 1028 Rolling_Counter_0x404_S "0x0-0xF";
BA_ "SignalPosition" SG_ 1028 Rolling_Counter_0x404_S "8.4-8.7";
BA_ "SignalValueDescription" SG_ 536 EPB_Switch_Status_S "0x0：Not Active

0x1：Release

0x2：Apply

0x3：Reserved";
BA_ "SignalPosition" SG_ 536 EPB_Switch_Status_S "1.0-1.1";
BA_ "GenSigInvalidValue" SG_ 536 EPB_Status_S 7;
BA_ "GenSigStartValue" SG_ 536 EPB_Status_S 7;
BA_ "SignalValueDescription" SG_ 536 EPB_Status_S "0x0：Releasing

0x1：Released

0x2：Applying

0x3：Applied

0x4：Fault（禁止遥控驾驶）

0x5：维修释放状态

0x6-0x7：预留";
BA_ "SignalPosition" SG_ 536 EPB_Status_S "2.1-2.3";
BA_ "SignalValueDescription" SG_ 536 DrvOrOthFcnReqEPBOverride_S "0x0：False

0x1：True";
BA_ "SignalPosition" SG_ 536 DrvOrOthFcnReqEPBOverride_S "3.3";
BA_ "SignalValueDescription" SG_ 536 Rolling_Counter_218_S "PH=INT*1[-]

[0，15]";
BA_ "SignalPosition" SG_ 536 Rolling_Counter_218_S "7.0-7.3";
BA_ "SignalValueDescription" SG_ 536 Checksum_218_S "Checksum=(Byte1+byte2…+Byte7)XOR0xFF";
BA_ "SignalPosition" SG_ 536 Checksum_218_S "8.0-8.7";
BA_ "SignalValueDescription" SG_ 901 RCTA_Enable_S "0x0：Invalid

0x1：Switchoff

0x2：Switchon

0x3：Reserved";
BA_ "SignalPosition" SG_ 901 RCTA_Enable_S "1.6-1.7";
BA_ "SignalValueDescription" SG_ 901 RCW_Enable_S "0x0：Invalid

0x1：Switchoff

0x2：Switchon

0x3：Reserved";
BA_ "SignalPosition" SG_ 901 RCW_Enable_S "2.0-2.1";
BA_ "SignalValueDescription" SG_ 901 DOW_Enable_S "0x0：Invalid

0x1：Switchoff

0x2：Switchon

0x3：Reserved";
BA_ "SignalPosition" SG_ 901 DOW_Enable_S "2.2-2.3";
BA_ "GenSigStartValue" SG_ 901 TJA_ICAwitch_S 2;
BA_ "SignalValueDescription" SG_ 901 TJA_ICAwitch_S "0x0：Invalid

0x1：Switchoff

0x2：Switchon

0x3：Reserved";
BA_ "SignalPosition" SG_ 901 TJA_ICAwitch_S "2.4-2.5";
BA_ "SignalValueDescription" SG_ 901 RCTB_Enable_S "0x0：Invalid

0x1：Switchoff

0x2：Switchon

0x3：Reserved";
BA_ "SignalPosition" SG_ 901 RCTB_Enable_S "3.6-3.7";
BA_ "SignalValueDescription" SG_ 901 HMA_funtion_Swch_Signal_S "0x0：Invalid

0x1：HMAnotselected

0x2：HMAselected

0x3：Reserved";
BA_ "SignalPosition" SG_ 901 HMA_funtion_Swch_Signal_S "4.0-4.1";
BA_ "SignalValueDescription" SG_ 901 SLASwitch_Traffic_Sign_S "0x0：Invalid

0x1：Switchoff

0x2：Switchon

0x3：Reserved";
BA_ "SignalPosition" SG_ 901 SLASwitch_Traffic_Sign_S "4.2-4.3";
BA_ "SignalValueDescription" SG_ 901 ADAS_Sensitivity_Req_S "0x0：Invalid

0x1：lowSensitivity

0x2：highSensitivity

0x3：Reserved";
BA_ "SignalPosition" SG_ 901 ADAS_Sensitivity_Req_S "4.4-4.5";
BA_ "SignalValueDescription" SG_ 901 PCW_Enable_S "0x0：Invalid

0x1：Switchoff

0x2：Switchon

0x3：Reserved";
BA_ "SignalPosition" SG_ 901 PCW_Enable_S "4.6-4.7";
BA_ "SignalValueDescription" SG_ 901 LKS_Enable_S "0x0：无效

0x1：关闭

0x2：车道偏离

0x3：车道保持

0x4：全功能

0x5：车辆纠偏

0x6-0xF：Reserved";
BA_ "SignalPosition" SG_ 901 LKS_Enable_S "5.0-5.3";
BA_ "SignalValueDescription" SG_ 901 AEB_Enable_S "0x0：Invalid

0x1：switchoff

0x2：switchon

0x3：Reserved";
BA_ "SignalPosition" SG_ 901 AEB_Enable_S "5.4-5.5";
BA_ "SignalValueDescription" SG_ 901 LDW_Warning_Mode_S "0x0：无效

0x1：仅振动

0x2：仅声音

0x3：振动+声音";
BA_ "SignalPosition" SG_ 901 LDW_Warning_Mode_S "5.6-5.7";
BA_ "SignalValueDescription" SG_ 901 LDW_Static_Calib_Instrct_S "0x0：无效

0x1：开始";
BA_ "SignalPosition" SG_ 901 LDW_Static_Calib_Instrct_S "6.3";
BA_ "GenSigStartValue" SG_ 901 SDWReq_Switch_State_S 2;
BA_ "SignalValueDescription" SG_ 901 SDWReq_Switch_State_S "0x0：Invalid

0x1：Switchoff

0x2：Switchon

0x3：Reserved";
BA_ "SignalPosition" SG_ 901 SDWReq_Switch_State_S "7.0-7.1";
BA_ "GenSigInvalidValue" SG_ 901 PCW_Level_Set_S 2;
BA_ "GenSigStartValue" SG_ 901 PCW_Level_Set_S 2;
BA_ "SignalValueDescription" SG_ 901 PCW_Level_Set_S "0x0：No Action

0x1：Level 1 低

0x2：Level 2 中(默认选择)

0x3：Level 3 高";
BA_ "SignalPosition" SG_ 901 PCW_Level_Set_S "7.4-7.5";
BA_ "SignalValueDescription" SG_ 901 LDW_Enable_S "0x0：无效

0x1：关闭

0x2：车道偏离

0x3：Reserved";
BA_ "SignalPosition" SG_ 901 LDW_Enable_S "7.6-7.7";
BA_ "SignalValueDescription" SG_ 901 SLA_SpdLimOffs_S "0x0：0

0x1：-10（KPH）

0x2：-5（KPH）

0x3：+5（KPH）

0x4：+10（KPH）

0x5：-5（MPH）

 0x6：-3（MPH）

0x7：+3（MPH）

0x8：+5（MPH）

0x9：Reserved

";
BA_ "SignalPosition" SG_ 901 SLA_SpdLimOffs_S "8.0-8.3";
BA_ "SignalValueDescription" SG_ 901 IntelligentSpdLimitAlarm_OnOff_S "0x0：Invalid

0x1：off

0x2：on

0x3：Reserved";
BA_ "SignalPosition" SG_ 901 IntelligentSpdLimitAlarm_OnOff_S "8.4-8.5";
BA_ "SignalValueDescription" SG_ 901 ELKA_Enable_S "0x0：Invalid

0x1：Switchoff

0x2：Switchon

0x3：Reserved";
BA_ "SignalPosition" SG_ 901 ELKA_Enable_S "8.6-8.7";
BA_ "GenSigInvalidValue" SG_ 694 Date_Information_Year_2B6_S 15;
BA_ "SignalValueDescription" SG_ 694 Date_Information_Year_2B6_S "0x0：无效

0x1-0xFF：2001年至2255年";
BA_ "SignalPosition" SG_ 694 Date_Information_Year_2B6_S "1.0-1.7";
BA_ "GenSigInvalidValue" SG_ 694 Date_Information_Month_2B6_S 15;
BA_ "SignalValueDescription" SG_ 694 Date_Information_Month_2B6_S "0x0：无效

0x1-0x0C：1-12月

0x0D-0xFF：无效";
BA_ "SignalPosition" SG_ 694 Date_Information_Month_2B6_S "2.0-2.7";
BA_ "GenSigInvalidValue" SG_ 694 Date_Information_Day_2B6_S 15;
BA_ "SignalValueDescription" SG_ 694 Date_Information_Day_2B6_S "0x0：无效

0x1-0x1F：1-31号

0x20-0xFF：无效";
BA_ "SignalPosition" SG_ 694 Date_Information_Day_2B6_S "3.0-3.7";
BA_ "GenSigInvalidValue" SG_ 694 Date_Information_Hour_2B6_S 15;
BA_ "SignalValueDescription" SG_ 694 Date_Information_Hour_2B6_S "0x0-0x17：0-23时

0x18-0xFF：无效";
BA_ "SignalPosition" SG_ 694 Date_Information_Hour_2B6_S "4.0-4.7";
BA_ "GenSigInvalidValue" SG_ 694 Date_Information_Minute_2B6_S 15;
BA_ "SignalValueDescription" SG_ 694 Date_Information_Minute_2B6_S "0x0-0x3B：0-59分

0x3C-0xFF：无效";
BA_ "SignalPosition" SG_ 694 Date_Information_Minute_2B6_S "5.0-5.7";
BA_ "GenSigInvalidValue" SG_ 694 Date_Information_Second_2B6_S 15;
BA_ "SignalValueDescription" SG_ 694 Date_Information_Second_2B6_S "0x0-0x3B：0-59秒

0x3C-0xFF：无效";
BA_ "SignalPosition" SG_ 694 Date_Information_Second_2B6_S "6.0-6.7";
BA_ "GenSigInvalidValue" SG_ 694 Week_2B6_S 15;
BA_ "SignalValueDescription" SG_ 694 Week_2B6_S "PH=INT*1

[1，7]

[0x1，0x7]

0x0：预留";
BA_ "SignalPosition" SG_ 694 Week_2B6_S "7.0-7.2";
BA_ "GenSigInvalidValue" SG_ 694 Time_2B6_S 15;
BA_ "SignalValueDescription" SG_ 694 Time_2B6_S "0x0：无效

0x1：12h

0x2：24h

0x3：预留";
BA_ "SignalPosition" SG_ 694 Time_2B6_S "7.3-7.4";
BA_ "SignalValueDescription" SG_ 995 Media_Factory_Default_S "0x0：无效

0x1：确定

0x2：取消

0x3：预留";
BA_ "SignalPosition" SG_ 995 Media_Factory_Default_S "2.0-2.1";
BA_ "SignalValueDescription" SG_ 995 SfAsist_Restr_Dflt_Log_S "0x0：无效

0x1：确认";
BA_ "SignalPosition" SG_ 995 SfAsist_Restr_Dflt_Log_S "7.7";
BA_ "SignalValueDescription" SG_ 995 Drv_Asis_St_RstrDflt_Flg_S "0x0：无效

0x1：确认";
BA_ "SignalPosition" SG_ 995 Drv_Asis_St_RstrDflt_Flg_S "8.0";
BA_ "SignalValueDescription" SG_ 995 Roa_Asis_St_RstrDflt_Flg_S "0x0：无效

0x1：确认";
BA_ "SignalPosition" SG_ 995 Roa_Asis_St_RstrDflt_Flg_S "8.1";
BA_ "SignalValueDescription" SG_ 307 Light_Knob_Mechan_Gear_S "0x0：无效

0x1：OFF档

0x2：AUTO档

0x3：小灯档

0x4：近光灯档

0x5-0x7：预留";
BA_ "SignalPosition" SG_ 307 Light_Knob_Mechan_Gear_S "4.3-4.5";
BA_ "SignalValueDescription" SG_ 307 Front_And_Rear_Fog_Lamp_Gear_S "0x0：无效

0x1：OFF档

0x2：全天候灯档

0x3：后雾灯档

初始值/默认值：0x0";
BA_ "SignalPosition" SG_ 307 Front_And_Rear_Fog_Lamp_Gear_S "1.0-1.1";
BA_ "SignalValueDescription" SG_ 307 CS_Front_Wiper_Gear_S "0x0：预留

0x1：OFF档

0x2：点刮短按

0x3：点刮长按

0x4：间隙1档

0x5：间隙2档

0x6：间隙3档

0x7：间隙4档

0x8：慢刮

0x9：快刮

0xA：AUTO档（ST/STE的间隙档位更改为Auto档）

0xB-0xF：预留";
BA_ "SignalPosition" SG_ 307 CS_Front_Wiper_Gear_S "2.0-2.3";
BA_ "SignalValueDescription" SG_ 307 High_Beam_Attendan_Lamp_Stall_S "0x0：无效

0x1：OFF档

0x2：远光灯档

0x3：超车灯档

初始值/默认值：0x0";
BA_ "SignalPosition" SG_ 307 High_Beam_Attendan_Lamp_Stall_S "4.6-4.7";
BA_ "SignalValueDescription" SG_ 307 Turn_Signal_Switch_S "0x0：无效

0x1：OFF档

0x2：左转向短抬

0x3：左转向长抬

0x4：右转向短抬

0x5：右转向长抬

0x6-0x7：预留

初始值/默认值：0x0";
BA_ "SignalPosition" SG_ 307 Turn_Signal_Switch_S "5.4-5.6";
BA_ "SignalValueDescription" SG_ 307 Loss_Cycle_Counter133_S "[0，15]";
BA_ "SignalPosition" SG_ 307 Loss_Cycle_Counter133_S "7.0-7.3";
BA_ "SignalValueDescription" SG_ 307 Checksum133_S "Checksum=(Byte1+Byte2?+Byte7)XOR0xFF";
BA_ "SignalPosition" SG_ 307 Checksum133_S "8.0-8.7";
BA_ "GenSigInvalidValue" SG_ 944 SWS_Dist_Set_S 4;
BA_ "GenSigStartValue" SG_ 944 SWS_Dist_Set_S 4;
BA_ "SignalValueDescription" SG_ 944 SWS_Dist_Set_S "0x0：一档（1s）

0x1：二档（1.5s）

0x2：三档（1.9s）

0x3：四档（2.3s）

0x4：无效

0x5-0x7：预留";
BA_ "SignalPosition" SG_ 944 SWS_Dist_Set_S "1.0-1.2";
BA_ "SignalValueDescription" SG_ 944 SWS_Speed_Set_S "0x0：初始位置

0x1：减速一档

0x2：减速二档

0x3：加速一档

0x4：加速二档

0x5-0x7：预留";
BA_ "SignalPosition" SG_ 944 SWS_Speed_Set_S "1.3-1.5";
BA_ "SignalValueDescription" SG_ 944 Dipilot_Switch_Signal_S "0x0：无效

0x1：开关按下

0x2~0x3:Reserved";
BA_ "SignalPosition" SG_ 944 Dipilot_Switch_Signal_S "1.6-1.7";
BA_ "SignalValueDescription" SG_ 944 Cruise_Or_Speed_Limit_Mode_S "0x0：限速模式

0x1：巡航模式

0x2~0x3:Reserved";
BA_ "SignalPosition" SG_ 944 Cruise_Or_Speed_Limit_Mode_S "2.0-2.1";
BA_ "SignalValueDescription" SG_ 944 SWS_Reset_Signal_S "0x0：初始位置

0x1：复位动作

0x2~0x3:Reserved";
BA_ "SignalPosition" SG_ 944 SWS_Reset_Signal_S "2.2-2.3";
BA_ "SignalValueDescription" SG_ 944 Cruis_Swch_Fault_Stat_flg_S "0x0：无效

0x1：正常

0x2~0x3:Reserved";
BA_ "SignalPosition" SG_ 944 Cruis_Swch_Fault_Stat_flg_S "2.4-2.5";
BA_ "SignalValueDescription" SG_ 944 SWS_Set_Signal_S "0x0：无效

0x1：SET开关按下";
BA_ "SignalPosition" SG_ 944 SWS_Set_Signal_S "2.6";
BA_ "SignalValueDescription" SG_ 944 Dist_Switch_Signal_Down_S "0x0：无效

0x1：距离开关按下";
BA_ "SignalPosition" SG_ 944 Dist_Switch_Signal_Down_S "2.7";
BA_ "SignalValueDescription" SG_ 944 Dist_Switch_Signal_Up_S "0x0：无效

0x1：距离开关加按下";
BA_ "SignalPosition" SG_ 944 Dist_Switch_Signal_Up_S "3.0";
BA_ "SignalValueDescription" SG_ 944 SWS_Lane_Line_Assis_S "0x0：无动作

0x1：开关按下";
BA_ "SignalPosition" SG_ 944 SWS_Lane_Line_Assis_S "3.1";
BA_ "SignalValueDescription" SG_ 944 CruiseSw_Operation_Mode_S "0x0：巡航按键在方向盘上

0x1：无巡航按键";
BA_ "SignalPosition" SG_ 944 CruiseSw_Operation_Mode_S "3.2";
BA_ "SignalValueDescription" SG_ 944 ACC_Switch_Signal_S "0x0：无效

0x1：开关按下";
BA_ "SignalPosition" SG_ 944 ACC_Switch_Signal_S "3.3";
BA_ "SignalValueDescription" SG_ 944 HOD_System_Status_S "0x0:Available 

0x1:InitialStatus

0x2:Fault 

0x3:Not Calibration

0x4~0x7：Reserved ";
BA_ "SignalPosition" SG_ 944 HOD_System_Status_S "3.4-3.6";
BA_ "SignalValueDescription" SG_ 944 Driver_Grip_S "0x0:invalid

0x1:NoHandDetected

0x2:Hand Detected

0x3~0x7：Reserved";
BA_ "SignalPosition" SG_ 944 Driver_Grip_S "4.0-4.2";
BA_ "SignalValueDescription" SG_ 944 Driver_Grip_Area_S "0x0:NoHand 

0x1:LeftHalfArea

0x2:RightHalfArea

0x3~0x7：Reserved";
BA_ "SignalPosition" SG_ 944 Driver_Grip_Area_S "4.3-4.5";
BA_ "SignalValueDescription" SG_ 944 Driver_SingleHands_State_S "0x0:NoHandsOn

0x1: One Hand

0x2: Both HandsOn

0x3~0x7：Reserved";
BA_ "SignalPosition" SG_ 944 Driver_SingleHands_State_S "5.0-5.2";
BA_ "SignalValueDescription" SG_ 944 Loss_Cycle_Counter3B0_S "[0，15]";
BA_ "SignalPosition" SG_ 944 Loss_Cycle_Counter3B0_S "7.4-7.7";
BA_ "SignalValueDescription" SG_ 944 CheckCode3B0_S "Checksum=(Byte1+Byte2…+Byte7)XOR0xFF";
BA_ "SignalPosition" SG_ 944 CheckCode3B0_S "8.0-8.7";
BA_ "SignalValueDescription" SG_ 1193 Lane_Departure_Key_S "0x0：无效

0x1：有效按下";
BA_ "SignalPosition" SG_ 1193 Lane_Departure_Key_S "2.0";
BA_ "GenSigInvalidValue" SG_ 576 Power_System_Failure_S 3;
BA_ "SignalValueDescription" SG_ 576 Power_System_Failure_S "0x0：动力系统状态正常

0x1：EV功能受限

0x2：动力系统状态故障

0x3：预留";
BA_ "SignalPosition" SG_ 576 Power_System_Failure_S "1.0-1.1";
BA_ "SignalValueDescription" SG_ 576 VCU_Goal_Road_Mode_S "0x0：无效

0x1：普通模式

0x2：草地/砂砾地/雪地

0x3：泥泞地面/车辙地

0x4：沙地

0x5-0x7：预留";
BA_ "SignalPosition" SG_ 576 VCU_Goal_Road_Mode_S "6.0-6.2";
BA_ "SignalValueDescription" SG_ 576 VCU_Practice_Road_Mode_S "0x0：无效

0x1：普通模式

0x2：草地/砂砾地/雪地

0x3：泥泞地面/车辙地

0x4：沙地

0x5-0x7：预留";
BA_ "SignalPosition" SG_ 576 VCU_Practice_Road_Mode_S "6.3-6.5";
BA_ "SignalValueDescription" SG_ 576 Checksum240_S "Checksum=(Byte1+Byte2…+Byte7)XOR0xFF";
BA_ "SignalPosition" SG_ 576 Checksum240_S "8.0-8.7";
BA_ "SignalValueDescription" SG_ 833 READY_Indicator_Light_S "0x0：不显示

0x1：显示

0x2：插枪可用高压电（伪READY）

0x3：预留";
BA_ "SignalPosition" SG_ 833 READY_Indicator_Light_S "2.0-2.1";
BA_ "SignalValueDescription" SG_ 833 Checksum341_S "Checksum=(Byte1+Byte2…+Byte7)XOR0xFF";
BA_ "SignalPosition" SG_ 833 Checksum341_S "8.0-8.7";
BA_ "SignalValueDescription" SG_ 834 VCU_Veh_Work_Mode_Switch_Stats_S "0x0：未切换

0x1：正在切换

0x2-0x3：预留";
BA_ "SignalPosition" SG_ 834 VCU_Veh_Work_Mode_Switch_Stats_S "3.6-3.7";
BA_ "SignalValueDescription" SG_ 834 Throttle_Depth_S "PH=INT*1%

[0，100]

[0x00，0x64]

初始值/默认值：0x0";
BA_ "SignalPosition" SG_ 834 Throttle_Depth_S "1.0-1.7";
BA_ "SignalValueDescription" SG_ 834 VCU_Brake_Depth_S "PH=INT*1%

[0，100]

[0x00，0x64]

初始值/默认值：0x0";
BA_ "SignalPosition" SG_ 834 VCU_Brake_Depth_S "2.0-2.7";
BA_ "GenSigStartValue" SG_ 834 Acelrogra_Dpth_Virtual_Val_S 1;
BA_ "SignalValueDescription" SG_ 834 Acelrogra_Dpth_Virtual_Val_S "0x0：无效

0x1：有效";
BA_ "SignalPosition" SG_ 834 Acelrogra_Dpth_Virtual_Val_S "3.0";
BA_ "GenSigStartValue" SG_ 834 Brake_Depth_Virtual_Value_S 1;
BA_ "SignalValueDescription" SG_ 834 Brake_Depth_Virtual_Value_S "0x0：无效

0x1：有效";
BA_ "SignalPosition" SG_ 834 Brake_Depth_Virtual_Value_S "3.1";
BA_ "GenSigInvalidValue" SG_ 834 Vehicle_Run_Mode_S 1;
BA_ "GenSigStartValue" SG_ 834 Vehicle_Run_Mode_S 1;
BA_ "SignalValueDescription" SG_ 834 Vehicle_Run_Mode_S "0x0：预留

0x1：经济模式

0x2：运动模式

0x3：普通模式（Normal）";
BA_ "SignalPosition" SG_ 834 Vehicle_Run_Mode_S "3.4-3.5";
BA_ "GenSigInvalidValue" SG_ 834 Goal_Gear_S 1;
BA_ "GenSigStartValue" SG_ 834 Goal_Gear_S 1;
BA_ "SignalValueDescription" SG_ 834 Goal_Gear_S "0x0：预留

0x1：P档

0x2：R档

0x3：N档

0x4：D档

0x5-0xF：预留";
BA_ "SignalPosition" SG_ 834 Goal_Gear_S "4.0-4.3";
BA_ "SignalValueDescription" SG_ 834 Rolling_Counter_342_S "PH∈[0，15]";
BA_ "SignalPosition" SG_ 834 Rolling_Counter_342_S "7.4-7.7";
BA_ "SignalValueDescription" SG_ 834 Checksum342_S "Checksum=(Byte1+Byte2…+Byte7)XOR0xff";
BA_ "SignalPosition" SG_ 834 Checksum342_S "8.0-8.7";
BA_ "SignalValueDescription" SG_ 578 Driver_VLC_Request_Torque_S "0x0：No Override

0x1：Driver Override";
BA_ "SignalPosition" SG_ 578 Driver_VLC_Request_Torque_S "5.1";
BA_ "SignalValueDescription" SG_ 578 Acceleration_Pedal_depth_error_S "0x0：No Error

0x1：Error

Initial/Default：0x0";
BA_ "SignalPosition" SG_ 578 Acceleration_Pedal_depth_error_S "5.4";
BA_ "GenSigStartValue" SG_ 578 VCU_Gear_S 1;
BA_ "SignalValueDescription" SG_ 578 VCU_Gear_S "0x0：Reserved

0x1：P

0x2：R

0x3：N

0x4：D

0x5-0xF：Reserved";
BA_ "SignalPosition" SG_ 578 VCU_Gear_S "6.0-6.3";
BA_ "GenSigInvalidValue" SG_ 578 VCU_Gear_Stats_S 1;
BA_ "SignalValueDescription" SG_ 578 VCU_Gear_Stats_S "0x0：Valid

0x1：Invalid";
BA_ "SignalPosition" SG_ 578 VCU_Gear_Stats_S "6.4";
BA_ "SignalValueDescription" SG_ 578 Alive_counter242_S "PH=[0，15]";
BA_ "SignalPosition" SG_ 578 Alive_counter242_S "7.4-7.7";
BA_ "SignalValueDescription" SG_ 578 Checksum242_S "Checksum=(Byte1+Byte2…+Byte7)XOR0xFF";
BA_ "SignalPosition" SG_ 578 Checksum242_S "8.0-8.7";
VAL_ 3221225472 The_Drv_Demand_Trq_Sign_S 1 "Driver Override" 0 "No Override" ;
VAL_ 692 HMA_High_Beam_Request_S 1 "HighBeam Request" 0 "LowBeam Request" ;
VAL_ 692 HMA_Stats_S 5 "Camera Blocked" 4 "Fault" 3 "Active" 2 "Standby" 1 "Passive" 0 "Off" ;
VAL_ 836 BMC_Extn_Chag_Equp_Conec_Stat_S 15 "默认值" 14 "对外放电异常结束" 13 "充电暂停（EV预留）" 12 "对外放电正常结束" 11 "对外放电中" 10 "对外放电准备就绪" 9 "预约等待（EV预留）" 8 "交流外充设备故障（EV预留）" 7 "车载对外放电等待中（EV预留）" 6 "充电枪连接故障（EV预留）" 5 "C10充电柜故障" 4 "充电终止" 3 "有枪连接，未进入流程（EV预留）" 2 "充电结束" 1 "正在充电" 0 "准备就绪" ;
VAL_ 948 Sun_Sensor_Hardware_Fault_S 1 "有故障" 0 "无故障" ;
VAL_ 948 Humidity_Sensor_Fault_Sign_S 1 "有故障" 0 "无故障" ;
VAL_ 660 Left_Front_Door_Status_294_S 3 "预留" 2 "打开" 1 "关闭" 0 "无效" ;
VAL_ 660 Right_Front_Door_Status_294_S 3 "预留" 2 "打开" 1 "关闭" 0 "无效" ;
VAL_ 660 Left_Back_Door_Status_294_S 3 "预留" 2 "打开" 1 "关闭" 0 "无效" ;
VAL_ 660 Right_Back_Door_Status_294_S 3 "预留" 2 "打开" 1 "关闭" 0 "无效" ;
VAL_ 660 LeftF_Door_Stats_Valid_Bit_S 1 "无效" 0 "有效" ;
VAL_ 660 RightF_Door_Sts_Valid_Bit_294_S 1 "无效" 0 "有效" ;
VAL_ 660 LeftR_Door_Stats_Valid_Bit_S 1 "无效" 0 "有效" ;
VAL_ 660 RightR_Door_Sts_Valid_Bit_294_S 1 "无效" 0 "有效" ;
VAL_ 660 Driver_Belt_Stat_Effective_Bit_S 1 "无效" 0 "有效" ;
VAL_ 660 Back_Door_Sts_Effectiv_Bit_294_S 1 "无效" 0 "有效" ;
VAL_ 660 Frnt_Hatch_Stat_Effective_Bit_S 1 "无效" 0 "有效" ;
VAL_ 660 Emergency_Alarm_Effective_Bit_S 1 "无效" 0 "有效" ;
VAL_ 660 Driver_Belt_Status_S 3 "预留" 2 "扣上" 1 "解开" 0 "无效" ;
VAL_ 660 Back_Door_Status_294_S 3 "预留" 2 "打开" 1 "关闭" 0 "无效" ;
VAL_ 660 Former_Hatch_Status_294_S 3 "预留" 2 "打开" 1 "关闭" 0 "无效" ;
VAL_ 660 Emergency_Alarm_Status_S 3 "预留" 2 "打开" 1 "关闭" 0 "无效" ;
VAL_ 301 BCMPower_Gear_12D_S 3 "ON档" 2 "ACC档" 1 "OFF档" 0 "无效" ;
VAL_ 1141 Wiper_Speed_S 3 "快刮" 2 "慢刮" 1 "停止" 0 "无效" ;
VAL_ 985 Child_ID_3D9_S 1 "子ID01" ;
VAL_ 1189 Mileage_Unit_4A5_S 3 "预留" 2 "mile" 1 "km" 0 "无效" ;
VAL_ 337 Speed_Unit_Setting_151_S 3 "预留" 2 "MPH" 1 "Km/h" 0 "无效" ;
VAL_ 803 INS_Show_Fault_323_S 1 "故障" 0 "正常" ;
VAL_ 1028 Temperature_Conversion_S 1 "华氏设定温度" 0 "摄氏设定温度" ;
VAL_ 536 EPB_Switch_Status_S 3 "Reserved" 2 "Apply" 1 "Release" 0 "Not Active" ;
VAL_ 536 EPB_Status_S 5 "维修释放状态" 4 "Fault（禁止遥控驾驶）" 3 "Applied" 2 "Applying" 1 "Released" 0 "Releasing" ;
VAL_ 536 DrvOrOthFcnReqEPBOverride_S 1 "True" 0 "False" ;
VAL_ 901 RCTA_Enable_S 3 "Reserved" 2 "Switchon" 1 "Switchoff" 0 "Invalid" ;
VAL_ 901 RCW_Enable_S 3 "Reserved" 2 "Switchon" 1 "Switchoff" 0 "Invalid" ;
VAL_ 901 DOW_Enable_S 3 "Reserved" 2 "Switchon" 1 "Switchoff" 0 "Invalid" ;
VAL_ 901 TJA_ICAwitch_S 3 "Reserved" 2 "Switchon" 1 "Switchoff" 0 "Invalid" ;
VAL_ 901 RCTB_Enable_S 3 "Reserved" 2 "Switchon" 1 "Switchoff" 0 "Invalid" ;
VAL_ 901 HMA_funtion_Swch_Signal_S 3 "Reserved" 2 "HMAselected" 1 "HMAnotselected" 0 "Invalid" ;
VAL_ 901 SLASwitch_Traffic_Sign_S 3 "Reserved" 2 "on" 1 "off" 0 "Invalid" ;
VAL_ 901 ADAS_Sensitivity_Req_S 3 "Reserved" 2 "highSensitivity" 1 "lowSensitivity" 0 "Invalid" ;
VAL_ 901 PCW_Enable_S 3 "Reserved" 2 "Switchon" 1 "Switchoff" 0 "Invalid" ;
VAL_ 901 LKS_Enable_S 5 "车辆纠偏" 4 "全功能" 3 "车道保持" 2 "车道偏离" 1 "关闭" 0 "无效" ;
VAL_ 901 AEB_Enable_S 3 "Reserved" 2 "switchon" 1 "switchoff" 0 "Invalid" ;
VAL_ 901 LDW_Warning_Mode_S 3 "振动+声音" 2 "仅声音" 1 "仅振动" 0 "无效" ;
VAL_ 901 LDW_Static_Calib_Instrct_S 1 "开始" 0 "无效" ;
VAL_ 901 SDWReq_Switch_State_S 3 "Reserved" 2 "Switchon" 1 "Switchoff" 0 "Invalid" ;
VAL_ 901 PCW_Level_Set_S 3 "Level 3 高" 2 "Level 2 中(默认选择)" 1 "Level 1 低" 0 "No Action" ;
VAL_ 901 LDW_Enable_S 3 "Reserved" 2 "车道偏离" 1 "关闭" 0 "无效" ;
VAL_ 901 SLA_SpdLimOffs_S 9 "Reserved" 8 "+5（MPH）" 7 "+3（MPH）" 5 "-5（MPH）" 4 "+10（KPH）" 3 "+5（KPH）" 2 "-5（KPH）" 1 "-10（KPH）" 0 "0" ;
VAL_ 901 IntelligentSpdLimitAlarm_OnOff_S 3 "Reserved" 2 "on" 1 "off" 0 "Invalid" ;
VAL_ 901 ELKA_Enable_S 3 "Reserved" 2 "Switchon" 1 "Switchoff" 0 "Invalid" ;
VAL_ 694 Date_Information_Year_2B6_S 0 "无效" ;
VAL_ 694 Date_Information_Month_2B6_S 0 "无效" ;
VAL_ 694 Date_Information_Day_2B6_S 0 "无效" ;
VAL_ 694 Time_2B6_S 3 "预留" 2 "24h" 1 "12h" 0 "无效" ;
VAL_ 995 Media_Factory_Default_S 3 "预留" 2 "取消" 1 "确定" 0 "无效" ;
VAL_ 995 SfAsist_Restr_Dflt_Log_S 1 "确认" 0 "无效" ;
VAL_ 995 Drv_Asis_St_RstrDflt_Flg_S 1 "确认" 0 "无效" ;
VAL_ 995 Roa_Asis_St_RstrDflt_Flg_S 1 "确认" 0 "无效" ;
VAL_ 307 Light_Knob_Mechan_Gear_S 4 "近光灯档" 3 "小灯档" 2 "AUTO档" 1 "OFF档" 0 "无效" ;
VAL_ 307 Front_And_Rear_Fog_Lamp_Gear_S 3 "后雾灯档" 2 "全天候灯档" 1 "OFF档" 0 "无效" ;
VAL_ 307 CS_Front_Wiper_Gear_S 10 "AUTO档（ST/STE的间隙档位更改为Auto档）" 9 "快刮" 8 "慢刮" 7 "间隙4档" 6 "间隙3档" 5 "间隙2档" 4 "间隙1档" 3 "点刮长按" 2 "点刮短按" 1 "OFF档" 0 "预留" ;
VAL_ 307 High_Beam_Attendan_Lamp_Stall_S 3 "超车灯档" 2 "远光灯档" 1 "OFF档" 0 "无效" ;
VAL_ 307 Turn_Signal_Switch_S 5 "右转向长抬" 4 "右转向短抬" 3 "左转向长抬" 2 "左转向短抬" 1 "OFF档" 0 "无效" ;
VAL_ 944 SWS_Dist_Set_S 4 "无效" 3 "四档（2.3s）" 2 "三档（1.9s）" 1 "二档（1.5s）" 0 "一档（1s）" ;
VAL_ 944 SWS_Speed_Set_S 4 "加速二档" 3 "加速一档" 2 "减速二档" 1 "减速一档" 0 "初始位置" ;
VAL_ 944 Dipilot_Switch_Signal_S 1 "开关按下" 0 "无效" ;
VAL_ 944 Cruise_Or_Speed_Limit_Mode_S 1 "巡航模式" 0 "限速模式" ;
VAL_ 944 SWS_Reset_Signal_S 1 "复位动作" 0 "初始位置" ;
VAL_ 944 Cruis_Swch_Fault_Stat_flg_S 1 "正常" 0 "无效" ;
VAL_ 944 SWS_Set_Signal_S 1 "SET开关按下" 0 "无效" ;
VAL_ 944 Dist_Switch_Signal_Down_S 1 "距离开关按下" 0 "无效" ;
VAL_ 944 Dist_Switch_Signal_Up_S 1 "距离开关加按下" 0 "无效" ;
VAL_ 944 SWS_Lane_Line_Assis_S 1 "开关按下" 0 "无动作" ;
VAL_ 944 CruiseSw_Operation_Mode_S 1 "无巡航按键" 0 "巡航按键在方向盘上" ;
VAL_ 944 ACC_Switch_Signal_S 1 "开关按下" 0 "无效" ;
VAL_ 944 HOD_System_Status_S 3 "Not Calibration" 2 "Fault " 1 "InitialStatus" 0 "Available " ;
VAL_ 944 Driver_Grip_S 2 "Hand Detected" 1 "NoHandDetected" 0 "invalid" ;
VAL_ 944 Driver_Grip_Area_S 2 "RightHalfArea" 1 "LeftHalfArea" 0 "NoHand " ;
VAL_ 944 Driver_SingleHands_State_S 2 " Both HandsOn" 1 " One Hand" 0 "NoHandsOn" ;
VAL_ 1193 Lane_Departure_Key_S 1 "有效按下" 0 "无效" ;
VAL_ 576 Power_System_Failure_S 3 "预留" 2 "动力系统状态故障" 1 "EV功能受限" 0 "动力系统状态正常" ;
VAL_ 576 VCU_Goal_Road_Mode_S 4 "沙地" 3 "泥泞地面/车辙地" 2 "草地/砂砾地/雪地" 1 "普通模式" 0 "无效" ;
VAL_ 576 VCU_Practice_Road_Mode_S 4 "沙地" 3 "泥泞地面/车辙地" 2 "草地/砂砾地/雪地" 1 "普通模式" 0 "无效" ;
VAL_ 833 READY_Indicator_Light_S 3 "预留" 2 "插枪可用高压电（伪READY）" 1 "显示" 0 "不显示" ;
VAL_ 834 VCU_Veh_Work_Mode_Switch_Stats_S 1 "正在切换" 0 "未切换" ;
VAL_ 834 Acelrogra_Dpth_Virtual_Val_S 1 "有效" 0 "无效" ;
VAL_ 834 Brake_Depth_Virtual_Value_S 1 "有效" 0 "无效" ;
VAL_ 834 Vehicle_Run_Mode_S 3 "普通模式（Normal）" 2 "运动模式" 1 "经济模式" 0 "预留" ;
VAL_ 834 Goal_Gear_S 4 "D档" 3 "N档" 2 "R档" 1 "P档" 0 "预留" ;
VAL_ 578 Driver_VLC_Request_Torque_S 1 "Driver Override" 0 "No Override" ;
VAL_ 578 Acceleration_Pedal_depth_error_S 1 "Error" 0 "No Error" ;
VAL_ 578 VCU_Gear_S 4 "D" 3 "N" 2 "R" 1 "P" 0 "Reserved" ;
VAL_ 578 VCU_Gear_Stats_S 1 "Invalid" 0 "Valid" ;
